VERSION "ZCU_CANFD1"

NS_ :

BS_ :

BU_ :  ASDM BBM ETC IHU ZCUD ZCUP

BO_ 1570 ZcudWpcToDhuZCUCANFD1DiagResFr : 64 ZCUD

BO_ 1554 ZcudXcuToDhuZCUCANFD1DiagResFr : 64 ZCUD

BO_ 97 ZcudZCUCANFD1Fr01 : 64 ZCUD
 SG_ ActvnOfWelcomeLi : 463|1@0+ (1,0) [0|1] "" IHU,ZCUP
 SG_ ActvnOfWelcomeLi_UB : 462|1@0+ (1,0) [0|1] "" IHU,ZCUP
 SG_ ADataRawSafe_UB : 72|1@0+ (1,0) [0|1] "" ASDM,BBM
 SG_ ADataRawSafeALat : 119|15@0- (0.0085,0.0) [-138.99200000000002|139.00050000000002] "m/s^2" ASDM,BBM
 SG_ ADataRawSafeALat1Qf : 135|2@0+ (1,0) [0|3] "" ASDM,BBM
 SG_ ADataRawSafeALgt : 151|15@0- (0.0085,0.0) [-138.99200000000002|139.00050000000002] "m/s^2" ASDM,BBM
 SG_ ADataRawSafeALgt1Qf : 133|2@0+ (1,0) [0|3] "" ASDM,BBM
 SG_ ADataRawSafeAVert : 167|15@0- (0.0085,0.0) [-138.99200000000002|139.00050000000002] "m/s^2" ASDM,BBM
 SG_ ADataRawSafeAVertQf : 183|2@0+ (1,0) [0|3] "" ASDM,BBM
 SG_ ADataRawSafeChks : 143|8@0+ (1.0,0.0) [0.0|255.0] "Unitless" ASDM,BBM
 SG_ ADataRawSafeCntr : 131|4@0+ (1.0,0.0) [0.0|15.0] "Unitless" ASDM,BBM
 SG_ ADModCtrlInhbn_UB : 176|1@0+ (1,0) [0|1] "" ASDM,IHU
 SG_ ADModCtrlInhbnADModCtrlInhbn : 195|3@0+ (1,0) [0|7] "" ASDM,IHU
 SG_ ADModCtrlInhbnChks : 191|8@0+ (1.0,0.0) [0.0|255.0] "Unitless" ASDM,IHU
 SG_ ADModCtrlInhbnCntr : 199|4@0+ (1.0,0.0) [0.0|15.0] "Unitless" ASDM,IHU
 SG_ AgDataRaw2Safe_UB : 181|1@0+ (1,0) [0|1] "" IHU
 SG_ AgDataRaw2SafeChks : 207|8@0+ (1.0,0.0) [0.0|255.0] "Unitless" IHU
 SG_ AgDataRaw2SafeCntr : 231|4@0+ (1.0,0.0) [0.0|15.0] "Unitless" IHU
 SG_ AgDataRaw2SafePitchRate : 215|16@0- (0.000244140625,0.0) [-6.0|6.0] "rad/s" IHU
 SG_ AgDataRaw2SafePitchRateQf : 227|2@0+ (1,0) [0|3] "" IHU
 SG_ AgDataRawSafe_UB : 180|1@0+ (1,0) [0|1] "" ASDM,BBM,IHU
 SG_ AgDataRawSafeChks : 239|8@0+ (1.0,0.0) [0.0|255.0] "Unitless" ASDM,BBM,IHU
 SG_ AgDataRawSafeCntr : 247|4@0+ (1.0,0.0) [0.0|15.0] "Unitless" ASDM,BBM,IHU
 SG_ AgDataRawSafeRollRate : 255|16@0- (0.000244140625,0.0) [-6.0|6.0] "rad/s" ASDM,BBM,IHU
 SG_ AgDataRawSafeRollRateQf : 243|2@0+ (1,0) [0|3] "" ASDM,BBM,IHU
 SG_ AgDataRawSafeYawRate : 271|16@0- (0.000244140625,0.0) [-6.0|6.0] "rad/s" ASDM,BBM,IHU
 SG_ AgDataRawSafeYawRateQf : 241|2@0+ (1,0) [0|3] "" ASDM,BBM,IHU
 SG_ AmbTRaw_UB : 179|1@0+ (1,0) [0|1] "" ASDM,BBM,IHU,ZCUP
 SG_ AmbTRawAmbTVal : 287|11@0+ (0.1,-70.0) [-70.0|134.70000000000002] "degC" ASDM,BBM,IHU,ZCUP
 SG_ AmbTRawQly : 292|2@0+ (1,0) [0|3] "" ASDM,BBM,IHU,ZCUP
 SG_ AsyDataWithCmpSafe_UB : 178|1@0+ (1,0) [0|1] "" ASDM,BBM,IHU
 SG_ AsyDataWithCmpSafeALat1Qf : 303|2@0+ (1,0) [0|3] "" ASDM,BBM,IHU
 SG_ AsyDataWithCmpSafeALatWithCmp : 351|15@0- (0.0085,0.0) [-138.99200000000002|139.00050000000002] "m/s^2" ASDM,BBM,IHU
 SG_ AsyDataWithCmpSafeALgt1Qf : 301|2@0+ (1,0) [0|3] "" ASDM,BBM,IHU
 SG_ AsyDataWithCmpSafeChks : 311|8@0+ (1.0,0.0) [0.0|255.0] "Unitless" ASDM,BBM,IHU
 SG_ AsyDataWithCmpSafeCntr : 299|4@0+ (1.0,0.0) [0.0|15.0] "Unitless" ASDM,BBM,IHU
 SG_ AsyDataWithCmpSafeGrdtOfALgt : 335|14@0- (0.00390625,0.0) [-30.0|30.0] "m/s^3" ASDM,BBM,IHU
 SG_ AsyDataWithCmpSafeYawRateQf : 337|2@0+ (1,0) [0|3] "" ASDM,BBM,IHU
 SG_ AsyDataWithCmpSafeYawRateWithCmp : 319|16@0- (0.000244140625,0.0) [-6.0|6.0] "rad/s" ASDM,BBM,IHU
 SG_ BodyHei : 63|15@0- (0.000062,0.0) [-0.999998|1.00006] "m" Vector__XXX
 SG_ BodyHei_UB : 64|1@0+ (1,0) [0|1] "" Vector__XXX
 SG_ BrkPedlSnsr_UB : 177|1@0+ (1,0) [0|1] "" IHU
 SG_ BrkPedlSnsrChks : 383|8@0+ (1.0,0.0) [0.0|255.0] "Unitless" IHU
 SG_ BrkPedlSnsrCntr : 391|4@0+ (1.0,0.0) [0.0|15.0] "Unitless" IHU
 SG_ BrkPedlSnsrQf : 387|2@0+ (1,0) [0|3] "" IHU
 SG_ BrkPedlSnsrSt : 385|2@0+ (1,0) [0|3] "" IHU
 SG_ BrkPedlSts : 225|1@0+ (1,0) [0|1] "" BBM,IHU
 SG_ BrkPedlSts_UB : 224|1@0+ (1,0) [0|1] "" BBM,IHU
 SG_ CarTiGlb : 399|32@0+ (0.1,0.0) [0.0|429496729.5] "s" ASDM,BBM,IHU,ZCUP
 SG_ CarTiGlb_UB : 192|1@0+ (1,0) [0|1] "" ASDM,BBM,IHU,ZCUP
 SG_ CrsCtrlOvrdn : 107|1@0+ (1,0) [0|1] "" ASDM,IHU
 SG_ CrsCtrlOvrdn_UB : 106|1@0+ (1,0) [0|1] "" ASDM,IHU
 SG_ CrsCtrlrMsg : 3|3@0+ (1,0) [0|7] "" IHU
 SG_ CrsCtrlrMsg_UB : 0|1@0+ (1,0) [0|1] "" IHU
 SG_ CrsCtrlrStbOk : 105|1@0+ (1,0) [0|1] "" IHU
 SG_ CrsCtrlrStbOk_UB : 104|1@0+ (1,0) [0|1] "" IHU
 SG_ CrsCtrlrSts : 7|3@0+ (1,0) [0|7] "" ASDM,IHU
 SG_ CrsCtrlrSts_UB : 4|1@0+ (1,0) [0|1] "" ASDM,IHU
 SG_ DmcStsRearToEsc_UB : 74|1@0+ (1,0) [0|1] "" Vector__XXX
 SG_ DmcStsRearToEscChks : 15|8@0+ (1.0,0.0) [0.0|255.0] "Unitless" Vector__XXX
 SG_ DmcStsRearToEscCntr : 23|4@0+ (1.0,0.0) [0.0|15.0] "Unitless" Vector__XXX
 SG_ DmcStsRearToEscDmcActAppTarTq : 31|16@0- (1.0,0.0) [-30000.0|30000.0] "NewtonMeter" Vector__XXX
 SG_ DmcStsRearToEscDmcSts : 19|4@0+ (1,0) [0|15] "" Vector__XXX
 SG_ DmcStsRearToEscDmcSWInfo : 47|16@0+ (1.0,0.0) [0.0|65535.0] "Unitless" Vector__XXX
 SG_ DoorDrvrLockCmd : 461|4@0+ (1,0) [0|15] "" IHU,ZCUP
 SG_ DoorDrvrLockCmd_UB : 457|1@0+ (1,0) [0|1] "" IHU,ZCUP
 SG_ DrvrDesDir_UB : 480|1@0+ (1,0) [0|1] "" ASDM,IHU
 SG_ DrvrDesDirChks : 479|8@0+ (1.0,0.0) [0.0|255.0] "Unitless" ASDM,IHU
 SG_ DrvrDesDirCntr : 487|4@0+ (1.0,0.0) [0.0|15.0] "Unitless" ASDM,IHU
 SG_ DrvrDesDirDrvrDesDir : 483|3@0+ (1,0) [0|7] "" ASDM,IHU
 SG_ DrvrGearShiftDirReq1_UB : 290|1@0+ (1,0) [0|1] "" Vector__XXX
 SG_ DrvrGearShiftDirReq1Chks : 375|8@0+ (1.0,0.0) [0.0|255.0] "Unitless" Vector__XXX
 SG_ DrvrGearShiftDirReq1Cntr : 363|4@0+ (1.0,0.0) [0.0|15.0] "Unitless" Vector__XXX
 SG_ DrvrGearShiftDirReq1DwnDwnTipAut : 364|1@0+ (1,0) [0|1] "" Vector__XXX
 SG_ DrvrGearShiftDirReq1DwnTipAut : 365|1@0+ (1,0) [0|1] "" Vector__XXX
 SG_ DrvrGearShiftDirReq1PosnAut : 366|1@0+ (1,0) [0|1] "" Vector__XXX
 SG_ DrvrGearShiftDirReq1UpTipAut : 367|1@0+ (1,0) [0|1] "" Vector__XXX
 SG_ DrvrGearShiftDirReq1UpUpTipAut : 352|1@0+ (1,0) [0|1] "" Vector__XXX
 SG_ DrvrGearShiftDirReq2_UB : 289|1@0+ (1,0) [0|1] "" Vector__XXX
 SG_ DrvrGearShiftDirReq2Chks : 455|8@0+ (1.0,0.0) [0.0|255.0] "Unitless" Vector__XXX
 SG_ DrvrGearShiftDirReq2Cntr : 443|4@0+ (1.0,0.0) [0.0|15.0] "Unitless" Vector__XXX
 SG_ DrvrGearShiftDirReq2DwnDwnTipAut : 444|1@0+ (1,0) [0|1] "" Vector__XXX
 SG_ DrvrGearShiftDirReq2DwnTipAut : 445|1@0+ (1,0) [0|1] "" Vector__XXX
 SG_ DrvrGearShiftDirReq2PosnAut : 446|1@0+ (1,0) [0|1] "" Vector__XXX
 SG_ DrvrGearShiftDirReq2UpTipAut : 447|1@0+ (1,0) [0|1] "" Vector__XXX
 SG_ DrvrGearShiftDirReq2UpUpTipAut : 432|1@0+ (1,0) [0|1] "" Vector__XXX
 SG_ EpbActrStSec : 471|3@0+ (1,0) [0|7] "" IHU
 SG_ EpbActrStSec_UB : 456|1@0+ (1,0) [0|1] "" IHU
 SG_ ExtrLiRlyPwrDwn : 468|1@0+ (1,0) [0|1] "" Vector__XXX
 SG_ ExtrLiRlyPwrDwn_UB : 467|1@0+ (1,0) [0|1] "" Vector__XXX
 SG_ GearMovmtFlg : 465|2@0+ (1,0) [0|3] "" IHU
 SG_ GearMovmtFlg_UB : 466|1@0+ (1,0) [0|1] "" IHU
 SG_ WhlMotSysModSts : 79|4@0+ (1,0) [0|15] "" IHU
 SG_ WhlMotSysModSts_UB : 75|1@0+ (1,0) [0|1] "" IHU
 SG_ WhlMotSysTqEst_UB : 73|1@0+ (1,0) [0|1] "" Vector__XXX
 SG_ WhlMotSysTqEstChks : 87|8@0+ (1.0,0.0) [0.0|255.0] "Unitless" Vector__XXX
 SG_ WhlMotSysTqEstCntr : 111|4@0+ (1.0,0.0) [0.0|15.0] "Unitless" Vector__XXX
 SG_ WhlMotSysTqEstIsgTqAct : 95|14@0+ (1.0,-8188.0) [-8188.0|8192.0] "NewtonMeter" Vector__XXX
 SG_ WhlMotSysTqEstQualityFactor : 97|2@0+ (1,0) [0|3] "" Vector__XXX

BO_ 261 ZcudZCUCANFD1Fr02 : 64 ZCUD
 SG_ ActvnStsOfRtrctrRvsbLe : 27|1@0+ (1,0) [0|1] "" Vector__XXX
 SG_ ActvnStsOfRtrctrRvsbLe_UB : 26|1@0+ (1,0) [0|1] "" Vector__XXX
 SG_ AlrmSts_UB : 14|1@0+ (1,0) [0|1] "" ASDM,IHU
 SG_ AlrmStsAlrmFailr : 1|1@0+ (1,0) [0|1] "" ASDM,IHU
 SG_ AlrmStsAlrmSt : 3|2@0+ (1,0) [0|3] "" ASDM,IHU
 SG_ AlrmStsAlrmTrgSrc : 7|4@0+ (1,0) [0|15] "" ASDM,IHU
 SG_ AlrmStsSnsrInclnFailr : 0|1@0+ (1,0) [0|1] "" ASDM,IHU
 SG_ AlrmStsSnsrIntrScanrFailr : 15|1@0+ (1,0) [0|1] "" ASDM,IHU
 SG_ BltLockStSafeAtDrvr_UB : 31|1@0+ (1,0) [0|1] "" IHU
 SG_ BltLockStSafeAtDrvrBltLockSt1 : 13|1@0+ (1,0) [0|1] "" IHU
 SG_ BltLockStSafeAtDrvrBltLockStErrSts : 12|1@0+ (1,0) [0|1] "" IHU
 SG_ BltLockStSafeAtDrvrChks : 23|8@0+ (1.0,0.0) [0.0|255.0] "Unitless" IHU
 SG_ BltLockStSafeAtDrvrCntr : 11|4@0+ (1.0,0.0) [0.0|15.0] "Unitless" IHU
 SG_ BrkPedlVal_UB : 88|1@0+ (1,0) [0|1] "" BBM,IHU
 SG_ BrkPedlValBrkPedlVal : 87|15@0+ (0.00390625,0.0) [0.0|100.0] "%" BBM,IHU
 SG_ BrkPedlValQf : 73|2@0+ (1,0) [0|3] "" BBM,IHU
 SG_ DoorDrvrSts : 75|2@0+ (1,0) [0|3] "" ASDM,BBM,IHU,ZCUP
 SG_ DoorDrvrSts_UB : 76|1@0+ (1,0) [0|1] "" ASDM,BBM,IHU,ZCUP
 SG_ DoorDrvrStsWithFacQly_UB : 99|1@0+ (1,0) [0|1] "" ASDM,BBM,IHU
 SG_ DoorDrvrStsWithFacQlyDoorSts : 103|2@0+ (1,0) [0|3] "" ASDM,BBM,IHU
 SG_ DoorDrvrStsWithFacQlyFacQly : 101|2@0+ (1,0) [0|3] "" ASDM,BBM,IHU
 SG_ DoorLeReSts : 119|2@0+ (1,0) [0|3] "" ASDM,BBM,IHU,ZCUP
 SG_ DoorLeReSts_UB : 117|1@0+ (1,0) [0|1] "" ASDM,BBM,IHU,ZCUP
 SG_ DoorPassSts : 115|2@0+ (1,0) [0|3] "" ASDM,BBM,IHU,ZCUP
 SG_ DoorPassSts_UB : 116|1@0+ (1,0) [0|1] "" ASDM,BBM,IHU,ZCUP
 SG_ DoorRiReSts : 113|2@0+ (1,0) [0|3] "" ASDM,BBM,IHU,ZCUP
 SG_ DoorRiReSts_UB : 104|1@0+ (1,0) [0|1] "" ASDM,BBM,IHU,ZCUP
 SG_ DrvrPrsntSts_UB : 143|1@0+ (1,0) [0|1] "" ASDM,BBM,IHU
 SG_ DrvrPrsntStsDrvrPrsnt : 127|2@0+ (1,0) [0|3] "" ASDM,BBM,IHU
 SG_ DrvrPrsntStsDrvrPrsntChks : 135|8@0+ (1.0,0.0) [0.0|255.0] "Unitless" ASDM,BBM,IHU
 SG_ DrvrPrsntStsDrvrPrsntCntr : 123|4@0+ (1.0,0.0) [0.0|15.0] "Unitless" ASDM,BBM,IHU
 SG_ DrvrPrsntStsDrvrPrsntQf : 125|2@0+ (1,0) [0|3] "" ASDM,BBM,IHU
 SG_ GearLvrIndcn : 55|3@0+ (1,0) [0|7] "" ASDM
 SG_ GearLvrIndcn_UB : 52|1@0+ (1,0) [0|1] "" ASDM
 SG_ GearMov : 51|2@0+ (1,0) [0|3] "" IHU
 SG_ GearMov_UB : 98|1@0+ (1,0) [0|1] "" IHU
 SG_ HoodSts : 63|2@0+ (1,0) [0|3] "" ASDM,IHU
 SG_ HoodSts_UB : 61|1@0+ (1,0) [0|1] "" ASDM,IHU
 SG_ IndcrDisp : 327|2@0+ (1,0) [0|3] "" IHU
 SG_ IndcrDisp_UB : 325|1@0+ (1,0) [0|1] "" IHU
 SG_ IndcrSts : 79|2@0+ (1,0) [0|3] "" IHU,ZCUP
 SG_ IndcrSts_UB : 77|1@0+ (1,0) [0|1] "" IHU,ZCUP
 SG_ LockgCenSts_UB : 97|1@0+ (1,0) [0|1] "" IHU,ZCUP
 SG_ LockgCenStsLockSt : 107|2@0+ (1,0) [0|3] "" IHU,ZCUP
 SG_ LockgCenStsTrigSrc : 111|4@0+ (1,0) [0|15] "" IHU,ZCUP
 SG_ LockgCenStsUpdEve : 105|1@0+ (1,0) [0|1] "" IHU,ZCUP
 SG_ LvlgDirMovmtIndcr : 71|2@0+ (1,0) [0|3] "" Vector__XXX
 SG_ LvlgDirMovmtIndcr_UB : 60|1@0+ (1,0) [0|1] "" Vector__XXX
 SG_ MirrFoldStsAtDrvr : 379|3@0+ (1,0) [0|7] "" IHU
 SG_ MirrFoldStsAtDrvr_UB : 376|1@0+ (1,0) [0|1] "" IHU
 SG_ PtBrkTq_UB : 296|1@0+ (1,0) [0|1] "" ASDM,IHU
 SG_ PtBrkTqActTot : 247|15@0- (1.0,0.0) [-16384.0|16380.0] "NewtonMeter" ASDM,IHU
 SG_ PtBrkTqActTotQf : 267|2@0+ (1,0) [0|3] "" ASDM,IHU
 SG_ PtBrkTqChks : 263|8@0+ (1.0,0.0) [0.0|255.0] "Unitless" ASDM,IHU
 SG_ PtBrkTqCntr : 271|4@0+ (1.0,0.0) [0.0|15.0] "Unitless" ASDM,IHU
 SG_ PtBrkTqQf : 265|2@0+ (1,0) [0|3] "" ASDM,IHU
 SG_ PtBrkTqReqForBrkSys : 279|15@0- (1.0,0.0) [-16384.0|16380.0] "NewtonMeter" ASDM,IHU
 SG_ PtBrkTqRgnAtAxleReAct : 295|15@0- (1.0,0.0) [-16384.0|16380.0] "NewtonMeter" ASDM,IHU
 SG_ RecOfPostImpctBrkgCfmd_UB : 313|1@0+ (1,0) [0|1] "" BBM,IHU
 SG_ RecOfPostImpctBrkgCfmdChks : 335|8@0+ (1.0,0.0) [0.0|255.0] "Unitless" BBM,IHU
 SG_ RecOfPostImpctBrkgCfmdCntr : 343|4@0+ (1.0,0.0) [0.0|15.0] "Unitless" BBM,IHU
 SG_ RecOfPostImpctBrkgCfmdCrashFrnt : 339|2@0+ (1,0) [0|3] "" BBM,IHU
 SG_ RecOfPostImpctBrkgCfmdCrashLargeAnimal : 337|2@0+ (1,0) [0|3] "" BBM,IHU
 SG_ RecOfPostImpctBrkgCfmdCrashOffroadA : 351|2@0+ (1,0) [0|3] "" BBM,IHU
 SG_ RecOfPostImpctBrkgCfmdCrashOffroadD : 349|2@0+ (1,0) [0|3] "" BBM,IHU
 SG_ RecOfPostImpctBrkgCfmdCrashOffroadRT : 347|2@0+ (1,0) [0|3] "" BBM,IHU
 SG_ RecOfPostImpctBrkgCfmdCrashOffroadRTsevere : 345|2@0+ (1,0) [0|3] "" BBM,IHU
 SG_ RecOfPostImpctBrkgCfmdCrashOz : 359|2@0+ (1,0) [0|3] "" BBM,IHU
 SG_ RecOfPostImpctBrkgCfmdCrashPed : 357|2@0+ (1,0) [0|3] "" BBM,IHU
 SG_ RecOfPostImpctBrkgCfmdCrashRe : 355|2@0+ (1,0) [0|3] "" BBM,IHU
 SG_ RecOfPostImpctBrkgCfmdCrashRollovr : 353|2@0+ (1,0) [0|3] "" BBM,IHU
 SG_ RecOfPostImpctBrkgCfmdCrashSideLe : 367|2@0+ (1,0) [0|3] "" BBM,IHU
 SG_ RecOfPostImpctBrkgCfmdCrashSideRi : 365|2@0+ (1,0) [0|3] "" BBM,IHU
 SG_ RecOfPostImpctBrkgCfmdPostImpctBrkgCfmd : 363|2@0+ (1,0) [0|3] "" BBM,IHU
 SG_ StsForRtrctrRvsbLe : 67|2@0+ (1,0) [0|3] "" Vector__XXX
 SG_ StsForRtrctrRvsbLe_UB : 69|1@0+ (1,0) [0|1] "" Vector__XXX
 SG_ SunRoofPosnSts : 324|5@0+ (1,0) [0|31] "" IHU,ZCUP
 SG_ SunRoofPosnSts_UB : 312|1@0+ (1,0) [0|1] "" IHU,ZCUP
 SG_ SuspHeiLvlIndcn : 58|3@0+ (1,0) [0|7] "" Vector__XXX
 SG_ SuspHeiLvlIndcn_UB : 59|1@0+ (1,0) [0|1] "" Vector__XXX
 SG_ TrsmParkLockd_UB : 314|1@0+ (1,0) [0|1] "" ZCUP
 SG_ TrsmParkLockdChks : 375|8@0+ (1.0,0.0) [0.0|255.0] "Unitless" ZCUP
 SG_ TrsmParkLockdCntr : 383|4@0+ (1.0,0.0) [0.0|15.0] "Unitless" ZCUP
 SG_ TrsmParkLockdTrsmParkLockd : 361|2@0+ (1,0) [0|3] "" ZCUP
 SG_ TrSts : 141|2@0+ (1,0) [0|3] "" ASDM,BBM,IHU,ZCUP
 SG_ TrSts_UB : 142|1@0+ (1,0) [0|1] "" ASDM,BBM,IHU,ZCUP
 SG_ WhlMotSysLimnIndcn : 39|16@0+ (1.0,0.0) [0.0|65535.0] "Unitless" Vector__XXX
 SG_ WhlMotSysLimnIndcn_UB : 28|1@0+ (1,0) [0|1] "" Vector__XXX

BO_ 851 ZcudZCUCANFD1Fr03 : 64 ZCUD
 SG_ BltLockStAtRowSecLe_UB : 2|1@0+ (1,0) [0|1] "" BBM,IHU,ZCUP
 SG_ BltLockStAtRowSecLeBltLockEquid : 7|1@0+ (1,0) [0|1] "" BBM,IHU,ZCUP
 SG_ BltLockStAtRowSecLeBltLockSt1 : 6|1@0+ (1,0) [0|1] "" BBM,IHU,ZCUP
 SG_ BltLockStAtRowSecLeBltLockSts : 5|1@0+ (1,0) [0|1] "" BBM,IHU,ZCUP
 SG_ BltLockStAtRowSecMid_UB : 0|1@0+ (1,0) [0|1] "" BBM,IHU,ZCUP
 SG_ BltLockStAtRowSecMidBltLockEquid : 15|1@0+ (1,0) [0|1] "" BBM,IHU,ZCUP
 SG_ BltLockStAtRowSecMidBltLockSt1 : 14|1@0+ (1,0) [0|1] "" BBM,IHU,ZCUP
 SG_ BltLockStAtRowSecMidBltLockSts : 13|1@0+ (1,0) [0|1] "" BBM,IHU,ZCUP
 SG_ BltLockStAtRowSecRi_UB : 1|1@0+ (1,0) [0|1] "" BBM,IHU,ZCUP
 SG_ BltLockStAtRowSecRiBltLockEquid : 12|1@0+ (1,0) [0|1] "" BBM,IHU,ZCUP
 SG_ BltLockStAtRowSecRiBltLockSt1 : 11|1@0+ (1,0) [0|1] "" BBM,IHU,ZCUP
 SG_ BltLockStAtRowSecRiBltLockSts : 10|1@0+ (1,0) [0|1] "" BBM,IHU,ZCUP
 SG_ BltLockStAtRowThrdLe_UB : 8|1@0+ (1,0) [0|1] "" BBM,IHU,ZCUP
 SG_ BltLockStAtRowThrdLeBltLockEquid : 23|1@0+ (1,0) [0|1] "" BBM,IHU,ZCUP
 SG_ BltLockStAtRowThrdLeBltLockSt1 : 22|1@0+ (1,0) [0|1] "" BBM,IHU,ZCUP
 SG_ BltLockStAtRowThrdLeBltLockSts : 21|1@0+ (1,0) [0|1] "" BBM,IHU,ZCUP
 SG_ BltLockStAtRowThrdRi_UB : 9|1@0+ (1,0) [0|1] "" BBM,IHU,ZCUP
 SG_ BltLockStAtRowThrdRiBltLockEquid : 20|1@0+ (1,0) [0|1] "" BBM,IHU,ZCUP
 SG_ BltLockStAtRowThrdRiBltLockSt1 : 19|1@0+ (1,0) [0|1] "" BBM,IHU,ZCUP
 SG_ BltLockStAtRowThrdRiBltLockSts : 18|1@0+ (1,0) [0|1] "" BBM,IHU,ZCUP
 SG_ BtnLockSts1_UB : 24|1@0+ (1,0) [0|1] "" IHU
 SG_ BtnLockSts1BtnSts2 : 31|3@0+ (1,0) [0|7] "" IHU
 SG_ BtnLockSts1KeyId : 28|4@0+ (1,0) [0|15] "" IHU
 SG_ BtnTrSts1_UB : 32|1@0+ (1,0) [0|1] "" IHU
 SG_ BtnTrSts1BtnSts2 : 35|3@0+ (1,0) [0|7] "" IHU
 SG_ BtnTrSts1KeyId : 39|4@0+ (1,0) [0|15] "" IHU
 SG_ BtnUnlckSts1_UB : 40|1@0+ (1,0) [0|1] "" IHU
 SG_ BtnUnlckSts1BtnSts2 : 47|3@0+ (1,0) [0|7] "" IHU
 SG_ BtnUnlckSts1KeyId : 44|4@0+ (1,0) [0|15] "" IHU
 SG_ DCChrgnHndlSts : 55|3@0+ (1,0) [0|7] "" ZCUP
 SG_ DCChrgnHndlSts_UB : 16|1@0+ (1,0) [0|1] "" ZCUP
 SG_ ULoWarn_UB : 17|1@0+ (1,0) [0|1] "" IHU
 SG_ ULoWarnChks : 63|8@0+ (1.0,0.0) [0.0|255.0] "Unitless" IHU
 SG_ ULoWarnCntr : 71|4@0+ (1.0,0.0) [0.0|15.0] "Unitless" IHU
 SG_ ULoWarnULoWarn : 67|2@0+ (1,0) [0|3] "" IHU
 SG_ UsgModDeactvnQly : 49|2@0+ (1,0) [0|3] "" BBM,IHU
 SG_ UsgModDeactvnQly_UB : 78|1@0+ (1,0) [0|1] "" BBM,IHU

BO_ 545 ZcudZCUCANFD1Fr05 : 64 ZCUD
 SG_ BltLockStAtPass_UB : 2|1@0+ (1,0) [0|1] "" BBM,IHU,ZCUP
 SG_ BltLockStAtPassBltLockSt1 : 4|1@0+ (1,0) [0|1] "" BBM,IHU,ZCUP
 SG_ BltLockStAtPassBltLockSts : 3|1@0+ (1,0) [0|1] "" BBM,IHU,ZCUP
 SG_ KeyDistncSts_UB : 77|1@0+ (1,0) [0|1] "" IHU
 SG_ KeyDistncStsKey0 : 1|10@0+ (1.0,0.0) [0.0|1023.0] "cm" IHU
 SG_ KeyDistncStsKey1 : 23|10@0+ (1.0,0.0) [0.0|1023.0] "cm" IHU
 SG_ KeyDistncStsKey2 : 25|10@0+ (1.0,0.0) [0.0|1023.0] "cm" IHU
 SG_ KeyDistncStsKey3 : 47|10@0+ (1.0,0.0) [0.0|1023.0] "cm" IHU
 SG_ KeyDistncStsKey4 : 49|10@0+ (1.0,0.0) [0.0|1023.0] "cm" IHU
 SG_ KeyDistncStsKey5 : 71|10@0+ (1.0,0.0) [0.0|1023.0] "cm" IHU
 SG_ MsgReqForRtrctrRvsbLe : 74|1@0+ (1,0) [0|1] "" Vector__XXX
 SG_ MsgReqForRtrctrRvsbLe_UB : 72|1@0+ (1,0) [0|1] "" Vector__XXX
 SG_ TDcDcCoolt : 95|8@0+ (1.0,-40.0) [-40.0|215.0] "degC" Vector__XXX
 SG_ TDcDcCoolt_UB : 80|1@0+ (1,0) [0|1] "" Vector__XXX
 SG_ TwliBriSts : 76|1@0+ (1,0) [0|1] "" ASDM,IHU,ZCUP
 SG_ TwliBriSts_UB : 75|1@0+ (1,0) [0|1] "" ASDM,IHU,ZCUP

BO_ 579 ZcudZCUCANFD1Fr06 : 64 ZCUD
 SG_ DcDcActvd : 29|1@0+ (1,0) [0|1] "" ASDM
 SG_ DcDcActvd_UB : 24|1@0+ (1,0) [0|1] "" ASDM
 SG_ HvBattSoc : 146|11@0+ (0.05,0.0) [0.0|100.0] "%" ZCUP
 SG_ HvBattSoc_UB : 147|1@0+ (1,0) [0|1] "" ZCUP
 SG_ LeFrntTireMsg_UB : 140|1@0+ (1,0) [0|1] "" IHU
 SG_ LeFrntTireMsgBattLoSt : 55|1@0+ (1,0) [0|1] "" IHU
 SG_ LeFrntTireMsgFastLoseWarnFlg : 54|1@0+ (1,0) [0|1] "" IHU
 SG_ LeFrntTireMsgMsgOldFlg : 53|1@0+ (1,0) [0|1] "" IHU
 SG_ LeFrntTireMsgP : 39|8@0+ (1.373,0.0) [0.0|350.115] "KiloPa" IHU
 SG_ LeFrntTireMsgPWarnFlg : 49|2@0+ (1,0) [0|3] "" IHU
 SG_ LeFrntTireMsgSysWarnFlg : 52|1@0+ (1,0) [0|1] "" IHU
 SG_ LeFrntTireMsgT : 47|8@0+ (1.0,-50.0) [-50.0|205.0] "degC" IHU
 SG_ LeFrntTireMsgTireFillgAssiPSts : 51|1@0+ (1,0) [0|1] "" IHU
 SG_ LeFrntTireMsgTWarnFlg : 50|1@0+ (1,0) [0|1] "" IHU
 SG_ LeReTireMsg_UB : 139|1@0+ (1,0) [0|1] "" IHU
 SG_ LeReTireMsgBattLoSt : 79|1@0+ (1,0) [0|1] "" IHU
 SG_ LeReTireMsgFastLoseWarnFlg : 78|1@0+ (1,0) [0|1] "" IHU
 SG_ LeReTireMsgMsgOldFlg : 77|1@0+ (1,0) [0|1] "" IHU
 SG_ LeReTireMsgP : 63|8@0+ (1.373,0.0) [0.0|350.115] "KiloPa" IHU
 SG_ LeReTireMsgPWarnFlg : 73|2@0+ (1,0) [0|3] "" IHU
 SG_ LeReTireMsgSysWarnFlg : 76|1@0+ (1,0) [0|1] "" IHU
 SG_ LeReTireMsgT : 71|8@0+ (1.0,-50.0) [-50.0|205.0] "degC" IHU
 SG_ LeReTireMsgTireFillgAssiPSts : 75|1@0+ (1,0) [0|1] "" IHU
 SG_ LeReTireMsgTWarnFlg : 74|1@0+ (1,0) [0|1] "" IHU
 SG_ OnBdChrgrHndlSts1 : 7|4@0+ (1,0) [0|15] "" ZCUP
 SG_ OnBdChrgrHndlSts1_UB : 3|1@0+ (1,0) [0|1] "" ZCUP
 SG_ RiFrntTireMsg_UB : 138|1@0+ (1,0) [0|1] "" IHU
 SG_ RiFrntTireMsgBattLoSt : 103|1@0+ (1,0) [0|1] "" IHU
 SG_ RiFrntTireMsgFastLoseWarnFlg : 102|1@0+ (1,0) [0|1] "" IHU
 SG_ RiFrntTireMsgMsgOldFlg : 101|1@0+ (1,0) [0|1] "" IHU
 SG_ RiFrntTireMsgP : 87|8@0+ (1.373,0.0) [0.0|350.115] "KiloPa" IHU
 SG_ RiFrntTireMsgPWarnFlg : 97|2@0+ (1,0) [0|3] "" IHU
 SG_ RiFrntTireMsgSysWarnFlg : 100|1@0+ (1,0) [0|1] "" IHU
 SG_ RiFrntTireMsgT : 95|8@0+ (1.0,-50.0) [-50.0|205.0] "degC" IHU
 SG_ RiFrntTireMsgTireFillgAssiPSts : 99|1@0+ (1,0) [0|1] "" IHU
 SG_ RiFrntTireMsgTWarnFlg : 98|1@0+ (1,0) [0|1] "" IHU
 SG_ RiReTireMsg_UB : 137|1@0+ (1,0) [0|1] "" IHU
 SG_ RiReTireMsgBattLoSt : 127|1@0+ (1,0) [0|1] "" IHU
 SG_ RiReTireMsgFastLoseWarnFlg : 126|1@0+ (1,0) [0|1] "" IHU
 SG_ RiReTireMsgMsgOldFlg : 125|1@0+ (1,0) [0|1] "" IHU
 SG_ RiReTireMsgP : 111|8@0+ (1.373,0.0) [0.0|350.115] "KiloPa" IHU
 SG_ RiReTireMsgPWarnFlg : 121|2@0+ (1,0) [0|3] "" IHU
 SG_ RiReTireMsgSysWarnFlg : 124|1@0+ (1,0) [0|1] "" IHU
 SG_ RiReTireMsgT : 119|8@0+ (1.0,-50.0) [-50.0|205.0] "degC" IHU
 SG_ RiReTireMsgTireFillgAssiPSts : 123|1@0+ (1,0) [0|1] "" IHU
 SG_ RiReTireMsgTWarnFlg : 122|1@0+ (1,0) [0|1] "" IHU
 SG_ SeatBackAngleRowFirstDrvr : 135|8@0+ (1.0,0.0) [0.0|180.0] "Deg" IHU
 SG_ SeatBackAngleRowFirstDrvr_UB : 136|1@0+ (1,0) [0|1] "" IHU

BO_ 451 ZcudZCUCANFD1Fr07 : 64 ZCUD
 SG_ AD4HeatingCircTestSts : 7|2@0+ (1,0) [0|3] "" Vector__XXX
 SG_ AD4HeatingCircTestSts_UB : 3|1@0+ (1,0) [0|1] "" Vector__XXX
 SG_ AdjSpdLimnFusnTrfcSgn : 57|1@0+ (1,0) [0|1] "" ASDM,IHU
 SG_ AdjSpdLimnFusnTrfcSgn_UB : 56|1@0+ (1,0) [0|1] "" ASDM,IHU
 SG_ EngT_UB : 61|1@0+ (1,0) [0|1] "" ZCUP
 SG_ EngTEngT : 55|8@0+ (1.0,-50.0) [-50.0|200.0] "degC" ZCUP
 SG_ EngTQf : 63|2@0+ (1,0) [0|3] "" ZCUP
 SG_ ExtrLtgSts_UB : 60|1@0+ (1,0) [0|1] "" ASDM,BBM,IHU
 SG_ ExtrLtgStsAFS : 71|2@0+ (1,0) [0|3] "" ASDM,BBM,IHU
 SG_ ExtrLtgStsAHBC : 69|2@0+ (1,0) [0|3] "" ASDM,BBM,IHU
 SG_ ExtrLtgStsAHL : 67|2@0+ (1,0) [0|3] "" ASDM,BBM,IHU
 SG_ ExtrLtgStsAllWL : 65|2@0+ (1,0) [0|3] "" ASDM,BBM,IHU
 SG_ ExtrLtgStsApproach : 79|2@0+ (1,0) [0|3] "" ASDM,BBM,IHU
 SG_ ExtrLtgStsChks : 87|8@0+ (1.0,0.0) [0.0|255.0] "Unitless" ASDM,BBM,IHU
 SG_ ExtrLtgStsCntr : 77|4@0+ (1.0,0.0) [0.0|15.0] "Unitless" ASDM,BBM,IHU
 SG_ ExtrLtgStsCornrgLi : 73|2@0+ (1,0) [0|3] "" ASDM,BBM,IHU
 SG_ ExtrLtgStsDBL : 95|2@0+ (1,0) [0|3] "" ASDM,BBM,IHU
 SG_ ExtrLtgStsDRL : 93|2@0+ (1,0) [0|3] "" ASDM,BBM,IHU
 SG_ ExtrLtgStsFlash : 91|2@0+ (1,0) [0|3] "" ASDM,BBM,IHU
 SG_ ExtrLtgStsFrntFog : 89|2@0+ (1,0) [0|3] "" ASDM,BBM,IHU
 SG_ ExtrLtgStsGoodbye : 103|2@0+ (1,0) [0|3] "" ASDM,BBM,IHU
 SG_ ExtrLtgStsHiBeam : 101|2@0+ (1,0) [0|3] "" ASDM,BBM,IHU
 SG_ ExtrLtgStsHomeSafe : 99|2@0+ (1,0) [0|3] "" ASDM,BBM,IHU
 SG_ ExtrLtgStsHWL : 97|2@0+ (1,0) [0|3] "" ASDM,BBM,IHU
 SG_ ExtrLtgStsLoBeam : 111|2@0+ (1,0) [0|3] "" ASDM,BBM,IHU
 SG_ ExtrLtgStsLtgShow : 109|2@0+ (1,0) [0|3] "" ASDM,BBM,IHU
 SG_ ExtrLtgStsPosLiFrnt : 107|2@0+ (1,0) [0|3] "" ASDM,BBM,IHU
 SG_ ExtrLtgStsPosLiRe : 105|2@0+ (1,0) [0|3] "" ASDM,BBM,IHU
 SG_ ExtrLtgStsReFog : 119|2@0+ (1,0) [0|3] "" ASDM,BBM,IHU
 SG_ ExtrLtgStsReverseLi : 117|2@0+ (1,0) [0|3] "" ASDM,BBM,IHU
 SG_ ExtrLtgStsStopLi : 115|2@0+ (1,0) [0|3] "" ASDM,BBM,IHU
 SG_ ExtrLtgStsTurnIndrLe : 113|2@0+ (1,0) [0|3] "" ASDM,BBM,IHU
 SG_ ExtrLtgStsTurnIndrRi : 127|2@0+ (1,0) [0|3] "" ASDM,BBM,IHU
 SG_ ExtrLtgStsWelcome : 125|2@0+ (1,0) [0|3] "" ASDM,BBM,IHU
 SG_ RainfallAmnt : 15|4@0+ (1,0) [0|15] "" IHU,ZCUP
 SG_ RainfallAmnt_UB : 11|1@0+ (1,0) [0|1] "" IHU,ZCUP
 SG_ RcwmLiActvd : 59|1@0+ (1,0) [0|1] "" ASDM,IHU
 SG_ RcwmLiActvd_UB : 58|1@0+ (1,0) [0|1] "" ASDM,IHU
 SG_ SteerWhlPosn_UB : 232|1@0+ (1,0) [0|1] "" Vector__XXX
 SG_ SteerWhlPosnAng : 247|12@0+ (0.01,-20.48) [-20.48|20.470000000000002] "Deg" Vector__XXX
 SG_ SteerWhlPosnX : 251|12@0+ (0.1,-204.8) [-204.8|204.7] "mm" Vector__XXX
 SG_ SwtIndcr_UB : 176|1@0+ (1,0) [0|1] "" ASDM,IHU
 SG_ SwtIndcrIndcrTypExtReq : 183|2@0+ (1,0) [0|3] "" ASDM,IHU
 SG_ SwtIndcrIndcrTypExtReqChks : 175|8@0+ (1.0,0.0) [0.0|255.0] "Unitless" ASDM,IHU
 SG_ SwtIndcrIndcrTypExtReqCntr : 181|2@0+ (1.0,0.0) [0.0|3.0] "Unitless" ASDM,IHU
 SG_ SwtIndcrIndcrTypExtReqToUpdQf : 179|2@0+ (1,0) [0|3] "" ASDM,IHU
 SG_ TiDrvgCycOff : 191|16@0+ (1.0,0.0) [0.0|65535.0] "Unitless" IHU,ZCUP
 SG_ TiDrvgCycOff_UB : 177|1@0+ (1,0) [0|1] "" IHU,ZCUP
 SG_ TrLockSts : 1|2@0+ (1,0) [0|3] "" IHU
 SG_ TrLockSts_UB : 2|1@0+ (1,0) [0|1] "" IHU
 SG_ TurnIndcrMonostable_UB : 208|1@0+ (1,0) [0|1] "" ASDM,IHU
 SG_ TurnIndcrMonostableChks : 207|8@0+ (1.0,0.0) [0.0|255.0] "Unitless" ASDM,IHU
 SG_ TurnIndcrMonostableCntr : 215|2@0+ (1.0,0.0) [0.0|3.0] "Unitless" ASDM,IHU
 SG_ TurnIndcrMonostableQf : 213|2@0+ (1,0) [0|3] "" ASDM,IHU
 SG_ TurnIndcrMonostableTurnIndcrMonostable : 211|3@0+ (1,0) [0|7] "" ASDM,IHU
 SG_ TwliBriRaw_UB : 233|1@0+ (1,0) [0|1] "" ASDM,IHU
 SG_ TwliBriRawQf : 223|2@0+ (1,0) [0|3] "" ASDM,IHU
 SG_ TwliBriRawTwliBriRaw : 221|14@0+ (1.0,0.0) [0.0|10000.0] "Unitless" ASDM,IHU
 SG_ VehParkNotActvd : 5|1@0+ (1,0) [0|1] "" BBM,IHU
 SG_ VehParkNotActvd_UB : 4|1@0+ (1,0) [0|1] "" BBM,IHU
 SG_ WipgInfo_UB : 234|1@0+ (1,0) [0|1] "" ASDM,IHU,ZCUP
 SG_ WipgInfoWipgSpdInfo : 239|3@0+ (1,0) [0|7] "" ASDM,IHU,ZCUP
 SG_ WipgInfoWiprActv : 236|1@0+ (1,0) [0|1] "" ASDM,IHU,ZCUP
 SG_ WipgInfoWiprInWipgAr : 235|1@0+ (1,0) [0|1] "" ASDM,IHU,ZCUP

BO_ 867 ZcudZCUCANFD1Fr08 : 64 ZCUD
 SG_ JID_UB : 3|1@0+ (1,0) [0|1] "" BBM,IHU
 SG_ JIDByte0 : 15|8@0+ (1.0,0.0) [0.0|255.0] "Unitless" BBM,IHU
 SG_ JIDByte1 : 23|8@0+ (1.0,0.0) [0.0|255.0] "Unitless" BBM,IHU
 SG_ JIDByte2 : 31|8@0+ (1.0,0.0) [0.0|255.0] "Unitless" BBM,IHU
 SG_ JIDByte3 : 39|8@0+ (1.0,0.0) [0.0|255.0] "Unitless" BBM,IHU
 SG_ JIDByte4 : 47|8@0+ (1.0,0.0) [0.0|255.0] "Unitless" BBM,IHU
 SG_ JIDByte5 : 55|8@0+ (1.0,0.0) [0.0|255.0] "Unitless" BBM,IHU
 SG_ JIDByte6 : 63|8@0+ (1.0,0.0) [0.0|255.0] "Unitless" BBM,IHU
 SG_ JIDByte7 : 71|8@0+ (1.0,0.0) [0.0|255.0] "Unitless" BBM,IHU
 SG_ OnBdChrgrCooltT : 79|8@0+ (1.0,-40.0) [-40.0|215.0] "degC" Vector__XXX
 SG_ OnBdChrgrCooltT_UB : 2|1@0+ (1,0) [0|1] "" Vector__XXX

BO_ 931 ZcudZCUCANFD1Fr09 : 64 ZCUD
 SG_ DispHvBattLvlOfChrg : 57|10@0+ (0.1,0.0) [0.0|102.30000000000001] "%" ZCUP
 SG_ DispHvBattLvlOfChrg_UB : 58|1@0+ (1,0) [0|1] "" ZCUP
 SG_ PassAirbSts : 7|1@0+ (1,0) [0|1] "" Vector__XXX
 SG_ PassAirbSts_UB : 6|1@0+ (1,0) [0|1] "" Vector__XXX
 SG_ VehBattU_UB : 59|1@0+ (1,0) [0|1] "" ASDM,BBM,IHU,ZCUP
 SG_ VehBattUSysU : 15|8@0+ (0.1,0.0) [0.0|25.0] "Volt" ASDM,BBM,IHU,ZCUP
 SG_ VehBattUSysUQf : 1|2@0+ (1,0) [0|3] "" ASDM,BBM,IHU,ZCUP

BO_ 83 ZcudZCUCANFD1Fr10 : 64 ZCUD
 SG_ AccrPedlRat_UB : 223|1@0+ (1,0) [0|1] "" ASDM
 SG_ AccrPedlRatAccrPedlRat : 222|15@0+ (0.00390625,0.0) [0.0|100.0] "%" ASDM
 SG_ AccrPedlRatChks : 239|8@0+ (1.0,0.0) [0.0|255.0] "Unitless" ASDM
 SG_ AccrPedlRatCntr : 247|4@0+ (1.0,0.0) [0.0|15.0] "Unitless" ASDM
 SG_ BltLockStAtDrvr_UB : 25|1@0+ (1,0) [0|1] "" ASDM,IHU,ZCUP
 SG_ BltLockStAtDrvrBltLockSt1 : 27|1@0+ (1,0) [0|1] "" ASDM,IHU,ZCUP
 SG_ BltLockStAtDrvrBltLockSts : 26|1@0+ (1,0) [0|1] "" ASDM,IHU,ZCUP
 SG_ DoorDrvrLockSts : 427|2@0+ (1,0) [0|3] "" ASDM,IHU
 SG_ DoorDrvrLockSts_UB : 425|1@0+ (1,0) [0|1] "" ASDM,IHU
 SG_ DoorLeReLockSts : 439|2@0+ (1,0) [0|3] "" ASDM,IHU
 SG_ DoorLeReLockSts_UB : 424|1@0+ (1,0) [0|1] "" ASDM,IHU
 SG_ DrvrGearShiftParkReq_UB : 8|1@0+ (1,0) [0|1] "" Vector__XXX
 SG_ DrvrGearShiftParkReq1 : 9|1@0+ (1,0) [0|1] "" Vector__XXX
 SG_ DrvrGearShiftParkReqChks : 7|8@0+ (1.0,0.0) [0.0|255.0] "Unitless" Vector__XXX
 SG_ DrvrGearShiftParkReqCntr : 15|4@0+ (1.0,0.0) [0.0|15.0] "Unitless" Vector__XXX
 SG_ DrvrGearShiftParkReqSts : 11|2@0+ (1,0) [0|3] "" Vector__XXX
 SG_ EngSt1WdSts_UB : 24|1@0+ (1,0) [0|1] "" ASDM,ZCUP
 SG_ EngSt1WdStsChks : 39|8@0+ (1.0,0.0) [0.0|255.0] "Unitless" ASDM,ZCUP
 SG_ EngSt1WdStsCntr : 47|4@0+ (1.0,0.0) [0.0|15.0] "Unitless" ASDM,ZCUP
 SG_ EngSt1WdStsEngSt1WdSts : 43|4@0+ (1,0) [0|15] "" ASDM,ZCUP
 SG_ LcmaLedStsDrvrSide : 437|1@0+ (1,0) [0|1] "" ASDM,IHU
 SG_ LcmaLedStsDrvrSide_UB : 436|1@0+ (1,0) [0|1] "" ASDM,IHU
 SG_ PinionSteerAgGroup_UB : 105|1@0+ (1,0) [0|1] "" IHU
 SG_ PinionSteerAgGroupChks : 55|8@0+ (1.0,0.0) [0.0|255.0] "Unitless" IHU
 SG_ PinionSteerAgGroupCntr : 111|4@0+ (1.0,0.0) [0.0|15.0] "Unitless" IHU
 SG_ PinionSteerAgGroupPinionSteerAg1 : 95|15@0- (0.0009765625,0.0) [-14.5|14.5] "rad" IHU
 SG_ PinionSteerAgGroupPinionSteerAg1Qf : 65|2@0+ (1,0) [0|3] "" IHU
 SG_ PinionSteerAgGroupPinionSteerAgSpd1 : 63|14@0- (0.0078125,0.0) [-50.0|50.0] "rad/s" IHU
 SG_ PinionSteerAgGroupPinionSteerAgSpd1Qf : 81|2@0+ (1,0) [0|3] "" IHU
 SG_ PinionSteerAgGroupSteerWhlTq : 79|14@0- (0.00390625,0.0) [-30.0|30.0] "NewtonMeter" IHU
 SG_ PinionSteerAgGroupSteerWhlTqQf : 107|2@0+ (1,0) [0|3] "" IHU
 SG_ RecOfPostImpctBrkgSuspc_UB : 288|1@0+ (1,0) [0|1] "" BBM,IHU
 SG_ RecOfPostImpctBrkgSuspcChks : 287|8@0+ (1.0,0.0) [0.0|255.0] "Unitless" BBM,IHU
 SG_ RecOfPostImpctBrkgSuspcCntr : 295|4@0+ (1.0,0.0) [0.0|15.0] "Unitless" BBM,IHU
 SG_ RecOfPostImpctBrkgSuspcSuspcPostImpctBrkg : 291|2@0+ (1,0) [0|3] "" BBM,IHU
 SG_ SuspPosnVertLe1_UB : 163|1@0+ (1,0) [0|1] "" Vector__XXX
 SG_ SuspPosnVertLe1Chks : 127|8@0+ (1.0,0.0) [0.0|255.0] "Unitless" Vector__XXX
 SG_ SuspPosnVertLe1Frnt : 135|15@0- (0.000062,0.0) [-0.999998|1.00006] "m" Vector__XXX
 SG_ SuspPosnVertLe1FrntQf : 167|2@0+ (1,0) [0|3] "" Vector__XXX
 SG_ SuspPosnVertLe1Re : 151|15@0- (0.000062,0.0) [-0.999998|1.00006] "m" Vector__XXX
 SG_ SuspPosnVertLe1ReQf : 165|2@0+ (1,0) [0|3] "" Vector__XXX
 SG_ SuspPosnVertRi1_UB : 162|1@0+ (1,0) [0|1] "" Vector__XXX
 SG_ SuspPosnVertRi1SuspPosnVertRiChks : 175|8@0+ (1.0,0.0) [0.0|255.0] "Unitless" Vector__XXX
 SG_ SuspPosnVertRi1SuspPosnVertRiFrnt : 183|15@0- (0.000062,0.0) [-0.999998|1.00006] "m" Vector__XXX
 SG_ SuspPosnVertRi1SuspPosnVertRiFrntQf : 215|2@0+ (1,0) [0|3] "" Vector__XXX
 SG_ SuspPosnVertRi1SuspPosnVertRiRe : 199|15@0- (0.000062,0.0) [-0.999998|1.00006] "m" Vector__XXX
 SG_ SuspPosnVertRi1SuspPosnVertRiReQf : 213|2@0+ (1,0) [0|3] "" Vector__XXX
 SG_ VehModMngtGlbSafe1_UB : 376|1@0+ (1,0) [0|1] "" ASDM,IHU,ZCUP
 SG_ VehModMngtGlbSafe1CarModSts1 : 383|3@0+ (1,0) [0|7] "" ASDM,IHU,ZCUP
 SG_ VehModMngtGlbSafe1CarModSubtypWdCarModSubtyp : 380|3@0+ (1.0,0.0) [0.0|7.0] "Unitless" ASDM,IHU,ZCUP
 SG_ VehModMngtGlbSafe1Chks : 351|8@0+ (1.0,0.0) [0.0|255.0] "Unitless" ASDM,IHU,ZCUP
 SG_ VehModMngtGlbSafe1Cntr : 359|4@0+ (1.0,0.0) [0.0|15.0] "Unitless" ASDM,IHU,ZCUP
 SG_ VehModMngtGlbSafe1EgyLvlElecMai : 355|4@0+ (1.0,0.0) [0.0|15.0] "Unitless" ASDM,IHU,ZCUP
 SG_ VehModMngtGlbSafe1EgyLvlElecSubtyp : 367|4@0+ (1.0,0.0) [0.0|15.0] "Unitless" ASDM,IHU,ZCUP
 SG_ VehModMngtGlbSafe1FltEgyCnsWdSts : 377|1@0+ (1,0) [0|1] "" ASDM,IHU,ZCUP
 SG_ VehModMngtGlbSafe1PwrLvlElecMai : 363|4@0+ (1.0,0.0) [0.0|15.0] "Unitless" ASDM,IHU,ZCUP
 SG_ VehModMngtGlbSafe1PwrLvlElecSubtyp : 375|4@0+ (1.0,0.0) [0.0|15.0] "Unitless" ASDM,IHU,ZCUP
 SG_ VehModMngtGlbSafe1UsgModSts : 371|4@0+ (1,0) [0|15] "" ASDM,IHU,ZCUP
 SG_ VehTiAndData_UB : 289|1@0+ (1,0) [0|1] "" ASDM,IHU,ZCUP
 SG_ VehTiAndDataDataValid : 391|1@0+ (1,0) [0|1] "" ASDM,IHU,ZCUP
 SG_ VehTiAndDataDay : 415|5@0+ (1.0,0.0) [1.0|31.0] "Days" ASDM,IHU,ZCUP
 SG_ VehTiAndDataHr1 : 423|5@0+ (1.0,0.0) [0.0|23.0] "hours" ASDM,IHU,ZCUP
 SG_ VehTiAndDataMins1 : 399|6@0+ (1.0,0.0) [0.0|59.0] "Mins" ASDM,IHU,ZCUP
 SG_ VehTiAndDataMth1 : 431|4@0+ (1.0,0.0) [1.0|12.0] "Month" ASDM,IHU,ZCUP
 SG_ VehTiAndDataSec1 : 407|6@0+ (1.0,0.0) [0.0|59.0] "s" ASDM,IHU,ZCUP
 SG_ VehTiAndDataYr1 : 390|7@0+ (1.0,0.0) [0.0|99.0] "Year" ASDM,IHU,ZCUP
 SG_ WinPosnStsAtDrvr : 447|5@0+ (1,0) [0|31] "" IHU,ZCUP
 SG_ WinPosnStsAtDrvr_UB : 435|1@0+ (1,0) [0|1] "" IHU,ZCUP
 SG_ WinPosnStsAtReLe : 455|5@0+ (1,0) [0|31] "" IHU,ZCUP
 SG_ WinPosnStsAtReLe_UB : 434|1@0+ (1,0) [0|1] "" IHU,ZCUP

BO_ 837 ZcudZCUCANFD1Fr11 : 64 ZCUD
 SG_ EPBLockMgrReq_UB : 109|1@0+ (1,0) [0|1] "" BBM
 SG_ EPBLockMgrReqCmd : 111|2@0+ (1,0) [0|3] "" BBM
 SG_ EPBLockMgrReqData0 : 55|8@0+ (1.0,0.0) [0.0|255.0] "Unitless" BBM
 SG_ EPBLockMgrReqData1 : 63|8@0+ (1.0,0.0) [0.0|255.0] "Unitless" BBM
 SG_ EPBLockMgrReqData2 : 71|8@0+ (1.0,0.0) [0.0|255.0] "Unitless" BBM
 SG_ EPBLockMgrReqData3 : 79|8@0+ (1.0,0.0) [0.0|255.0] "Unitless" BBM
 SG_ EPBLockMgrReqData4 : 87|8@0+ (1.0,0.0) [0.0|255.0] "Unitless" BBM
 SG_ EPBLockMgrReqData5 : 95|8@0+ (1.0,0.0) [0.0|255.0] "Unitless" BBM
 SG_ EPBLockMgrReqData6 : 103|8@0+ (1.0,0.0) [0.0|255.0] "Unitless" BBM
 SG_ TiAndDateIndcn_UB : 7|1@0+ (1,0) [0|1] "" ASDM,BBM,IHU,ZCUP
 SG_ TiAndDateIndcnDataValid : 6|1@0+ (1,0) [0|1] "" ASDM,BBM,IHU,ZCUP
 SG_ TiAndDateIndcnDay : 28|5@0+ (1.0,0.0) [1.0|31.0] "Days" ASDM,BBM,IHU,ZCUP
 SG_ TiAndDateIndcnHr1 : 20|5@0+ (1.0,0.0) [0.0|23.0] "hours" ASDM,BBM,IHU,ZCUP
 SG_ TiAndDateIndcnMins1 : 13|6@0+ (1.0,0.0) [0.0|59.0] "Mins" ASDM,BBM,IHU,ZCUP
 SG_ TiAndDateIndcnMth1 : 35|4@0+ (1.0,0.0) [1.0|12.0] "Month" ASDM,BBM,IHU,ZCUP
 SG_ TiAndDateIndcnSec1 : 5|6@0+ (1.0,0.0) [0.0|59.0] "s" ASDM,BBM,IHU,ZCUP
 SG_ TiAndDateIndcnYr1 : 46|7@0+ (1.0,0.0) [0.0|99.0] "Year" ASDM,BBM,IHU,ZCUP

BO_ 1347 ZCUDZCUCANFD1VFCVectorFr : 8 ZCUD
 SG_ VFCVectorZCUDMBlockID : 1|2@0+ (1.0,0.0) [0.0|3.0] "Unitless" Vector__XXX
 SG_ VFCVectorZCUDMVFCid0 : 2|1@0+ (1,0) [0|1] "" Vector__XXX
 SG_ VFCVectorZCUDMVFCid1 : 3|1@0+ (1,0) [0|1] "" Vector__XXX
 SG_ VFCVectorZCUDMVFCid10 : 12|1@0+ (1,0) [0|1] "" Vector__XXX
 SG_ VFCVectorZCUDMVFCid11 : 13|1@0+ (1,0) [0|1] "" Vector__XXX
 SG_ VFCVectorZCUDMVFCid12 : 14|1@0+ (1,0) [0|1] "" Vector__XXX
 SG_ VFCVectorZCUDMVFCid13 : 15|1@0+ (1,0) [0|1] "" Vector__XXX
 SG_ VFCVectorZCUDMVFCid14 : 16|1@0+ (1,0) [0|1] "" Vector__XXX
 SG_ VFCVectorZCUDMVFCid15 : 17|1@0+ (1,0) [0|1] "" Vector__XXX
 SG_ VFCVectorZCUDMVFCid16 : 18|1@0+ (1,0) [0|1] "" Vector__XXX
 SG_ VFCVectorZCUDMVFCid17 : 19|1@0+ (1,0) [0|1] "" Vector__XXX
 SG_ VFCVectorZCUDMVFCid18 : 20|1@0+ (1,0) [0|1] "" Vector__XXX
 SG_ VFCVectorZCUDMVFCid19 : 21|1@0+ (1,0) [0|1] "" Vector__XXX
 SG_ VFCVectorZCUDMVFCid2 : 4|1@0+ (1,0) [0|1] "" Vector__XXX
 SG_ VFCVectorZCUDMVFCid20 : 22|1@0+ (1,0) [0|1] "" Vector__XXX
 SG_ VFCVectorZCUDMVFCid21 : 23|1@0+ (1,0) [0|1] "" Vector__XXX
 SG_ VFCVectorZCUDMVFCid22 : 24|1@0+ (1,0) [0|1] "" Vector__XXX
 SG_ VFCVectorZCUDMVFCid23 : 25|1@0+ (1,0) [0|1] "" Vector__XXX
 SG_ VFCVectorZCUDMVFCid24 : 26|1@0+ (1,0) [0|1] "" Vector__XXX
 SG_ VFCVectorZCUDMVFCid25 : 27|1@0+ (1,0) [0|1] "" Vector__XXX
 SG_ VFCVectorZCUDMVFCid26 : 28|1@0+ (1,0) [0|1] "" Vector__XXX
 SG_ VFCVectorZCUDMVFCid27 : 29|1@0+ (1,0) [0|1] "" Vector__XXX
 SG_ VFCVectorZCUDMVFCid28 : 30|1@0+ (1,0) [0|1] "" Vector__XXX
 SG_ VFCVectorZCUDMVFCid29 : 31|1@0+ (1,0) [0|1] "" Vector__XXX
 SG_ VFCVectorZCUDMVFCid3 : 5|1@0+ (1,0) [0|1] "" Vector__XXX
 SG_ VFCVectorZCUDMVFCid30 : 32|1@0+ (1,0) [0|1] "" Vector__XXX
 SG_ VFCVectorZCUDMVFCid31 : 33|1@0+ (1,0) [0|1] "" Vector__XXX
 SG_ VFCVectorZCUDMVFCid32 : 34|1@0+ (1,0) [0|1] "" Vector__XXX
 SG_ VFCVectorZCUDMVFCid33 : 35|1@0+ (1,0) [0|1] "" Vector__XXX
 SG_ VFCVectorZCUDMVFCid34 : 36|1@0+ (1,0) [0|1] "" Vector__XXX
 SG_ VFCVectorZCUDMVFCid35 : 37|1@0+ (1,0) [0|1] "" Vector__XXX
 SG_ VFCVectorZCUDMVFCid36 : 38|1@0+ (1,0) [0|1] "" Vector__XXX
 SG_ VFCVectorZCUDMVFCid37 : 39|1@0+ (1,0) [0|1] "" Vector__XXX
 SG_ VFCVectorZCUDMVFCid38 : 40|1@0+ (1,0) [0|1] "" Vector__XXX
 SG_ VFCVectorZCUDMVFCid39 : 41|1@0+ (1,0) [0|1] "" Vector__XXX
 SG_ VFCVectorZCUDMVFCid4 : 6|1@0+ (1,0) [0|1] "" Vector__XXX
 SG_ VFCVectorZCUDMVFCid40 : 42|1@0+ (1,0) [0|1] "" Vector__XXX
 SG_ VFCVectorZCUDMVFCid41 : 43|1@0+ (1,0) [0|1] "" Vector__XXX
 SG_ VFCVectorZCUDMVFCid42 : 44|1@0+ (1,0) [0|1] "" Vector__XXX
 SG_ VFCVectorZCUDMVFCid43 : 45|1@0+ (1,0) [0|1] "" Vector__XXX
 SG_ VFCVectorZCUDMVFCid44 : 46|1@0+ (1,0) [0|1] "" Vector__XXX
 SG_ VFCVectorZCUDMVFCid45 : 47|1@0+ (1,0) [0|1] "" Vector__XXX
 SG_ VFCVectorZCUDMVFCid46 : 48|1@0+ (1,0) [0|1] "" Vector__XXX
 SG_ VFCVectorZCUDMVFCid47 : 49|1@0+ (1,0) [0|1] "" Vector__XXX
 SG_ VFCVectorZCUDMVFCid48 : 50|1@0+ (1,0) [0|1] "" Vector__XXX
 SG_ VFCVectorZCUDMVFCid49 : 51|1@0+ (1,0) [0|1] "" Vector__XXX
 SG_ VFCVectorZCUDMVFCid5 : 7|1@0+ (1,0) [0|1] "" Vector__XXX
 SG_ VFCVectorZCUDMVFCid50 : 52|1@0+ (1,0) [0|1] "" Vector__XXX
 SG_ VFCVectorZCUDMVFCid51 : 53|1@0+ (1,0) [0|1] "" Vector__XXX
 SG_ VFCVectorZCUDMVFCid52 : 54|1@0+ (1,0) [0|1] "" Vector__XXX
 SG_ VFCVectorZCUDMVFCid53 : 55|1@0+ (1,0) [0|1] "" Vector__XXX
 SG_ VFCVectorZCUDMVFCid54 : 56|1@0+ (1,0) [0|1] "" Vector__XXX
 SG_ VFCVectorZCUDMVFCid55 : 57|1@0+ (1,0) [0|1] "" Vector__XXX
 SG_ VFCVectorZCUDMVFCid56 : 58|1@0+ (1,0) [0|1] "" Vector__XXX
 SG_ VFCVectorZCUDMVFCid57 : 59|1@0+ (1,0) [0|1] "" Vector__XXX
 SG_ VFCVectorZCUDMVFCid58 : 60|1@0+ (1,0) [0|1] "" Vector__XXX
 SG_ VFCVectorZCUDMVFCid59 : 61|1@0+ (1,0) [0|1] "" Vector__XXX
 SG_ VFCVectorZCUDMVFCid6 : 8|1@0+ (1,0) [0|1] "" Vector__XXX
 SG_ VFCVectorZCUDMVFCid60 : 62|1@0+ (1,0) [0|1] "" Vector__XXX
 SG_ VFCVectorZCUDMVFCid61 : 63|1@0+ (1,0) [0|1] "" Vector__XXX
 SG_ VFCVectorZCUDMVFCid7 : 9|1@0+ (1,0) [0|1] "" Vector__XXX
 SG_ VFCVectorZCUDMVFCid8 : 10|1@0+ (1,0) [0|1] "" Vector__XXX
 SG_ VFCVectorZCUDMVFCid9 : 11|1@0+ (1,0) [0|1] "" Vector__XXX

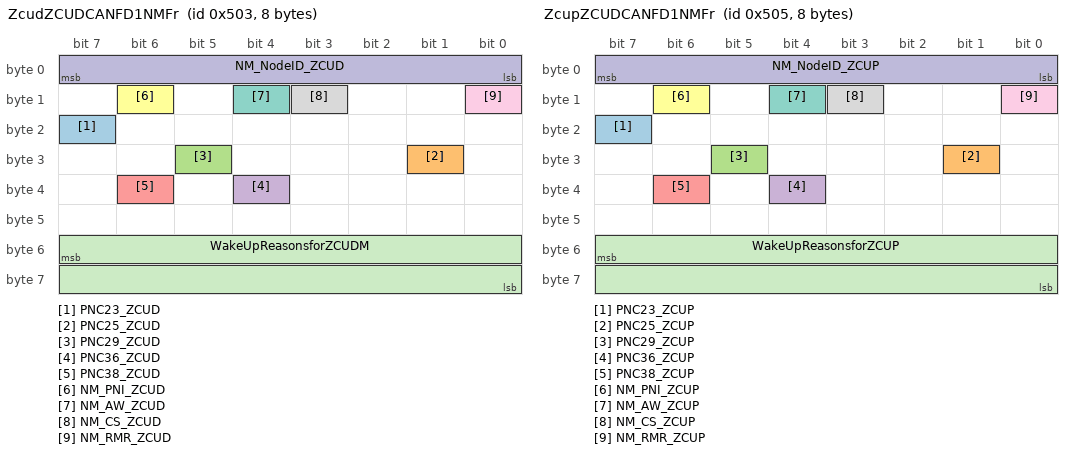
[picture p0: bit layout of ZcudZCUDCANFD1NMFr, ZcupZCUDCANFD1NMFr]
BO_ 1283 ZcudZCUDCANFD1NMFr : 8 ZCUD
 SG_ PNC23_ZCUD : 23|1@0+ (1,0) [0|0] "" Vector__XXX
 SG_ PNC25_ZCUD : 25|1@0+ (1,0) [0|0] "" Vector__XXX
 SG_ PNC29_ZCUD : 29|1@0+ (1,0) [0|0] "" Vector__XXX
 SG_ PNC36_ZCUD : 36|1@0+ (1,0) [0|0] "" Vector__XXX
 SG_ PNC38_ZCUD : 38|1@0+ (1,0) [0|0] "" Vector__XXX
 SG_ NM_PNI_ZCUD : 14|1@0+ (1,0) [0|0] "" Vector__XXX
 SG_ NM_AW_ZCUD : 12|1@0+ (1,0) [0|0] "" Vector__XXX
 SG_ NM_CS_ZCUD : 11|1@0+ (1,0) [0|0] "" Vector__XXX
 SG_ NM_RMR_ZCUD : 8|1@0+ (1,0) [0|0] "" Vector__XXX
 SG_ NM_NodeID_ZCUD : 7|8@0+ (1,0) [0|0] "" Vector__XXX

 SG_ WakeUpReasonsforZCUDM : 55|16@0+ (1,0) [0|65535] "" Vector__XXX

BO_ 530 ZcupZCUCANFD1Fr01 : 64 ZCUP
 SG_ LcmaLedStsPassSide : 15|1@0+ (1,0) [0|1] "" ASDM,IHU
 SG_ LcmaLedStsPassSide_UB : 9|1@0+ (1,0) [0|1] "" ASDM,IHU
 SG_ MirrFoldStsAtPass : 2|3@0+ (1,0) [0|7] "" IHU,ZCUD
 SG_ MirrFoldStsAtPass_UB : 8|1@0+ (1,0) [0|1] "" IHU,ZCUD
 SG_ WinPosnStsAtPass : 14|5@0+ (1,0) [0|31] "" IHU,ZCUD
 SG_ WinPosnStsAtPass_UB : 31|1@0+ (1,0) [0|1] "" IHU,ZCUD
 SG_ WinPosnStsAtReRi : 23|5@0+ (1,0) [0|31] "" IHU,ZCUD
 SG_ WinPosnStsAtReRi_UB : 30|1@0+ (1,0) [0|1] "" IHU,ZCUD

BO_ 271 ZcupZCUCANFD1Fr02 : 64 ZCUP
 SG_ DoorPassLockSts : 7|2@0+ (1,0) [0|3] "" ASDM,IHU,ZCUD
 SG_ DoorPassLockSts_UB : 5|1@0+ (1,0) [0|1] "" ASDM,IHU,ZCUD
 SG_ DoorRiReLockSts : 3|2@0+ (1,0) [0|3] "" ASDM,IHU,ZCUD
 SG_ DoorRiReLockSts_UB : 4|1@0+ (1,0) [0|1] "" ASDM,IHU,ZCUD
 SG_ PassSeatSnsrSts2 : 1|2@0+ (1,0) [0|3] "" IHU,ZCUD
 SG_ PassSeatSnsrSts2_UB : 15|1@0+ (1,0) [0|1] "" IHU,ZCUD
 SG_ PassSeatSts2 : 14|2@0+ (1,0) [0|3] "" IHU,ZCUD
 SG_ PassSeatSts2_UB : 12|1@0+ (1,0) [0|1] "" IHU,ZCUD

BO_ 1349 ZcupZCUCANFD1VFCVectorFr : 8 ZCUP
 SG_ VFCVectorZCUPBlockID : 1|2@0+ (1.0,0.0) [0.0|3.0] "Unitless" Vector__XXX
 SG_ VFCVectorZCUPVFCid0 : 2|1@0+ (1,0) [0|1] "" Vector__XXX
 SG_ VFCVectorZCUPVFCid1 : 3|1@0+ (1,0) [0|1] "" Vector__XXX
 SG_ VFCVectorZCUPVFCid10 : 12|1@0+ (1,0) [0|1] "" Vector__XXX
 SG_ VFCVectorZCUPVFCid11 : 13|1@0+ (1,0) [0|1] "" Vector__XXX
 SG_ VFCVectorZCUPVFCid12 : 14|1@0+ (1,0) [0|1] "" Vector__XXX
 SG_ VFCVectorZCUPVFCid13 : 15|1@0+ (1,0) [0|1] "" Vector__XXX
 SG_ VFCVectorZCUPVFCid14 : 16|1@0+ (1,0) [0|1] "" Vector__XXX
 SG_ VFCVectorZCUPVFCid15 : 17|1@0+ (1,0) [0|1] "" Vector__XXX
 SG_ VFCVectorZCUPVFCid16 : 18|1@0+ (1,0) [0|1] "" Vector__XXX
 SG_ VFCVectorZCUPVFCid17 : 19|1@0+ (1,0) [0|1] "" Vector__XXX
 SG_ VFCVectorZCUPVFCid18 : 20|1@0+ (1,0) [0|1] "" Vector__XXX
 SG_ VFCVectorZCUPVFCid19 : 21|1@0+ (1,0) [0|1] "" Vector__XXX
 SG_ VFCVectorZCUPVFCid2 : 4|1@0+ (1,0) [0|1] "" Vector__XXX
 SG_ VFCVectorZCUPVFCid20 : 22|1@0+ (1,0) [0|1] "" Vector__XXX
 SG_ VFCVectorZCUPVFCid21 : 23|1@0+ (1,0) [0|1] "" Vector__XXX
 SG_ VFCVectorZCUPVFCid22 : 24|1@0+ (1,0) [0|1] "" Vector__XXX
 SG_ VFCVectorZCUPVFCid23 : 25|1@0+ (1,0) [0|1] "" Vector__XXX
 SG_ VFCVectorZCUPVFCid24 : 26|1@0+ (1,0) [0|1] "" Vector__XXX
 SG_ VFCVectorZCUPVFCid25 : 27|1@0+ (1,0) [0|1] "" Vector__XXX
 SG_ VFCVectorZCUPVFCid26 : 28|1@0+ (1,0) [0|1] "" Vector__XXX
 SG_ VFCVectorZCUPVFCid27 : 29|1@0+ (1,0) [0|1] "" Vector__XXX
 SG_ VFCVectorZCUPVFCid28 : 30|1@0+ (1,0) [0|1] "" Vector__XXX
 SG_ VFCVectorZCUPVFCid29 : 31|1@0+ (1,0) [0|1] "" Vector__XXX
 SG_ VFCVectorZCUPVFCid3 : 5|1@0+ (1,0) [0|1] "" Vector__XXX
 SG_ VFCVectorZCUPVFCid30 : 32|1@0+ (1,0) [0|1] "" Vector__XXX
 SG_ VFCVectorZCUPVFCid31 : 33|1@0+ (1,0) [0|1] "" Vector__XXX
 SG_ VFCVectorZCUPVFCid32 : 34|1@0+ (1,0) [0|1] "" Vector__XXX
 SG_ VFCVectorZCUPVFCid33 : 35|1@0+ (1,0) [0|1] "" Vector__XXX
 SG_ VFCVectorZCUPVFCid34 : 36|1@0+ (1,0) [0|1] "" Vector__XXX
 SG_ VFCVectorZCUPVFCid35 : 37|1@0+ (1,0) [0|1] "" Vector__XXX
 SG_ VFCVectorZCUPVFCid36 : 38|1@0+ (1,0) [0|1] "" Vector__XXX
 SG_ VFCVectorZCUPVFCid37 : 39|1@0+ (1,0) [0|1] "" Vector__XXX
 SG_ VFCVectorZCUPVFCid38 : 40|1@0+ (1,0) [0|1] "" Vector__XXX
 SG_ VFCVectorZCUPVFCid39 : 41|1@0+ (1,0) [0|1] "" Vector__XXX
 SG_ VFCVectorZCUPVFCid4 : 6|1@0+ (1,0) [0|1] "" Vector__XXX
 SG_ VFCVectorZCUPVFCid40 : 42|1@0+ (1,0) [0|1] "" Vector__XXX
 SG_ VFCVectorZCUPVFCid41 : 43|1@0+ (1,0) [0|1] "" Vector__XXX
 SG_ VFCVectorZCUPVFCid42 : 44|1@0+ (1,0) [0|1] "" Vector__XXX
 SG_ VFCVectorZCUPVFCid43 : 45|1@0+ (1,0) [0|1] "" Vector__XXX
 SG_ VFCVectorZCUPVFCid44 : 46|1@0+ (1,0) [0|1] "" Vector__XXX
 SG_ VFCVectorZCUPVFCid45 : 47|1@0+ (1,0) [0|1] "" Vector__XXX
 SG_ VFCVectorZCUPVFCid46 : 48|1@0+ (1,0) [0|1] "" Vector__XXX
 SG_ VFCVectorZCUPVFCid47 : 49|1@0+ (1,0) [0|1] "" Vector__XXX
 SG_ VFCVectorZCUPVFCid48 : 50|1@0+ (1,0) [0|1] "" Vector__XXX
 SG_ VFCVectorZCUPVFCid49 : 51|1@0+ (1,0) [0|1] "" Vector__XXX
 SG_ VFCVectorZCUPVFCid5 : 7|1@0+ (1,0) [0|1] "" Vector__XXX
 SG_ VFCVectorZCUPVFCid50 : 52|1@0+ (1,0) [0|1] "" Vector__XXX
 SG_ VFCVectorZCUPVFCid51 : 53|1@0+ (1,0) [0|1] "" Vector__XXX
 SG_ VFCVectorZCUPVFCid52 : 54|1@0+ (1,0) [0|1] "" Vector__XXX
 SG_ VFCVectorZCUPVFCid53 : 55|1@0+ (1,0) [0|1] "" Vector__XXX
 SG_ VFCVectorZCUPVFCid54 : 56|1@0+ (1,0) [0|1] "" Vector__XXX
 SG_ VFCVectorZCUPVFCid55 : 57|1@0+ (1,0) [0|1] "" Vector__XXX
 SG_ VFCVectorZCUPVFCid56 : 58|1@0+ (1,0) [0|1] "" Vector__XXX
 SG_ VFCVectorZCUPVFCid57 : 59|1@0+ (1,0) [0|1] "" Vector__XXX
 SG_ VFCVectorZCUPVFCid58 : 60|1@0+ (1,0) [0|1] "" Vector__XXX
 SG_ VFCVectorZCUPVFCid59 : 61|1@0+ (1,0) [0|1] "" Vector__XXX
 SG_ VFCVectorZCUPVFCid6 : 8|1@0+ (1,0) [0|1] "" Vector__XXX
 SG_ VFCVectorZCUPVFCid60 : 62|1@0+ (1,0) [0|1] "" Vector__XXX
 SG_ VFCVectorZCUPVFCid61 : 63|1@0+ (1,0) [0|1] "" Vector__XXX
 SG_ VFCVectorZCUPVFCid7 : 9|1@0+ (1,0) [0|1] "" Vector__XXX
 SG_ VFCVectorZCUPVFCid8 : 10|1@0+ (1,0) [0|1] "" Vector__XXX
 SG_ VFCVectorZCUPVFCid9 : 11|1@0+ (1,0) [0|1] "" Vector__XXX

BO_ 1285 ZcupZCUDCANFD1NMFr : 8 ZCUP
 SG_ PNC23_ZCUP : 23|1@0+ (1,0) [0|0] "" Vector__XXX
 SG_ PNC25_ZCUP : 25|1@0+ (1,0) [0|0] "" Vector__XXX
 SG_ PNC29_ZCUP : 29|1@0+ (1,0) [0|0] "" Vector__XXX
 SG_ PNC36_ZCUP : 36|1@0+ (1,0) [0|0] "" Vector__XXX
 SG_ PNC38_ZCUP : 38|1@0+ (1,0) [0|0] "" Vector__XXX
 SG_ NM_PNI_ZCUP : 14|1@0+ (1,0) [0|0] "" Vector__XXX
 SG_ NM_AW_ZCUP : 12|1@0+ (1,0) [0|0] "" Vector__XXX
 SG_ NM_CS_ZCUP : 11|1@0+ (1,0) [0|0] "" Vector__XXX
 SG_ NM_RMR_ZCUP : 8|1@0+ (1,0) [0|0] "" Vector__XXX
 SG_ NM_NodeID_ZCUP : 7|8@0+ (1,0) [0|0] "" Vector__XXX

 SG_ WakeUpReasonsforZCUP : 55|16@0+ (1,0) [0|65535] "" Vector__XXX

CM_ SG_ 97 ActvnOfWelcomeLi "Activation Request for Welcome Light";
CM_ SG_ 97 ADataRawSafeALat "IMU acceleration data Lateral acceleration";
CM_ SG_ 97 ADataRawSafeALat1Qf "IMU acceleration data Quality factor for Lateral acceleration signal";
CM_ SG_ 97 ADataRawSafeALgt "IMU acceleration data Longitudinal acceleration";
CM_ SG_ 97 ADataRawSafeALgt1Qf "IMU acceleration data Quality factor for Longitudinal acceleration";
CM_ SG_ 97 ADataRawSafeAVert "IMU acceleration data Vertical acceleration";
CM_ SG_ 97 ADataRawSafeAVertQf "IMU acceleration data Quality factor for Vertical acceleration";
CM_ SG_ 97 ADataRawSafeChks "IMU acceleration data Check sum";
CM_ SG_ 97 ADataRawSafeCntr "IMU acceleration data Counter";
CM_ SG_ 97 ADModCtrlInhbnADModCtrlInhbn "Inhibition flag of AD mode.";
CM_ SG_ 97 ADModCtrlInhbnChks "checksum for ADModCtrlInhbn";
CM_ SG_ 97 ADModCtrlInhbnCntr "counter for ADModCtrlInhbn";
CM_ SG_ 97 AgDataRaw2SafeChks "IMU pitch rate data. Check sum";
CM_ SG_ 97 AgDataRaw2SafeCntr "IMU pitch rate data. Counter";
CM_ SG_ 97 AgDataRaw2SafePitchRate "IMU pitch rate data. Pitch Rate";
CM_ SG_ 97 AgDataRaw2SafePitchRateQf "IMU pitch rate data. Quality factor for Pitch Rate";
CM_ SG_ 97 AgDataRawSafeChks "IMU angular rate data. Check summa";
CM_ SG_ 97 AgDataRawSafeCntr "IMU angular rate data. Counter";
CM_ SG_ 97 AgDataRawSafeRollRate "IMU angular rate data. Roll Rate";
CM_ SG_ 97 AgDataRawSafeRollRateQf "IMU angular rate data. Quality factor for Roll Rate";
CM_ SG_ 97 AgDataRawSafeYawRate "IMU angular rate data. Yaw Rate";
CM_ SG_ 97 AgDataRawSafeYawRateQf "IMU angular rate data. Quality Factor for Yaw Rate";
CM_ SG_ 97 AmbTRawAmbTVal "Unfiltered ambient temp raw data in deg C. Ambient temp value";
CM_ SG_ 97 AmbTRawQly "Unfiltered ambient temp raw data in deg C. Quality Factor of the ambient temp";
CM_ SG_ 97 AsyDataWithCmpSafeALat1Qf "IMU processed special data. Quality factor for Lateral acceleration signal";
CM_ SG_ 97 AsyDataWithCmpSafeALatWithCmp "IMU processed special data.  Compensated Lateral acceleration";
CM_ SG_ 97 AsyDataWithCmpSafeALgt1Qf "IMU processed special data. Quality factor for Longitudinal acceleration";
CM_ SG_ 97 AsyDataWithCmpSafeChks "IMU processed special data. Check sum";
CM_ SG_ 97 AsyDataWithCmpSafeCntr "IMU processed special data. Counter";
CM_ SG_ 97 AsyDataWithCmpSafeGrdtOfALgt "IMU processed special data. Derivative of Longitudinal acceleration";
CM_ SG_ 97 AsyDataWithCmpSafeYawRateQf "IMU processed special data. Quality Factor for Yaw Rate";
CM_ SG_ 97 AsyDataWithCmpSafeYawRateWithCmp "IMU processed special data. Compensated Yaw rate";
CM_ SG_ 97 BodyHei "Body height is a calculated average value from the four level sensors at each wheel.";
CM_ SG_ 97 BrkPedlSnsrChks "E2E protection, checksum. ";
CM_ SG_ 97 BrkPedlSnsrCntr "E2E protection, counter.";
CM_ SG_ 97 BrkPedlSnsrQf "Brake pedal state, quality factor";
CM_ SG_ 97 BrkPedlSnsrSt "brake pedal state, pressed or not pressed.";
CM_ SG_ 97 BrkPedlSts "If the brake pedal decoupling has been activated.";
CM_ SG_ 97 CarTiGlb "Presents a tiime value that shall be used by all ECUs to time-stamp diagnsotic trouble codes (DTC) according to the requirements for Global DTC snapshot data.";
CM_ SG_ 97 CrsCtrlOvrdn "Override CC/ACC with accelerator pedal";
CM_ SG_ 97 CrsCtrlrMsg "The signal triggers visual messages in DIM to inform the driver relevant information about the Cruise Controller";
CM_ SG_ 97 CrsCtrlrStbOk "The signal informs if the Cruise Controller can be set to standby or not.";
CM_ SG_ 97 CrsCtrlrSts "The signal indicates the status (or state) of the Cruise Controller; Off, Standby, Actv etc.";
CM_ SG_ 97 DmcStsRearToEscChks "Chks";
CM_ SG_ 97 DmcStsRearToEscCntr "Cntr
";
CM_ SG_ 97 DmcStsRearToEscDmcActAppTarTq "DMCActAppTarTq";
CM_ SG_ 97 DmcStsRearToEscDmcSts "DmcSts
";
CM_ SG_ 97 DmcStsRearToEscDmcSWInfo "DmCSWinformation";
CM_ SG_ 97 DoorDrvrLockCmd "DoorDrvrLockCmd - Driver Door Lock Command
Locking Command signal to driver door
LockActvnOff - Idle Command
LockActvnUnlck - Unlock door
LockActvnLock - Lock door
LockActvnSafe - Double lock door
LockActvnUnlckByCrash - Crash Unlock door";
CM_ SG_ 97 DrvrDesDirChks "Desired Driver Direction is an interpretation of driver input. It specifies in which longitudinal direction the driver requests that any accelerating propulsive torque shall be delivered. There are three possible directions: 1. Forward 2. Reverse 3. Neutral. Checksum";
CM_ SG_ 97 DrvrDesDirCntr "Desired Driver Direction is an interpretation of driver input. It specifies in which longitudinal direction the driver requests that any accelerating propulsive torque shall be delivered. There are three possible directions: 1. Forward 2. Reverse 3. Neutral. Counter";
CM_ SG_ 97 DrvrDesDirDrvrDesDir "Desired Driver Direction is an interpretation of driver input. It specifies in which longitudinal direction the driver requests that any accelerating propulsive torque shall be delivered. There are three possible directions: 1. Forward 2. Reverse 3. Neutral";
CM_ SG_ 97 DrvrGearShiftDirReq1Chks "8 bit checksum";
CM_ SG_ 97 DrvrGearShiftDirReq1Cntr "4 bit counter used in checksum calculation. N=E (modulo 16)";
CM_ SG_ 97 DrvrGearShiftDirReq1DwnDwnTipAut "Gear shifter downdown tip in automatic gate";
CM_ SG_ 97 DrvrGearShiftDirReq1DwnTipAut "Gear shifter down tip in automatic gate";
CM_ SG_ 97 DrvrGearShiftDirReq1PosnAut "Gear shifter in automatic gate position";
CM_ SG_ 97 DrvrGearShiftDirReq1UpTipAut "Gear shifter up tip in automatic gate";
CM_ SG_ 97 DrvrGearShiftDirReq1UpUpTipAut "Gear shifter upup tip in automatic gate";
CM_ SG_ 97 DrvrGearShiftDirReq2Chks "8 bit checksum";
CM_ SG_ 97 DrvrGearShiftDirReq2Cntr "4 bit counter used in checksum calculation. N=E (modulo 16)";
CM_ SG_ 97 DrvrGearShiftDirReq2DwnDwnTipAut "Gear shifter downdown tip in automatic gate";
CM_ SG_ 97 DrvrGearShiftDirReq2DwnTipAut "Gear shifter down tip in automatic gate";
CM_ SG_ 97 DrvrGearShiftDirReq2PosnAut "Gear shifter in automatic gate position";
CM_ SG_ 97 DrvrGearShiftDirReq2UpTipAut "Gear shifter up tip in automatic gate";
CM_ SG_ 97 DrvrGearShiftDirReq2UpUpTipAut "Gear shifter upup tip in automatic gate";
CM_ SG_ 97 EpbActrStSec "EPB actuator state for Secondary EPB ECU.";
CM_ SG_ 97 ExtrLiRlyPwrDwn "Informs HCMs about upcoming shut down of Exterior Light Relay.";
CM_ SG_ 97 GearMovmtFlg "A signal flag to make DHU control the ASL&ACC function open or close.";
CM_ SG_ 97 WhlMotSysModSts "Reflects the current operating mode of the IEM.";
CM_ SG_ 97 WhlMotSysTqEstChks "Checksum of estimation torque";
CM_ SG_ 97 WhlMotSysTqEstCntr "Counter of estimation torque";
CM_ SG_ 97 WhlMotSysTqEstIsgTqAct "Estimation torque of Rear Axle Control";
CM_ SG_ 97 WhlMotSysTqEstQualityFactor "Quality factor of estimation torque";
CM_ SG_ 261 ActvnStsOfRtrctrRvsbLe "Signals to the SRS (and other nodes) that the belts have triggered.";
CM_ SG_ 261 AlrmStsAlrmFailr "Indicates alarm status, last trigger source and alarm component errors.";
CM_ SG_ 261 AlrmStsAlrmSt "Indicates alarm status, last trigger source and alarm component errors.";
CM_ SG_ 261 AlrmStsAlrmTrgSrc "Indicates alarm status, last trigger source and alarm component errors.";
CM_ SG_ 261 AlrmStsSnsrInclnFailr "Indicates alarm status, last trigger source and alarm component errors.";
CM_ SG_ 261 AlrmStsSnsrIntrScanrFailr "Indicates alarm status, last trigger source and alarm component errors.";
CM_ SG_ 261 BltLockStSafeAtDrvrBltLockSt1 "State of belt lock at driver seating position Belt lock state, locked/unlocked";
CM_ SG_ 261 BltLockStSafeAtDrvrBltLockStErrSts "State of belt lock at driver seating position Belt lock status, OK/NOK";
CM_ SG_ 261 BltLockStSafeAtDrvrChks "Counter for E2E";
CM_ SG_ 261 BltLockStSafeAtDrvrCntr "Checksum for E2E";
CM_ SG_ 261 BrkPedlValBrkPedlVal "Position of the brake pedal. Physical lower limit: no pedal activation. Physical upper limit: full pedal stroke Brake pedal position";
CM_ SG_ 261 BrkPedlValQf "Position of the brake pedal. Physical lower limit: no pedal activation. Physical upper limit: full pedal stroke Brake pedal sensor quality factor";
CM_ SG_ 261 DoorDrvrSts "DoorDrvrSts - Driver Door Status
Ukwn - Unknown status
Opend - Opened
Clsd - Closed";
CM_ SG_ 261 DoorDrvrStsWithFacQlyDoorSts "DoorDrvrStsWithFacQly - Driver Door Status with quality factor
Driver door status (open or closed) is read from the microswitch in the side door lock.";
CM_ SG_ 261 DoorDrvrStsWithFacQlyFacQly "DoorDrvrStsWithFacQly - Driver Door Status with quality factor
Driver door status (open or closed) is read from the microswitch in the side door lock.";
CM_ SG_ 261 DoorLeReSts "DoorLeReSts - Left Rear Side Door Status.
Ukwn - Unknown status
Opend - Opened
Clsd - Closed";
CM_ SG_ 261 DoorPassSts "DoorPassSts - Passenger Door Status
Ukwn - Unknown status
Opend - Opened
Clsd - Closed";
CM_ SG_ 261 DoorRiReSts "DoorRiReSts - Right Rear Side Door Status
Ukwn - Unknown status
Opend - Opened
Clsd - Closed";
CM_ SG_ 261 DrvrPrsntStsDrvrPrsnt "Driver present";
CM_ SG_ 261 DrvrPrsntStsDrvrPrsntChks "Checksum";
CM_ SG_ 261 DrvrPrsntStsDrvrPrsntCntr "Counter";
CM_ SG_ 261 DrvrPrsntStsDrvrPrsntQf "Driver present";
CM_ SG_ 261 GearLvrIndcn "Gear lever indication (drivetrain position) to the driver. If drivetrain position is not possible to decide signal is set to undefined. Valid for automatic vehicles.
";
CM_ SG_ 261 GearMov "To indicate the case that if any one of gear lever, shifting fork, gear lock button, P-button is intervened when vehicle enter APA/RPA mode
YesYesNoUnknown,
0=YesYesNoUnknown_No
1=YesYesNoUnknown_YesNo
2=YesYesNoUnknown_Unknown
3=YesYesNoUnknown_YesYes";
CM_ SG_ 261 HoodSts "HoodSts - Hood Status
Ukwn - Unknown status
Opend - Opened
Clsd - Closed";
CM_ SG_ 261 IndcrDisp "Controls the Direction Indicator tell-tales and sound to the driver.

Signal will be event driven and holds every flank on and off of the telltales/sound.

This signal will not be used for the Hazard Warning Light Button in instrument panel.";
CM_ SG_ 261 IndcrSts "Provides the state and not the event of HWL/Direction Indicator.";
CM_ SG_ 261 LockgCenStsLockSt "Signal LockgCenSts provides central locking status to other subsystems.
Signal is a record with three items
- LockSt (Lock State)
- TrigSrc (Trig Source)
- UpdEve (Will be set to TRUE during one second at each new central locking or unlocking event)";
CM_ SG_ 261 LockgCenStsTrigSrc "Signal LockgCenSts provides central locking status to other subsystems.
Signal is a record with three items
- LockSt (Lock State)
- TrigSrc (Trig Source)
- UpdEve (Will be set to TRUE during one second at each new central locking or unlocking event)";
CM_ SG_ 261 LockgCenStsUpdEve "Signal LockgCenSts provides central locking status to other subsystems.
Signal is a record with three items
- LockSt (Lock State)
- TrigSrc (Trig Source)
- UpdEve (Will be set to TRUE during one second at each new central locking or unlocking event)";
CM_ SG_ 261 LvlgDirMovmtIndcr "This signal is used for indicating the movement direction in the air suspension during its change.";
CM_ SG_ 261 MirrFoldStsAtDrvr "Reports the fold status of the outer rear view mirrors. Driver side.";
CM_ SG_ 261 PtBrkTqActTot "Total actual Powertrain brake torque";
CM_ SG_ 261 PtBrkTqActTotQf "Total actual Powertrain brake torque quality factor";
CM_ SG_ 261 PtBrkTqChks "Checksum";
CM_ SG_ 261 PtBrkTqCntr "Counter";
CM_ SG_ 261 PtBrkTqQf "Quality factor";
CM_ SG_ 261 PtBrkTqReqForBrkSys "Powertrain brake torque for brake system";
CM_ SG_ 261 PtBrkTqRgnAtAxleReAct "Actual powertrain regeneration torque at rear axle";
CM_ SG_ 261 RecOfPostImpctBrkgCfmdChks "E2E checksum";
CM_ SG_ 261 RecOfPostImpctBrkgCfmdCntr "E2E counter";
CM_ SG_ 261 RecOfPostImpctBrkgCfmdCrashFrnt "Crash type = front.";
CM_ SG_ 261 RecOfPostImpctBrkgCfmdCrashLargeAnimal "Large Animal";
CM_ SG_ 261 RecOfPostImpctBrkgCfmdCrashOffroadA "Airbourne";
CM_ SG_ 261 RecOfPostImpctBrkgCfmdCrashOffroadD "Ditch";
CM_ SG_ 261 RecOfPostImpctBrkgCfmdCrashOffroadRT "Rough Terrain";
CM_ SG_ 261 RecOfPostImpctBrkgCfmdCrashOffroadRTsevere "Rough Terrain, severe";
CM_ SG_ 261 RecOfPostImpctBrkgCfmdCrashOz "Crash type = side offzone (i.e. behind C-pillar or in front of A-pillar.) ";
CM_ SG_ 261 RecOfPostImpctBrkgCfmdCrashPed "Crash type = pedestrian impact";
CM_ SG_ 261 RecOfPostImpctBrkgCfmdCrashRe "Crash type = rear";
CM_ SG_ 261 RecOfPostImpctBrkgCfmdCrashRollovr "Crash type = rollover";
CM_ SG_ 261 RecOfPostImpctBrkgCfmdCrashSideLe "Crash type = left side.";
CM_ SG_ 261 RecOfPostImpctBrkgCfmdCrashSideRi "Crash type = right side.";
CM_ SG_ 261 RecOfPostImpctBrkgCfmdPostImpctBrkgCfmd "ASIL-B(D) signal to inform that a crash has occurred.";
CM_ SG_ 261 StsForRtrctrRvsbLe "Belt ready status";
CM_ SG_ 261 SunRoofPosnSts "Sun roof position status";
CM_ SG_ 261 SuspHeiLvlIndcn "This signal specifies which height the body has reached.";
CM_ SG_ 261 TrsmParkLockdChks "Checksum for TrsmParkLockd";
CM_ SG_ 261 TrsmParkLockdCntr "Counter for TrsmParkLockd";
CM_ SG_ 261 TrsmParkLockdTrsmParkLockd "Transmission park lock status";
CM_ SG_ 261 TrSts "TrSts - Tailgate or Bootlid Status
Ukwn - Unknown status
Opend - Opened
Clsd - Closed";
CM_ SG_ 261 WhlMotSysLimnIndcn "The limitation indication of derating conditions";
CM_ SG_ 851 BltLockStAtRowSecLeBltLockEquid "State of belt lock at seating position at left of second row If the belt lock is equipped";
CM_ SG_ 851 BltLockStAtRowSecLeBltLockSt1 "State of belt lock at seating position at left of second row Belt lock state,  locked/unlocked";
CM_ SG_ 851 BltLockStAtRowSecLeBltLockSts "State of belt lock at seating position at left of second row Belt lock status, OK/NOK";
CM_ SG_ 851 BltLockStAtRowSecMidBltLockEquid "State of belt lock at seating position at middle of second row If the belt lock is equipped";
CM_ SG_ 851 BltLockStAtRowSecMidBltLockSt1 "State of belt lock at seating position at middle of second row Belt lock state,  locked/unlocked";
CM_ SG_ 851 BltLockStAtRowSecMidBltLockSts "State of belt lock at seating position at middle of second row Belt lock status, OK/NOK";
CM_ SG_ 851 BltLockStAtRowSecRiBltLockEquid "State of belt lock at seating position at right of second row If the belt lock is equipped";
CM_ SG_ 851 BltLockStAtRowSecRiBltLockSt1 "State of belt lock at seating position at right of second row Belt lock state,  locked/unlocked";
CM_ SG_ 851 BltLockStAtRowSecRiBltLockSts "State of belt lock at seating position at right of second row Belt lock status, OK/NOK";
CM_ SG_ 851 BltLockStAtRowThrdLeBltLockEquid "State of belt lock at seating position at left of third row If the belt lock is equipped";
CM_ SG_ 851 BltLockStAtRowThrdLeBltLockSt1 "State of belt lock at seating position at left of third row Belt lock state,  locked/unlocked";
CM_ SG_ 851 BltLockStAtRowThrdLeBltLockSts "State of belt lock at seating position at left of third row Belt lock status, OK/NOK";
CM_ SG_ 851 BltLockStAtRowThrdRiBltLockEquid "State of belt lock at seating position at right of third row If the belt lock is equipped";
CM_ SG_ 851 BltLockStAtRowThrdRiBltLockSt1 "State of belt lock at seating position at right of third row Belt lock state,  locked/unlocked";
CM_ SG_ 851 BltLockStAtRowThrdRiBltLockSts "State of belt lock at seating position at right of third row Belt lock status, OK/NOK";
CM_ SG_ 851 BtnLockSts1BtnSts2 "Lock button pressed status";
CM_ SG_ 851 BtnLockSts1KeyId "key id";
CM_ SG_ 851 BtnTrSts1BtnSts2 "Trunk button pressed status";
CM_ SG_ 851 BtnTrSts1KeyId "key id";
CM_ SG_ 851 BtnUnlckSts1BtnSts2 "Unlock button pressed status";
CM_ SG_ 851 BtnUnlckSts1KeyId "key id";
CM_ SG_ 851 DCChrgnHndlSts "Fast charging gun connect state";
CM_ SG_ 851 ULoWarnChks "Checksum";
CM_ SG_ 851 ULoWarnCntr "Counter";
CM_ SG_ 851 ULoWarnULoWarn "Low voltage warning at LVEEM system";
CM_ SG_ 851 UsgModDeactvnQly "Indicates if UsageMode is valid when vehicle is deactivated";
CM_ SG_ 545 BltLockStAtPassBltLockSt1 "State of belt lock at passenger seating position Belt lock state, locked/unlocked";
CM_ SG_ 545 BltLockStAtPassBltLockSts "State of belt lock at passenger seating position Belt lock status, OK/NOK";
CM_ SG_ 545 KeyDistncStsKey0 "KeyDistncSts - Key Distance status
The actual key distance measured in cm from car perimeter, for Key0";
CM_ SG_ 545 KeyDistncStsKey1 "KeyDistncSts - Key Distance status
The actual key distance measured in cm from car perimeter, for Key1";
CM_ SG_ 545 KeyDistncStsKey2 "KeyDistncSts - Key Distance status
The actual key distance measured in cm from car perimeter, for Key2";
CM_ SG_ 545 KeyDistncStsKey3 "KeyDistncSts - Key Distance status
The actual key distance measured in cm from car perimeter, for Key3";
CM_ SG_ 545 KeyDistncStsKey4 "KeyDistncSts - Key Distance status
The actual key distance measured in cm from car perimeter, for Key4";
CM_ SG_ 545 KeyDistncStsKey5 "KeyDistncSts - Key Distance status
The actual key distance measured in cm from car perimeter, for Key5";
CM_ SG_ 545 MsgReqForRtrctrRvsbLe "Request to show message in DIM indicating that there is a fault with the RMx.";
CM_ SG_ 545 TDcDcCoolt "Inlet Coolant Temperature of the DCDC";
CM_ SG_ 545 TwliBriSts "Day or night status signal. Lux value (not this signal) sent from SUS to CEM and CEM sets day or night signal.";
CM_ SG_ 579 DcDcActvd "DCDC actived state";
CM_ SG_ 579 HvBattSoc "Actual state of charge of the Hv Battery.";
CM_ SG_ 579 LeFrntTireMsgBattLoSt "battery low status";
CM_ SG_ 579 LeFrntTireMsgFastLoseWarnFlg "fast lost warn flag";
CM_ SG_ 579 LeFrntTireMsgMsgOldFlg "message old flag";
CM_ SG_ 579 LeFrntTireMsgP "tire temperature";
CM_ SG_ 579 LeFrntTireMsgPWarnFlg "pressure warn flag";
CM_ SG_ 579 LeFrntTireMsgSysWarnFlg "system warn flag";
CM_ SG_ 579 LeFrntTireMsgT "tire pressure";
CM_ SG_ 579 LeFrntTireMsgTireFillgAssiPSts "tire fill status";
CM_ SG_ 579 LeFrntTireMsgTWarnFlg "temperature warn flag";
CM_ SG_ 579 LeReTireMsgBattLoSt "battery low status";
CM_ SG_ 579 LeReTireMsgFastLoseWarnFlg "fast lost warn flag";
CM_ SG_ 579 LeReTireMsgMsgOldFlg "message old flag";
CM_ SG_ 579 LeReTireMsgP "tire temperature";
CM_ SG_ 579 LeReTireMsgPWarnFlg "pressure warn flag";
CM_ SG_ 579 LeReTireMsgSysWarnFlg "system warn flag";
CM_ SG_ 579 LeReTireMsgT "tire pressure";
CM_ SG_ 579 LeReTireMsgTireFillgAssiPSts "tire fill status";
CM_ SG_ 579 LeReTireMsgTWarnFlg "temperature warn flag";
CM_ SG_ 579 OnBdChrgrHndlSts1 "Status of the Onboard Charger connection to the grid. ";
CM_ SG_ 579 RiFrntTireMsgBattLoSt "battery low status";
CM_ SG_ 579 RiFrntTireMsgFastLoseWarnFlg "fast lost warn flag";
CM_ SG_ 579 RiFrntTireMsgMsgOldFlg "message old flag";
CM_ SG_ 579 RiFrntTireMsgP "tire temperature";
CM_ SG_ 579 RiFrntTireMsgPWarnFlg "pressure warn flag";
CM_ SG_ 579 RiFrntTireMsgSysWarnFlg "system warn flag";
CM_ SG_ 579 RiFrntTireMsgT "tire pressure";
CM_ SG_ 579 RiFrntTireMsgTireFillgAssiPSts "tire fill status";
CM_ SG_ 579 RiFrntTireMsgTWarnFlg "temperature warn flag";
CM_ SG_ 579 RiReTireMsgBattLoSt "battery low status";
CM_ SG_ 579 RiReTireMsgFastLoseWarnFlg "fast lost warn flag";
CM_ SG_ 579 RiReTireMsgMsgOldFlg "message old flag";
CM_ SG_ 579 RiReTireMsgP "tire temperature";
CM_ SG_ 579 RiReTireMsgPWarnFlg "pressure warn flag";
CM_ SG_ 579 RiReTireMsgSysWarnFlg "system warn flag";
CM_ SG_ 579 RiReTireMsgT "tire pressure";
CM_ SG_ 579 RiReTireMsgTireFillgAssiPSts "tire fill status";
CM_ SG_ 579 RiReTireMsgTWarnFlg "temperature warn flag";
CM_ SG_ 579 SeatBackAngleRowFirstDrvr "Backrest angle of the First Row Driver Seat";
CM_ SG_ 451 AD4HeatingCircTestSts "If heating circuit work normal.";
CM_ SG_ 451 AdjSpdLimnFusnTrfcSgn "AVSL function fuse TSI request";
CM_ SG_ 451 EngTEngT "Engine coolant temperature. Resolution 1 degC
";
CM_ SG_ 451 EngTQf "Engine coolant temperature quality factor.Engine coolant temperature";
CM_ SG_ 451 ExtrLtgStsAFS "AFS status";
CM_ SG_ 451 ExtrLtgStsAHBC "AHBC Status";
CM_ SG_ 451 ExtrLtgStsAHL "AHL Status";
CM_ SG_ 451 ExtrLtgStsAllWL "All Weather Light Status";
CM_ SG_ 451 ExtrLtgStsApproach "Approach Light Status";
CM_ SG_ 451 ExtrLtgStsChks "Checksum";
CM_ SG_ 451 ExtrLtgStsCntr "Counter";
CM_ SG_ 451 ExtrLtgStsCornrgLi "Cornering Light Status";
CM_ SG_ 451 ExtrLtgStsDBL "DBL Stataus";
CM_ SG_ 451 ExtrLtgStsDRL "DRL Status";
CM_ SG_ 451 ExtrLtgStsFlash "Flash Light Status";
CM_ SG_ 451 ExtrLtgStsFrntFog "Front Fog Light Status";
CM_ SG_ 451 ExtrLtgStsGoodbye "Good Bye Light Status";
CM_ SG_ 451 ExtrLtgStsHiBeam "Hi Beam Status";
CM_ SG_ 451 ExtrLtgStsHomeSafe "Home Safe Light Status";
CM_ SG_ 451 ExtrLtgStsHWL "HWL Status";
CM_ SG_ 451 ExtrLtgStsLoBeam "Low Beam Status";
CM_ SG_ 451 ExtrLtgStsLtgShow "Light Show Status";
CM_ SG_ 451 ExtrLtgStsPosLiFrnt "Position Light Front Status";
CM_ SG_ 451 ExtrLtgStsPosLiRe "Position Light Rear Status";
CM_ SG_ 451 ExtrLtgStsReFog "Rear Fog Light Status";
CM_ SG_ 451 ExtrLtgStsReverseLi "Reverse Light Status";
CM_ SG_ 451 ExtrLtgStsStopLi "Stop Light Status";
CM_ SG_ 451 ExtrLtgStsTurnIndrLe "Turn Indicator Left Status";
CM_ SG_ 451 ExtrLtgStsTurnIndrRi "Turn Indicator Right Status
";
CM_ SG_ 451 ExtrLtgStsWelcome "Welcome Light Status";
CM_ SG_ 451 RainfallAmnt "The signal describe the amount of rain falling";
CM_ SG_ 451 RcwmLiActvd "Informs about activation of rear collision warning.";
CM_ SG_ 451 SteerWhlPosnAng "Angle is height adjustment(HA)";
CM_ SG_ 451 SteerWhlPosnX "X is length adjustment(LA)";
CM_ SG_ 451 SwtIndcrIndcrTypExtReq "Signal represent status of the turn stalk swich";
CM_ SG_ 451 SwtIndcrIndcrTypExtReqChks "Checksum";
CM_ SG_ 451 SwtIndcrIndcrTypExtReqCntr "Counter";
CM_ SG_ 451 SwtIndcrIndcrTypExtReqToUpdQf "Qf";
CM_ SG_ 451 TiDrvgCycOff "Timer since engine was deactivated";
CM_ SG_ 451 TrLockSts "TrLockSts - Tailgate or bootlid lock status
LockStsUkwn - Lock status of tailgate or bootlid Unknown
Unlckd - Tailgate or Bootlid is unlocked
Lockd - Tailgate or Bootlid is locked
SafeLockd - Not used for Tailgate or Bootlid";
CM_ SG_ 451 TurnIndcrMonostableChks "Checksum";
CM_ SG_ 451 TurnIndcrMonostableCntr "Counter";
CM_ SG_ 451 TurnIndcrMonostableQf "Qf";
CM_ SG_ 451 TurnIndcrMonostableTurnIndcrMonostable "turn indicator Monostable";
CM_ SG_ 451 TwliBriRawQf "Outside ambient light measured by SUS and sent to CEM as lux value. Quality Factor";
CM_ SG_ 451 TwliBriRawTwliBriRaw "Outside ambient light measured by SUS and sent to CEM as lux value. Raw value";
CM_ SG_ 451 VehParkNotActvd "When VehParkNotActvd equals Set, activation of the electrical parking brake shall be requested ";
CM_ SG_ 451 WipgInfoWipgSpdInfo "Information regarding how the wipers are run";
CM_ SG_ 451 WipgInfoWiprActv " 0 No wiping, 1 Wiping";
CM_ SG_ 451 WipgInfoWiprInWipgAr " 0 Wiper in lower reversing area or parked, 1 Wiper in wiping area";
CM_ SG_ 867 JIDByte0 "IMU identification number. Byte0";
CM_ SG_ 867 JIDByte1 "IMU identification number. Byte1";
CM_ SG_ 867 JIDByte2 "IMU identification number. Byte2";
CM_ SG_ 867 JIDByte3 "IMU identification number. Byte3";
CM_ SG_ 867 JIDByte4 "IMU identification number. Byte4";
CM_ SG_ 867 JIDByte5 "IMU identification number. Byte5";
CM_ SG_ 867 JIDByte6 "IMU identification number. Byte6";
CM_ SG_ 867 JIDByte7 "IMU identification number. Byte7";
CM_ SG_ 867 OnBdChrgrCooltT "Inlet Coolant Temperature of the OBC";
CM_ SG_ 931 DispHvBattLvlOfChrg "HV battery State-Of-Charge (SOC) value for display to driver. Note: this value may differ from the actual battery SOC. ";
CM_ SG_ 931 PassAirbSts "Passenger airbag status, based on PACOS input.";
CM_ SG_ 931 VehBattUSysU "Vehicle System Voltage At 12V side";
CM_ SG_ 931 VehBattUSysUQf "Present vehicle voltage measured by CEM with QF";
CM_ SG_ 83 AccrPedlRatAccrPedlRat "Accelerator Pedal Position with adapted 0 point. Value as percentage of fully pressed pedal";
CM_ SG_ 83 AccrPedlRatChks "Accelerator Pedal Position with adapted 0 point. Value as percentage of fully pressed pedal. Checksum";
CM_ SG_ 83 AccrPedlRatCntr "Accelerator Pedal Position with adapted 0 point. Value as percentage of fully pressed pedal. Counter";
CM_ SG_ 83 BltLockStAtDrvrBltLockSt1 "State of belt lock at driver seating position Belt lock state, locked/unlocked";
CM_ SG_ 83 BltLockStAtDrvrBltLockSts "State of belt lock at driver seating position Belt lock status, OK/NOK";
CM_ SG_ 83 DoorDrvrLockSts "DoorDrvrLockSts - Driver Door Lock Status
Lock status
LockStsUkwn - Lock Status Unknown
Unlckd - Unlocked
Lockd - Locked
SafeLockd - Safe Locked (Double Locked)";
CM_ SG_ 83 DoorLeReLockSts "DoorLeReLockSts - Left Rear Door Lock Status
Lock status
LockStsUkwn - Lock Status Unknown
Unlckd - Unlocked
Lockd - Locked
SafeLockd - Safe Locked (Double Locked)";
CM_ SG_ 83 DrvrGearShiftParkReq1 "Driver park request from gear shifter. Valid for Shift-By-Wire system.";
CM_ SG_ 83 DrvrGearShiftParkReqChks "Driver park request from gear shifter. Valid for Shift-By-Wire system.Checksum";
CM_ SG_ 83 DrvrGearShiftParkReqCntr "Driver park request from gear shifter. Valid for Shift-By-Wire system.Counter";
CM_ SG_ 83 DrvrGearShiftParkReqSts "Driver park request from gear shifter. Valid for Shift-By-Wire system.Status";
CM_ SG_ 83 EngSt1WdStsChks "checksum";
CM_ SG_ 83 EngSt1WdStsCntr "counter";
CM_ SG_ 83 EngSt1WdStsEngSt1WdSts "Signaling the state of the powerpack";
CM_ SG_ 83 LcmaLedStsDrvrSide "LED status in Driver side rear mirror.";
CM_ SG_ 83 PinionSteerAgGroupChks "Checksum for PinionSteerAgGroup";
CM_ SG_ 83 PinionSteerAgGroupCntr "Counter for PinionSteerAgGroup";
CM_ SG_ 83 PinionSteerAgGroupPinionSteerAg1 "Calculated pinion steer angle at the front steering device";
CM_ SG_ 83 PinionSteerAgGroupPinionSteerAg1Qf "Quality factor for PinionSteerAg1";
CM_ SG_ 83 PinionSteerAgGroupPinionSteerAgSpd1 "Calculated pinion steer angle speed at the front steering device ";
CM_ SG_ 83 PinionSteerAgGroupPinionSteerAgSpd1Qf "Quality factor for PinionSteerAgSpd1";
CM_ SG_ 83 PinionSteerAgGroupSteerWhlTq "Torque on steering wheel";
CM_ SG_ 83 PinionSteerAgGroupSteerWhlTqQf "Quality factor for SteerWhlTq";
CM_ SG_ 83 RecOfPostImpctBrkgSuspcChks "Signal checksum";
CM_ SG_ 83 RecOfPostImpctBrkgSuspcCntr "Signal counter";
CM_ SG_ 83 RecOfPostImpctBrkgSuspcSuspcPostImpctBrkg "ASIL-B(D) signal to inform that a crash has occurred.";
CM_ SG_ 83 SuspPosnVertLe1Chks "Checksum on height information and QFs for front and rear.";
CM_ SG_ 83 SuspPosnVertLe1Frnt "Height information from left front";
CM_ SG_ 83 SuspPosnVertLe1FrntQf "QF on height information from left front";
CM_ SG_ 83 SuspPosnVertLe1Re "Height information from left rear";
CM_ SG_ 83 SuspPosnVertLe1ReQf "QF on height information from left rear";
CM_ SG_ 83 SuspPosnVertRi1SuspPosnVertRiChks "External CAN signal to inform the right body height (include both front and rear) with ASIL-A leve(A CRC is added)l. Checksum on height information and QF for front and rear.";
CM_ SG_ 83 SuspPosnVertRi1SuspPosnVertRiFrnt "External CAN signal to inform the right body height (include both front and rear) with ASIL-A leve(A CRC is added)l. Height information from right front";
CM_ SG_ 83 SuspPosnVertRi1SuspPosnVertRiFrntQf "External CAN signal to inform the right body height (include both front and rear) with ASIL-A leve(A CRC is added)l. QF on height information from right front";
CM_ SG_ 83 SuspPosnVertRi1SuspPosnVertRiRe "External CAN signal to inform the right body height (include both front and rear) with ASIL-A leve(A CRC is added)l. Height information from right rear";
CM_ SG_ 83 SuspPosnVertRi1SuspPosnVertRiReQf "External CAN signal to inform the right body height (include both front and rear) with ASIL-A leve(A CRC is added)l. QF on height information from right rear";
CM_ SG_ 83 VehModMngtGlbSafe1CarModSts1 "CarMode Status";
CM_ SG_ 83 VehModMngtGlbSafe1CarModSubtypWdCarModSubtyp "CarMode substate status";
CM_ SG_ 83 VehModMngtGlbSafe1Chks "Checksum";
CM_ SG_ 83 VehModMngtGlbSafe1Cntr "Counter";
CM_ SG_ 83 VehModMngtGlbSafe1EgyLvlElecMai "Main energy level in the vehicle.";
CM_ SG_ 83 VehModMngtGlbSafe1EgyLvlElecSubtyp "Substate of the energy level in the vehicle.";
CM_ SG_ 83 VehModMngtGlbSafe1FltEgyCnsWdSts "High quiescent current detected by CEM via BMS.";
CM_ SG_ 83 VehModMngtGlbSafe1PwrLvlElecMai "Main Power level in the vehicle.";
CM_ SG_ 83 VehModMngtGlbSafe1PwrLvlElecSubtyp "Substate of the power level in the vehicle.";
CM_ SG_ 83 VehModMngtGlbSafe1UsgModSts "UsageMode Status";
CM_ SG_ 83 VehTiAndDataDataValid "Vehicle time (Hr, Min and Sec) and date (Year, Months and days) data for indication. See requirement for more information about the signals. Signal qualifier, No means values should be ignored.";
CM_ SG_ 83 VehTiAndDataDay "Vehicle time (Hr, Min and Sec) and date (Year, Months and days) data for indication. See requirement for more information about the signals. Day";
CM_ SG_ 83 VehTiAndDataHr1 "Vehicle time (Hr, Min and Sec) and date (Year, Months and days) data for indication. See requirement for more information about the signals. Hour";
CM_ SG_ 83 VehTiAndDataMins1 "Vehicle time (Hr, Min and Sec) and date (Year, Months and days) data for indication. See requirement for more information about the signals. Minutes";
CM_ SG_ 83 VehTiAndDataMth1 "Vehicle time (Hr, Min and Sec) and date (Year, Months and days) data for indication. See requirement for more information about the signals. Month, 1-12";
CM_ SG_ 83 VehTiAndDataSec1 "Vehicle time (Hr, Min and Sec) and date (Year, Months and days) data for indication. See requirement for more information about the signals. Seconds";
CM_ SG_ 83 VehTiAndDataYr1 "Vehicle time (Hr, Min and Sec) and date (Year, Months and days) data for indication. See requirement for more information about the signals. Year, 0-99";
CM_ SG_ 83 WinPosnStsAtDrvr "Signal sent to inform the rest of the car of the window position status for the front driver side door. The value of the signal is either an approximated percentage of openness, of the window is moving or if the position is unkown.
";
CM_ SG_ 83 WinPosnStsAtReLe "Signal sent to inform the rest of the car of the window position status for the rear driver side door. The value of the signal is either an approximated percentage of openness, of the window is moving or if the position is unkown.

";
CM_ SG_ 837 EPBLockMgrReqCmd "Command to unlock or lock the EPB lock";
CM_ SG_ 837 EPBLockMgrReqData0 "16 bytes challenge used for challenge response with BCM sent to CryptoMgr";
CM_ SG_ 837 EPBLockMgrReqData1 "16 bytes challenge used for challenge response with BCM sent to CryptoMgr";
CM_ SG_ 837 EPBLockMgrReqData2 "16 bytes challenge used for challenge response with BCM sent to CryptoMgr";
CM_ SG_ 837 EPBLockMgrReqData3 "16 bytes challenge used for challenge response with BCM sent to CryptoMgr";
CM_ SG_ 837 EPBLockMgrReqData4 "16 bytes challenge used for challenge response with BCM sent to CryptoMgr";
CM_ SG_ 837 EPBLockMgrReqData5 "16 bytes challenge used for challenge response with BCM sent to CryptoMgr";
CM_ SG_ 837 EPBLockMgrReqData6 "16 bytes challenge used for challenge response with BCM sent to CryptoMgr";
CM_ SG_ 837 TiAndDateIndcnDataValid "Current time (Hr, Min and Sec) and date (Year, Months and days) data for indication. See requirement for more information about the signals. Signal qualifier, No means values should be ignored.";
CM_ SG_ 837 TiAndDateIndcnDay "Current time (Hr, Min and Sec) and date (Year, Months and days) data for indication. See requirement for more information about the signals. Day";
CM_ SG_ 837 TiAndDateIndcnHr1 "Current time (Hr, Min and Sec) and date (Year, Months and days) data for indication. See requirement for more information about the signals. Hour";
CM_ SG_ 837 TiAndDateIndcnMins1 "Current time (Hr, Min and Sec) and date (Year, Months and days) data for indication. See requirement for more information about the signals. Minutes";
CM_ SG_ 837 TiAndDateIndcnMth1 "Current time (Hr, Min and Sec) and date (Year, Months and days) data for indication. See requirement for more information about the signals. Month, 1-12";
CM_ SG_ 837 TiAndDateIndcnSec1 "Current time (Hr, Min and Sec) and date (Year, Months and days) data for indication. See requirement for more information about the signals. Seconds";
CM_ SG_ 837 TiAndDateIndcnYr1 "Current time (Hr, Min and Sec) and date (Year, Months and days) data for indication. See requirement for more information about the signals. Year, 0-99";
CM_ SG_ 1347 VFCVectorZCUDMBlockID "BlockID";
CM_ SG_ 1347 VFCVectorZCUDMVFCid0 "SettingsComfort";
CM_ SG_ 1347 VFCVectorZCUDMVFCid1 "ParkingDrivingClimatization";
CM_ SG_ 1347 VFCVectorZCUDMVFCid10 "ExteriorLighting";
CM_ SG_ 1347 VFCVectorZCUDMVFCid11 "VFC11";
CM_ SG_ 1347 VFCVectorZCUDMVFCid12 "Alarm";
CM_ SG_ 1347 VFCVectorZCUDMVFCid13 "VFC13";
CM_ SG_ 1347 VFCVectorZCUDMVFCid14 "InteriorLighting";
CM_ SG_ 1347 VFCVectorZCUDMVFCid15 "VFC15";
CM_ SG_ 1347 VFCVectorZCUDMVFCid16 "Locking";
CM_ SG_ 1347 VFCVectorZCUDMVFCid17 "RemoteKeyFunctionality";
CM_ SG_ 1347 VFCVectorZCUDMVFCid18 "PropulsionStart";
CM_ SG_ 1347 VFCVectorZCUDMVFCid19 "VFC19";
CM_ SG_ 1347 VFCVectorZCUDMVFCid2 "PostClimatisation";
CM_ SG_ 1347 VFCVectorZCUDMVFCid20 "VFC20";
CM_ SG_ 1347 VFCVectorZCUDMVFCid21 "PowerClosures";
CM_ SG_ 1347 VFCVectorZCUDMVFCid22 "VehicleDriving";
CM_ SG_ 1347 VFCVectorZCUDMVFCid23 "VFC23";
CM_ SG_ 1347 VFCVectorZCUDMVFCid24 "SettingsProfile";
CM_ SG_ 1347 VFCVectorZCUDMVFCid25 "SeatComfortFunctions";
CM_ SG_ 1347 VFCVectorZCUDMVFCid26 "Brake";
CM_ SG_ 1347 VFCVectorZCUDMVFCid27 "InfotainmentPoll";
CM_ SG_ 1347 VFCVectorZCUDMVFCid28 "HVEnergyStorage";
CM_ SG_ 1347 VFCVectorZCUDMVFCid29 "VFC29";
CM_ SG_ 1347 VFCVectorZCUDMVFCid3 "PowertrainParkingClimatization";
CM_ SG_ 1347 VFCVectorZCUDMVFCid30 "TelematicsConnectivity";
CM_ SG_ 1347 VFCVectorZCUDMVFCid31 "VFC31";
CM_ SG_ 1347 VFCVectorZCUDMVFCid32 "VFC32";
CM_ SG_ 1347 VFCVectorZCUDMVFCid33 "Diagnostics";
CM_ SG_ 1347 VFCVectorZCUDMVFCid34 "VehicleModeManagement";
CM_ SG_ 1347 VFCVectorZCUDMVFCid35 "TrailerCaravanFunctions";
CM_ SG_ 1347 VFCVectorZCUDMVFCid36 "Immobilizer";
CM_ SG_ 1347 VFCVectorZCUDMVFCid37 "Windows";
CM_ SG_ 1347 VFCVectorZCUDMVFCid38 "Visibility";
CM_ SG_ 1347 VFCVectorZCUDMVFCid39 "VFC39";
CM_ SG_ 1347 VFCVectorZCUDMVFCid4 "VFC4";
CM_ SG_ 1347 VFCVectorZCUDMVFCid40 "VFC40";
CM_ SG_ 1347 VFCVectorZCUDMVFCid41 "InfotainmentPush";
CM_ SG_ 1347 VFCVectorZCUDMVFCid42 "ChargingHV";
CM_ SG_ 1347 VFCVectorZCUDMVFCid43 "BodyPreClimatisation";
CM_ SG_ 1347 VFCVectorZCUDMVFCid44 "Crash";
CM_ SG_ 1347 VFCVectorZCUDMVFCid45 "GlobalShortDuration";
CM_ SG_ 1347 VFCVectorZCUDMVFCid46 "ExteriorLightsHazard";
CM_ SG_ 1347 VFCVectorZCUDMVFCid47 "VFC47";
CM_ SG_ 1347 VFCVectorZCUDMVFCid48 "DoorOpenWarning";
CM_ SG_ 1347 VFCVectorZCUDMVFCid49 "ChargingLVInit";
CM_ SG_ 1347 VFCVectorZCUDMVFCid5 "VFC5";
CM_ SG_ 1347 VFCVectorZCUDMVFCid50 "VFC50";
CM_ SG_ 1347 VFCVectorZCUDMVFCid51 "VFC51";
CM_ SG_ 1347 VFCVectorZCUDMVFCid52 "HVBatteryThermalEventWarning";
CM_ SG_ 1347 VFCVectorZCUDMVFCid53 "VisualAssist";
CM_ SG_ 1347 VFCVectorZCUDMVFCid54 "PassiveSafety";
CM_ SG_ 1347 VFCVectorZCUDMVFCid55 "LifeDetection";
CM_ SG_ 1347 VFCVectorZCUDMVFCid56 "BackboneFlexray";
CM_ SG_ 1347 VFCVectorZCUDMVFCid57 "Functionmarket";
CM_ SG_ 1347 VFCVectorZCUDMVFCid58 "VFCid58";
CM_ SG_ 1347 VFCVectorZCUDMVFCid59 "VFCid59";
CM_ SG_ 1347 VFCVectorZCUDMVFCid6 "SettingsVehicle";
CM_ SG_ 1347 VFCVectorZCUDMVFCid60 "VFCid60";
CM_ SG_ 1347 VFCVectorZCUDMVFCid61 "VFCid61";
CM_ SG_ 1347 VFCVectorZCUDMVFCid7 "VFC7";
CM_ SG_ 1347 VFCVectorZCUDMVFCid8 "VFC8";
CM_ SG_ 1347 VFCVectorZCUDMVFCid9 "IPWakeup";
CM_ SG_ 1283 WakeUpReasonsforZCUDM "WakeUpReasons";
CM_ SG_ 530 LcmaLedStsPassSide "LED status in passenger side rear mirror";
CM_ SG_ 530 MirrFoldStsAtPass "Reports the fold status of the outer rear view mirrors. Passanger side.";
CM_ SG_ 530 WinPosnStsAtPass "Signal sent to inform the rest of the car of the window position status for the front passenger side door. The value of the signal is either an approximated percentage of openness, of the window is moving or if the position is unkown.
";
CM_ SG_ 530 WinPosnStsAtReRi "Signal sent to inform the rest of the car of the window position status for the rear passenger side door. The value of the signal is either an approximated percentage of openness, of the window is moving or if the position is unkown.
";
CM_ SG_ 271 DoorPassLockSts "DoorPassLockSts - Passenger Door Lock Status
Lock status
LockStsUkwn - Lock Status Unknown
Unlckd - Unlocked
Lockd - Locked
SafeLockd - Safe Locked (Double Locked)";
CM_ SG_ 271 DoorRiReLockSts "DoorRiReLockSts - Right Rear Door Lock Status
Lock status
LockStsUkwn - Lock Status Unknown
Unlckd - Unlocked
Lockd - Locked
SafeLockd - Safe Locked (Double Locked)";
CM_ SG_ 271 PassSeatSnsrSts2 "Informs if there is a fault on the Passenger seat sensor is detected through electrical measurements, or plausibility judgement. NotOk means sensor is judged as faulty. Di means that the sensor is not configured.";
CM_ SG_ 271 PassSeatSts2 "Describes if an occupant is detected in the passenger seat.";
CM_ SG_ 1349 VFCVectorZCUPBlockID "BlockID";
CM_ SG_ 1349 VFCVectorZCUPVFCid0 "SettingsComfort";
CM_ SG_ 1349 VFCVectorZCUPVFCid1 "ParkingDrivingClimatization";
CM_ SG_ 1349 VFCVectorZCUPVFCid10 "ExteriorLighting";
CM_ SG_ 1349 VFCVectorZCUPVFCid11 "VFC11";
CM_ SG_ 1349 VFCVectorZCUPVFCid12 "Alarm";
CM_ SG_ 1349 VFCVectorZCUPVFCid13 "VFC13";
CM_ SG_ 1349 VFCVectorZCUPVFCid14 "InteriorLighting";
CM_ SG_ 1349 VFCVectorZCUPVFCid15 "VFC15";
CM_ SG_ 1349 VFCVectorZCUPVFCid16 "Locking";
CM_ SG_ 1349 VFCVectorZCUPVFCid17 "RemoteKeyFunctionality";
CM_ SG_ 1349 VFCVectorZCUPVFCid18 "PropulsionStart";
CM_ SG_ 1349 VFCVectorZCUPVFCid19 "VFC19";
CM_ SG_ 1349 VFCVectorZCUPVFCid2 "PostClimatisation";
CM_ SG_ 1349 VFCVectorZCUPVFCid20 "VFC20";
CM_ SG_ 1349 VFCVectorZCUPVFCid21 "PowerClosures";
CM_ SG_ 1349 VFCVectorZCUPVFCid22 "VehicleDriving";
CM_ SG_ 1349 VFCVectorZCUPVFCid23 "VFCid23";
CM_ SG_ 1349 VFCVectorZCUPVFCid24 "SettingsProfile";
CM_ SG_ 1349 VFCVectorZCUPVFCid25 "SeatComfortFunctions";
CM_ SG_ 1349 VFCVectorZCUPVFCid26 "Brake";
CM_ SG_ 1349 VFCVectorZCUPVFCid27 "InfotainmentPoll";
CM_ SG_ 1349 VFCVectorZCUPVFCid28 "HVEnergyStorage";
CM_ SG_ 1349 VFCVectorZCUPVFCid29 "VFC29";
CM_ SG_ 1349 VFCVectorZCUPVFCid3 "PowertrainParkingClimatization";
CM_ SG_ 1349 VFCVectorZCUPVFCid30 "TelematicsConnectivity";
CM_ SG_ 1349 VFCVectorZCUPVFCid31 "VFC31";
CM_ SG_ 1349 VFCVectorZCUPVFCid32 "VFC32";
CM_ SG_ 1349 VFCVectorZCUPVFCid33 "Diagnostics";
CM_ SG_ 1349 VFCVectorZCUPVFCid34 "VehicleModeManagement";
CM_ SG_ 1349 VFCVectorZCUPVFCid35 "TrailerCaravanFunctions";
CM_ SG_ 1349 VFCVectorZCUPVFCid36 "Immobilizer";
CM_ SG_ 1349 VFCVectorZCUPVFCid37 "Windows";
CM_ SG_ 1349 VFCVectorZCUPVFCid38 "Visibility";
CM_ SG_ 1349 VFCVectorZCUPVFCid39 "VFC39";
CM_ SG_ 1349 VFCVectorZCUPVFCid4 "VFC4";
CM_ SG_ 1349 VFCVectorZCUPVFCid40 "VFC40";
CM_ SG_ 1349 VFCVectorZCUPVFCid41 "InfotainmentPush";
CM_ SG_ 1349 VFCVectorZCUPVFCid42 "ChargingHV";
CM_ SG_ 1349 VFCVectorZCUPVFCid43 "BodyPreClimatisation";
CM_ SG_ 1349 VFCVectorZCUPVFCid44 "Crash";
CM_ SG_ 1349 VFCVectorZCUPVFCid45 "GlobalShortDuration";
CM_ SG_ 1349 VFCVectorZCUPVFCid46 "ExteriorLightsHazard";
CM_ SG_ 1349 VFCVectorZCUPVFCid47 "VFC47";
CM_ SG_ 1349 VFCVectorZCUPVFCid48 "DoorOpenWarning";
CM_ SG_ 1349 VFCVectorZCUPVFCid49 "ChargingLVInit";
CM_ SG_ 1349 VFCVectorZCUPVFCid5 "VFC5";
CM_ SG_ 1349 VFCVectorZCUPVFCid50 "VFC50";
CM_ SG_ 1349 VFCVectorZCUPVFCid51 "VFC51";
CM_ SG_ 1349 VFCVectorZCUPVFCid52 "HVBatteryThermalEventWarning";
CM_ SG_ 1349 VFCVectorZCUPVFCid53 "VisualAssist";
CM_ SG_ 1349 VFCVectorZCUPVFCid54 "PassiveSafety";
CM_ SG_ 1349 VFCVectorZCUPVFCid55 "LifeDetection";
CM_ SG_ 1349 VFCVectorZCUPVFCid56 "BackboneFlexray";
CM_ SG_ 1349 VFCVectorZCUPVFCid57 "Functionmarket";
CM_ SG_ 1349 VFCVectorZCUPVFCid58 "VFCid58";
CM_ SG_ 1349 VFCVectorZCUPVFCid59 "VFCid59";
CM_ SG_ 1349 VFCVectorZCUPVFCid6 "SettingsVehicle";
CM_ SG_ 1349 VFCVectorZCUPVFCid60 "VFCid60";
CM_ SG_ 1349 VFCVectorZCUPVFCid61 "VFCid61";
CM_ SG_ 1349 VFCVectorZCUPVFCid7 "VFCid7";
CM_ SG_ 1349 VFCVectorZCUPVFCid8 "VFCid8";
CM_ SG_ 1349 VFCVectorZCUPVFCid9 "IPWakeup";
CM_ SG_ 1285 WakeUpReasonsforZCUP "WakeUpReasons";
BA_DEF_ BO_ "CANFD_BRS" ENUM "0","1";
BA_DEF_ BO_ "GenMsgCycleTime" INT 0 65536;
BA_DEF_ BO_ "GenMsgDelayTime" INT 0 65536;
BA_DEF_ BO_ "GenMsgSendType" ENUM "cyclic", "spontaneous", "not-used", "not-used", "not-used", "cyclicAndSpontaneous", "not-used", "cyclicIfActive", "NoMsgSendType";
BA_DEF_ BO_ "GenMsgStartDelayTime" INT 0 65536;
BA_DEF_ BO_ "VFrameFormat" ENUM "StandardCAN","ExtendedCAN","reserved","J1939PG","reserved","reserved","reserved","reserved","reserved","reserved","reserved","reserved","reserved","reserved","StandardCAN_FD","ExtendedCAN_FD";
BA_DEF_ SG_ "GenSigSendType" ENUM "Cyclic","OnWrite","OnWriteWithRepetition","OnChange","OnChangeWithRepetition","IfActive","IfActiveWithRepetition","NoSigSendType";
BA_DEF_ SG_ "GenSigStartValue" HEX 0 80000000;
BA_DEF_ BO_ "GenMsgILSupport" ENUM "No","Yes";
BA_DEF_ BO_ "NmAsrMessage" ENUM "No","Yes";
BA_DEF_ SG_ "GenSigFuncType" ENUM "NoFunction","n/a","n/a","n/a","n/a","n/a","n/a","n/a","n/a","n/a","n/a","n/a","n/a","n/a","n/a","CHK","CNTR","n/a","n/a","n/a","CNTR_AR_01","CRC_AR_01_BOTH","CRC_AR_01_ALT","CRC_AR_01_LOW","CRC_AR_01_NIBBLE","CNTR_AR_04","CRC_AR_04A","CNTR_AR_05","CRC_AR_05";
BA_DEF_ SG_ "GenSigDataID" STRING;
BA_DEF_ SG_ "SigGroup" STRING;
BA_DEF_DEF_ "CANFD_BRS" "1";
BA_DEF_DEF_ "GenSigStartValue" 0;
BA_DEF_DEF_ "VFrameFormat" "J1939PG";
BA_DEF_DEF_ "GenSigSendType" "NoSigSendType";
BA_DEF_DEF_ "GenMsgCycleTime" 0;
BA_DEF_DEF_ "GenMsgDelayTime" 0;
BA_DEF_DEF_ "GenMsgStartDelayTime" 0;
BA_DEF_DEF_ "GenMsgSendType" "NoMsgSendType";
BA_DEF_DEF_ "GenMsgILSupport" "Yes";
BA_DEF_DEF_ "NmAsrMessage" "No";
BA_DEF_DEF_ "GenSigFuncType" "NoFunction";
BA_DEF_DEF_ "GenSigDataID" "";
BA_DEF_DEF_ "SigGroup" "";

BA_ "GenMsgCycleTime" BO_ 1347 500.000;
BA_ "GenMsgSendType" BO_ 1347 0;
BA_ "VFrameFormat" BO_ 1347 0;

BA_ "GenMsgDelayTime" BO_ 1570 5.000;
BA_ "GenMsgSendType" BO_ 1570 1;
BA_ "VFrameFormat" BO_ 1570 14;

BA_ "GenMsgDelayTime" BO_ 1554 5.000;
BA_ "GenMsgSendType" BO_ 1554 1;
BA_ "VFrameFormat" BO_ 1554 14;

BA_ "GenMsgCycleTime" BO_ 97 10.000;
BA_ "GenMsgSendType" BO_ 97 0;
BA_ "VFrameFormat" BO_ 97 14;

BA_ "GenMsgCycleTime" BO_ 261 20.000;
BA_ "GenMsgSendType" BO_ 261 0;
BA_ "VFrameFormat" BO_ 261 14;

BA_ "GenMsgCycleTime" BO_ 851 150.000;
BA_ "GenMsgSendType" BO_ 851 0;
BA_ "VFrameFormat" BO_ 851 14;

BA_ "GenMsgCycleTime" BO_ 545 100.000;
BA_ "GenMsgSendType" BO_ 545 0;
BA_ "VFrameFormat" BO_ 545 14;

BA_ "GenMsgCycleTime" BO_ 579 70.000;
BA_ "GenMsgSendType" BO_ 579 0;
BA_ "VFrameFormat" BO_ 579 14;

BA_ "GenMsgCycleTime" BO_ 451 40.000;
BA_ "GenMsgSendType" BO_ 451 0;
BA_ "VFrameFormat" BO_ 451 14;

BA_ "GenMsgCycleTime" BO_ 867 300.000;
BA_ "GenMsgSendType" BO_ 867 0;
BA_ "VFrameFormat" BO_ 867 14;

BA_ "GenMsgCycleTime" BO_ 931 400.000;
BA_ "GenMsgSendType" BO_ 931 0;
BA_ "VFrameFormat" BO_ 931 14;

BA_ "GenMsgCycleTime" BO_ 83 10.000;
BA_ "GenMsgSendType" BO_ 83 0;
BA_ "VFrameFormat" BO_ 83 14;

BA_ "GenMsgCycleTime" BO_ 837 200.000;
BA_ "GenMsgSendType" BO_ 837 0;
BA_ "VFrameFormat" BO_ 837 14;

BA_ "GenMsgDelayTime" BO_ 1283 20.000;
BA_ "GenMsgSendType" BO_ 1283 1;
BA_ "VFrameFormat" BO_ 1283 0;

BA_ "GenMsgCycleTime" BO_ 530 60.000;
BA_ "GenMsgSendType" BO_ 530 0;
BA_ "VFrameFormat" BO_ 530 14;

BA_ "GenMsgCycleTime" BO_ 271 20.000;
BA_ "GenMsgSendType" BO_ 271 0;
BA_ "VFrameFormat" BO_ 271 14;

BA_ "GenMsgCycleTime" BO_ 1349 500.000;
BA_ "GenMsgSendType" BO_ 1349 0;
BA_ "VFrameFormat" BO_ 1349 0;

BA_ "GenMsgDelayTime" BO_ 1285 20.000;
BA_ "GenMsgSendType" BO_ 1285 1;
BA_ "VFrameFormat" BO_ 1285 0;
BA_ "GenMsgILSupport" BO_ 1283 0;
BA_ "GenMsgILSupport" BO_ 1285 0;
BA_ "NmAsrMessage" BO_ 1283 1;
BA_ "NmAsrMessage" BO_ 1285 1;
BA_ "GenSigSendType" SG_ 451 AD4HeatingCircTestSts 0;
BA_ "GenSigSendType" SG_ 97 ADModCtrlInhbnADModCtrlInhbn 0;
BA_ "GenSigDataID" SG_ 97 ADModCtrlInhbnChks "0x3E";
BA_ "GenSigFuncType" SG_ 97 ADModCtrlInhbnChks 15;
BA_ "GenSigSendType" SG_ 97 ADModCtrlInhbnChks 0;
BA_ "GenSigFuncType" SG_ 97 ADModCtrlInhbnCntr 16;
BA_ "GenSigSendType" SG_ 97 ADModCtrlInhbnCntr 0;
BA_ "GenSigSendType" SG_ 97 ADataRawSafeALat 0;
BA_ "GenSigSendType" SG_ 97 ADataRawSafeALat1Qf 0;
BA_ "GenSigStartValue" SG_ 97 ADataRawSafeALat1Qf 1;
BA_ "GenSigSendType" SG_ 97 ADataRawSafeALgt 0;
BA_ "GenSigSendType" SG_ 97 ADataRawSafeALgt1Qf 0;
BA_ "GenSigStartValue" SG_ 97 ADataRawSafeALgt1Qf 1;
BA_ "GenSigSendType" SG_ 97 ADataRawSafeAVert 0;
BA_ "GenSigStartValue" SG_ 97 ADataRawSafeAVert 1155;
BA_ "GenSigSendType" SG_ 97 ADataRawSafeAVertQf 0;
BA_ "GenSigStartValue" SG_ 97 ADataRawSafeAVertQf 1;
BA_ "GenSigDataID" SG_ 97 ADataRawSafeChks "0x22";
BA_ "GenSigFuncType" SG_ 97 ADataRawSafeChks 15;
BA_ "GenSigSendType" SG_ 97 ADataRawSafeChks 0;
BA_ "GenSigStartValue" SG_ 97 ADataRawSafeChks 255;
BA_ "GenSigFuncType" SG_ 97 ADataRawSafeCntr 16;
BA_ "GenSigSendType" SG_ 97 ADataRawSafeCntr 0;
BA_ "GenSigSendType" SG_ 83 AccrPedlRatAccrPedlRat 0;
BA_ "GenSigDataID" SG_ 83 AccrPedlRatChks "0x364";
BA_ "GenSigFuncType" SG_ 83 AccrPedlRatChks 15;
BA_ "GenSigSendType" SG_ 83 AccrPedlRatChks 0;
BA_ "GenSigFuncType" SG_ 83 AccrPedlRatCntr 16;
BA_ "GenSigSendType" SG_ 83 AccrPedlRatCntr 0;
BA_ "GenSigSendType" SG_ 97 ActvnOfWelcomeLi 0;
BA_ "GenSigSendType" SG_ 451 AdjSpdLimnFusnTrfcSgn 0;
BA_ "GenSigDataID" SG_ 97 AgDataRaw2SafeChks "0x404";
BA_ "GenSigFuncType" SG_ 97 AgDataRaw2SafeChks 15;
BA_ "GenSigSendType" SG_ 97 AgDataRaw2SafeChks 0;
BA_ "GenSigStartValue" SG_ 97 AgDataRaw2SafeChks 255;
BA_ "GenSigFuncType" SG_ 97 AgDataRaw2SafeCntr 16;
BA_ "GenSigSendType" SG_ 97 AgDataRaw2SafeCntr 0;
BA_ "GenSigSendType" SG_ 97 AgDataRaw2SafePitchRate 0;
BA_ "GenSigSendType" SG_ 97 AgDataRaw2SafePitchRateQf 0;
BA_ "GenSigStartValue" SG_ 97 AgDataRaw2SafePitchRateQf 1;
BA_ "GenSigDataID" SG_ 97 AgDataRawSafeChks "0x23";
BA_ "GenSigFuncType" SG_ 97 AgDataRawSafeChks 15;
BA_ "GenSigSendType" SG_ 97 AgDataRawSafeChks 0;
BA_ "GenSigStartValue" SG_ 97 AgDataRawSafeChks 255;
BA_ "GenSigFuncType" SG_ 97 AgDataRawSafeCntr 16;
BA_ "GenSigSendType" SG_ 97 AgDataRawSafeCntr 0;
BA_ "GenSigSendType" SG_ 97 AgDataRawSafeRollRate 0;
BA_ "GenSigSendType" SG_ 97 AgDataRawSafeRollRateQf 0;
BA_ "GenSigStartValue" SG_ 97 AgDataRawSafeRollRateQf 1;
BA_ "GenSigSendType" SG_ 97 AgDataRawSafeYawRate 0;
BA_ "GenSigSendType" SG_ 97 AgDataRawSafeYawRateQf 0;
BA_ "GenSigStartValue" SG_ 97 AgDataRawSafeYawRateQf 1;
BA_ "GenSigSendType" SG_ 261 AlrmStsAlrmFailr 0;
BA_ "GenSigSendType" SG_ 261 AlrmStsAlrmSt 0;
BA_ "GenSigSendType" SG_ 261 AlrmStsAlrmTrgSrc 0;
BA_ "GenSigSendType" SG_ 261 AlrmStsSnsrInclnFailr 0;
BA_ "GenSigSendType" SG_ 261 AlrmStsSnsrIntrScanrFailr 0;
BA_ "GenSigSendType" SG_ 97 AmbTRawAmbTVal 0;
BA_ "GenSigStartValue" SG_ 97 AmbTRawAmbTVal 700;
BA_ "GenSigSendType" SG_ 97 AmbTRawQly 0;
BA_ "GenSigSendType" SG_ 97 AsyDataWithCmpSafeALat1Qf 0;
BA_ "GenSigStartValue" SG_ 97 AsyDataWithCmpSafeALat1Qf 1;
BA_ "GenSigSendType" SG_ 97 AsyDataWithCmpSafeALatWithCmp 0;
BA_ "GenSigSendType" SG_ 97 AsyDataWithCmpSafeALgt1Qf 0;
BA_ "GenSigStartValue" SG_ 97 AsyDataWithCmpSafeALgt1Qf 1;
BA_ "GenSigDataID" SG_ 97 AsyDataWithCmpSafeChks "0x24";
BA_ "GenSigFuncType" SG_ 97 AsyDataWithCmpSafeChks 15;
BA_ "GenSigSendType" SG_ 97 AsyDataWithCmpSafeChks 0;
BA_ "GenSigStartValue" SG_ 97 AsyDataWithCmpSafeChks 255;
BA_ "GenSigFuncType" SG_ 97 AsyDataWithCmpSafeCntr 16;
BA_ "GenSigSendType" SG_ 97 AsyDataWithCmpSafeCntr 0;
BA_ "GenSigSendType" SG_ 97 AsyDataWithCmpSafeGrdtOfALgt 0;
BA_ "GenSigSendType" SG_ 97 AsyDataWithCmpSafeYawRateQf 0;
BA_ "GenSigStartValue" SG_ 97 AsyDataWithCmpSafeYawRateQf 1;
BA_ "GenSigSendType" SG_ 97 AsyDataWithCmpSafeYawRateWithCmp 0;
BA_ "GenSigSendType" SG_ 83 BltLockStAtDrvrBltLockSt1 0;
BA_ "GenSigStartValue" SG_ 83 BltLockStAtDrvrBltLockSt1 1;
BA_ "GenSigSendType" SG_ 83 BltLockStAtDrvrBltLockSts 0;
BA_ "GenSigSendType" SG_ 545 BltLockStAtPassBltLockSt1 0;
BA_ "GenSigStartValue" SG_ 545 BltLockStAtPassBltLockSt1 1;
BA_ "GenSigSendType" SG_ 545 BltLockStAtPassBltLockSts 0;
BA_ "GenSigSendType" SG_ 851 BltLockStAtRowSecLeBltLockEquid 0;
BA_ "GenSigStartValue" SG_ 851 BltLockStAtRowSecLeBltLockEquid 1;
BA_ "GenSigSendType" SG_ 851 BltLockStAtRowSecLeBltLockSt1 0;
BA_ "GenSigSendType" SG_ 851 BltLockStAtRowSecLeBltLockSts 0;
BA_ "GenSigStartValue" SG_ 851 BltLockStAtRowSecLeBltLockSts 1;
BA_ "GenSigSendType" SG_ 851 BltLockStAtRowSecMidBltLockEquid 0;
BA_ "GenSigStartValue" SG_ 851 BltLockStAtRowSecMidBltLockEquid 1;
BA_ "GenSigSendType" SG_ 851 BltLockStAtRowSecMidBltLockSt1 0;
BA_ "GenSigSendType" SG_ 851 BltLockStAtRowSecMidBltLockSts 0;
BA_ "GenSigStartValue" SG_ 851 BltLockStAtRowSecMidBltLockSts 1;
BA_ "GenSigSendType" SG_ 851 BltLockStAtRowSecRiBltLockEquid 0;
BA_ "GenSigStartValue" SG_ 851 BltLockStAtRowSecRiBltLockEquid 1;
BA_ "GenSigSendType" SG_ 851 BltLockStAtRowSecRiBltLockSt1 0;
BA_ "GenSigSendType" SG_ 851 BltLockStAtRowSecRiBltLockSts 0;
BA_ "GenSigStartValue" SG_ 851 BltLockStAtRowSecRiBltLockSts 1;
BA_ "GenSigSendType" SG_ 851 BltLockStAtRowThrdLeBltLockEquid 0;
BA_ "GenSigStartValue" SG_ 851 BltLockStAtRowThrdLeBltLockEquid 1;
BA_ "GenSigSendType" SG_ 851 BltLockStAtRowThrdLeBltLockSt1 0;
BA_ "GenSigSendType" SG_ 851 BltLockStAtRowThrdLeBltLockSts 0;
BA_ "GenSigStartValue" SG_ 851 BltLockStAtRowThrdLeBltLockSts 1;
BA_ "GenSigSendType" SG_ 851 BltLockStAtRowThrdRiBltLockEquid 0;
BA_ "GenSigStartValue" SG_ 851 BltLockStAtRowThrdRiBltLockEquid 1;
BA_ "GenSigSendType" SG_ 851 BltLockStAtRowThrdRiBltLockSt1 0;
BA_ "GenSigSendType" SG_ 851 BltLockStAtRowThrdRiBltLockSts 0;
BA_ "GenSigStartValue" SG_ 851 BltLockStAtRowThrdRiBltLockSts 1;
BA_ "GenSigSendType" SG_ 261 BltLockStSafeAtDrvrBltLockSt1 0;
BA_ "GenSigStartValue" SG_ 261 BltLockStSafeAtDrvrBltLockSt1 1;
BA_ "GenSigSendType" SG_ 261 BltLockStSafeAtDrvrBltLockStErrSts 0;
BA_ "GenSigDataID" SG_ 261 BltLockStSafeAtDrvrChks "0x40C";
BA_ "GenSigFuncType" SG_ 261 BltLockStSafeAtDrvrChks 15;
BA_ "GenSigSendType" SG_ 261 BltLockStSafeAtDrvrChks 0;
BA_ "GenSigStartValue" SG_ 261 BltLockStSafeAtDrvrChks 255;
BA_ "GenSigFuncType" SG_ 261 BltLockStSafeAtDrvrCntr 16;
BA_ "GenSigSendType" SG_ 261 BltLockStSafeAtDrvrCntr 0;
BA_ "GenSigDataID" SG_ 97 BrkPedlSnsrChks "0xAF";
BA_ "GenSigFuncType" SG_ 97 BrkPedlSnsrChks 15;
BA_ "GenSigSendType" SG_ 97 BrkPedlSnsrChks 0;
BA_ "GenSigFuncType" SG_ 97 BrkPedlSnsrCntr 16;
BA_ "GenSigSendType" SG_ 97 BrkPedlSnsrCntr 0;
BA_ "GenSigSendType" SG_ 97 BrkPedlSnsrQf 0;
BA_ "GenSigSendType" SG_ 97 BrkPedlSnsrSt 0;
BA_ "GenSigSendType" SG_ 97 BrkPedlSts 0;
BA_ "GenSigSendType" SG_ 261 BrkPedlValBrkPedlVal 0;
BA_ "GenSigSendType" SG_ 261 BrkPedlValQf 0;
BA_ "GenSigStartValue" SG_ 261 BrkPedlValQf 1;
BA_ "GenSigSendType" SG_ 851 BtnLockSts1BtnSts2 0;
BA_ "GenSigSendType" SG_ 851 BtnLockSts1KeyId 0;
BA_ "GenSigSendType" SG_ 851 BtnTrSts1BtnSts2 0;
BA_ "GenSigSendType" SG_ 851 BtnTrSts1KeyId 0;
BA_ "GenSigSendType" SG_ 851 BtnUnlckSts1BtnSts2 0;
BA_ "GenSigSendType" SG_ 851 BtnUnlckSts1KeyId 0;
BA_ "GenSigSendType" SG_ 97 CarTiGlb 0;
BA_ "GenSigSendType" SG_ 97 CrsCtrlOvrdn 0;
BA_ "GenSigSendType" SG_ 97 CrsCtrlrMsg 0;
BA_ "GenSigSendType" SG_ 97 CrsCtrlrStbOk 0;
BA_ "GenSigSendType" SG_ 97 CrsCtrlrSts 0;
BA_ "GenSigStartValue" SG_ 97 CrsCtrlrSts 1;
BA_ "GenSigSendType" SG_ 851 DCChrgnHndlSts 0;
BA_ "GenSigSendType" SG_ 579 DcDcActvd 0;
BA_ "GenSigSendType" SG_ 931 DispHvBattLvlOfChrg 0;
BA_ "GenSigSendType" SG_ 97 DoorDrvrLockCmd 0;
BA_ "GenSigSendType" SG_ 83 DoorDrvrLockSts 0;
BA_ "GenSigSendType" SG_ 261 DoorDrvrSts 0;
BA_ "GenSigSendType" SG_ 261 DoorDrvrStsWithFacQlyDoorSts 0;
BA_ "GenSigSendType" SG_ 261 DoorDrvrStsWithFacQlyFacQly 0;
BA_ "GenSigStartValue" SG_ 261 DoorDrvrStsWithFacQlyFacQly 1;
BA_ "GenSigSendType" SG_ 83 DoorLeReLockSts 0;
BA_ "GenSigSendType" SG_ 261 DoorLeReSts 0;
BA_ "GenSigSendType" SG_ 271 DoorPassLockSts 0;
BA_ "GenSigSendType" SG_ 261 DoorPassSts 0;
BA_ "GenSigSendType" SG_ 271 DoorRiReLockSts 0;
BA_ "GenSigSendType" SG_ 261 DoorRiReSts 0;
BA_ "GenSigSendType" SG_ 97 DrvrDesDirChks 0;
BA_ "GenSigSendType" SG_ 97 DrvrDesDirCntr 0;
BA_ "GenSigSendType" SG_ 97 DrvrDesDirDrvrDesDir 0;
BA_ "GenSigDataID" SG_ 97 DrvrGearShiftDirReq1Chks "0x39";
BA_ "GenSigFuncType" SG_ 97 DrvrGearShiftDirReq1Chks 15;
BA_ "GenSigSendType" SG_ 97 DrvrGearShiftDirReq1Chks 0;
BA_ "GenSigFuncType" SG_ 97 DrvrGearShiftDirReq1Cntr 16;
BA_ "GenSigSendType" SG_ 97 DrvrGearShiftDirReq1Cntr 0;
BA_ "GenSigSendType" SG_ 97 DrvrGearShiftDirReq1DwnDwnTipAut 0;
BA_ "GenSigSendType" SG_ 97 DrvrGearShiftDirReq1DwnTipAut 0;
BA_ "GenSigSendType" SG_ 97 DrvrGearShiftDirReq1PosnAut 0;
BA_ "GenSigSendType" SG_ 97 DrvrGearShiftDirReq1UpTipAut 0;
BA_ "GenSigSendType" SG_ 97 DrvrGearShiftDirReq1UpUpTipAut 0;
BA_ "GenSigDataID" SG_ 97 DrvrGearShiftDirReq2Chks "0x62";
BA_ "GenSigFuncType" SG_ 97 DrvrGearShiftDirReq2Chks 15;
BA_ "GenSigSendType" SG_ 97 DrvrGearShiftDirReq2Chks 0;
BA_ "GenSigFuncType" SG_ 97 DrvrGearShiftDirReq2Cntr 16;
BA_ "GenSigSendType" SG_ 97 DrvrGearShiftDirReq2Cntr 0;
BA_ "GenSigSendType" SG_ 97 DrvrGearShiftDirReq2DwnDwnTipAut 0;
BA_ "GenSigSendType" SG_ 97 DrvrGearShiftDirReq2DwnTipAut 0;
BA_ "GenSigSendType" SG_ 97 DrvrGearShiftDirReq2PosnAut 0;
BA_ "GenSigSendType" SG_ 97 DrvrGearShiftDirReq2UpTipAut 0;
BA_ "GenSigSendType" SG_ 97 DrvrGearShiftDirReq2UpUpTipAut 0;
BA_ "GenSigSendType" SG_ 83 DrvrGearShiftParkReq1 0;
BA_ "GenSigDataID" SG_ 83 DrvrGearShiftParkReqChks "0x20F";
BA_ "GenSigFuncType" SG_ 83 DrvrGearShiftParkReqChks 15;
BA_ "GenSigSendType" SG_ 83 DrvrGearShiftParkReqChks 0;
BA_ "GenSigFuncType" SG_ 83 DrvrGearShiftParkReqCntr 16;
BA_ "GenSigSendType" SG_ 83 DrvrGearShiftParkReqCntr 0;
BA_ "GenSigSendType" SG_ 83 DrvrGearShiftParkReqSts 0;
BA_ "GenSigSendType" SG_ 261 DrvrPrsntStsDrvrPrsnt 0;
BA_ "GenSigDataID" SG_ 261 DrvrPrsntStsDrvrPrsntChks "0x79";
BA_ "GenSigFuncType" SG_ 261 DrvrPrsntStsDrvrPrsntChks 15;
BA_ "GenSigSendType" SG_ 261 DrvrPrsntStsDrvrPrsntChks 0;
BA_ "GenSigFuncType" SG_ 261 DrvrPrsntStsDrvrPrsntCntr 16;
BA_ "GenSigSendType" SG_ 261 DrvrPrsntStsDrvrPrsntCntr 0;
BA_ "GenSigSendType" SG_ 261 DrvrPrsntStsDrvrPrsntQf 0;
BA_ "GenSigSendType" SG_ 837 EPBLockMgrReqCmd 0;
BA_ "GenSigSendType" SG_ 837 EPBLockMgrReqData0 0;
BA_ "GenSigSendType" SG_ 837 EPBLockMgrReqData1 0;
BA_ "GenSigSendType" SG_ 837 EPBLockMgrReqData2 0;
BA_ "GenSigSendType" SG_ 837 EPBLockMgrReqData3 0;
BA_ "GenSigSendType" SG_ 837 EPBLockMgrReqData4 0;
BA_ "GenSigSendType" SG_ 837 EPBLockMgrReqData5 0;
BA_ "GenSigSendType" SG_ 837 EPBLockMgrReqData6 0;
BA_ "GenSigDataID" SG_ 83 EngSt1WdStsChks "0x89";
BA_ "GenSigFuncType" SG_ 83 EngSt1WdStsChks 15;
BA_ "GenSigSendType" SG_ 83 EngSt1WdStsChks 0;
BA_ "GenSigFuncType" SG_ 83 EngSt1WdStsCntr 16;
BA_ "GenSigSendType" SG_ 83 EngSt1WdStsCntr 0;
BA_ "GenSigSendType" SG_ 83 EngSt1WdStsEngSt1WdSts 0;
BA_ "GenSigStartValue" SG_ 451 EngTEngT 50;
BA_ "GenSigSendType" SG_ 97 EpbActrStSec 0;
BA_ "GenSigStartValue" SG_ 97 EpbActrStSec 4;
BA_ "GenSigSendType" SG_ 97 ExtrLiRlyPwrDwn 0;
BA_ "GenSigSendType" SG_ 451 ExtrLtgStsAFS 0;
BA_ "GenSigSendType" SG_ 451 ExtrLtgStsAHBC 0;
BA_ "GenSigSendType" SG_ 451 ExtrLtgStsAHL 0;
BA_ "GenSigSendType" SG_ 451 ExtrLtgStsAllWL 0;
BA_ "GenSigSendType" SG_ 451 ExtrLtgStsApproach 0;
BA_ "GenSigDataID" SG_ 451 ExtrLtgStsChks "0x44C";
BA_ "GenSigFuncType" SG_ 451 ExtrLtgStsChks 15;
BA_ "GenSigSendType" SG_ 451 ExtrLtgStsChks 0;
BA_ "GenSigFuncType" SG_ 451 ExtrLtgStsCntr 16;
BA_ "GenSigSendType" SG_ 451 ExtrLtgStsCntr 0;
BA_ "GenSigSendType" SG_ 451 ExtrLtgStsCornrgLi 0;
BA_ "GenSigSendType" SG_ 451 ExtrLtgStsDBL 0;
BA_ "GenSigSendType" SG_ 451 ExtrLtgStsDRL 0;
BA_ "GenSigSendType" SG_ 451 ExtrLtgStsFlash 0;
BA_ "GenSigSendType" SG_ 451 ExtrLtgStsFrntFog 0;
BA_ "GenSigSendType" SG_ 451 ExtrLtgStsGoodbye 0;
BA_ "GenSigSendType" SG_ 451 ExtrLtgStsHWL 0;
BA_ "GenSigSendType" SG_ 451 ExtrLtgStsHiBeam 0;
BA_ "GenSigSendType" SG_ 451 ExtrLtgStsHomeSafe 0;
BA_ "GenSigSendType" SG_ 451 ExtrLtgStsLoBeam 0;
BA_ "GenSigSendType" SG_ 451 ExtrLtgStsLtgShow 0;
BA_ "GenSigSendType" SG_ 451 ExtrLtgStsPosLiFrnt 0;
BA_ "GenSigSendType" SG_ 451 ExtrLtgStsPosLiRe 0;
BA_ "GenSigSendType" SG_ 451 ExtrLtgStsReFog 0;
BA_ "GenSigSendType" SG_ 451 ExtrLtgStsReverseLi 0;
BA_ "GenSigSendType" SG_ 451 ExtrLtgStsStopLi 0;
BA_ "GenSigSendType" SG_ 451 ExtrLtgStsTurnIndrLe 0;
BA_ "GenSigSendType" SG_ 451 ExtrLtgStsTurnIndrRi 0;
BA_ "GenSigSendType" SG_ 451 ExtrLtgStsWelcome 0;
BA_ "GenSigSendType" SG_ 261 GearLvrIndcn 0;
BA_ "GenSigStartValue" SG_ 261 GearLvrIndcn 7;
BA_ "GenSigSendType" SG_ 261 GearMov 0;
BA_ "GenSigStartValue" SG_ 261 GearMov 2;
BA_ "GenSigSendType" SG_ 97 GearMovmtFlg 0;
BA_ "GenSigSendType" SG_ 261 HoodSts 0;
BA_ "GenSigSendType" SG_ 579 HvBattSoc 0;
BA_ "GenSigSendType" SG_ 261 IndcrDisp 0;
BA_ "GenSigSendType" SG_ 261 IndcrSts 0;
BA_ "GenSigSendType" SG_ 867 JIDByte0 0;
BA_ "GenSigStartValue" SG_ 867 JIDByte0 255;
BA_ "GenSigSendType" SG_ 867 JIDByte1 0;
BA_ "GenSigStartValue" SG_ 867 JIDByte1 255;
BA_ "GenSigSendType" SG_ 867 JIDByte2 0;
BA_ "GenSigStartValue" SG_ 867 JIDByte2 255;
BA_ "GenSigSendType" SG_ 867 JIDByte3 0;
BA_ "GenSigStartValue" SG_ 867 JIDByte3 255;
BA_ "GenSigSendType" SG_ 867 JIDByte4 0;
BA_ "GenSigStartValue" SG_ 867 JIDByte4 255;
BA_ "GenSigSendType" SG_ 867 JIDByte5 0;
BA_ "GenSigStartValue" SG_ 867 JIDByte5 255;
BA_ "GenSigSendType" SG_ 867 JIDByte6 0;
BA_ "GenSigStartValue" SG_ 867 JIDByte6 255;
BA_ "GenSigSendType" SG_ 867 JIDByte7 0;
BA_ "GenSigStartValue" SG_ 867 JIDByte7 255;
BA_ "GenSigSendType" SG_ 545 KeyDistncStsKey0 0;
BA_ "GenSigStartValue" SG_ 545 KeyDistncStsKey0 1023;
BA_ "GenSigSendType" SG_ 545 KeyDistncStsKey1 0;
BA_ "GenSigStartValue" SG_ 545 KeyDistncStsKey1 1023;
BA_ "GenSigSendType" SG_ 545 KeyDistncStsKey2 0;
BA_ "GenSigStartValue" SG_ 545 KeyDistncStsKey2 1023;
BA_ "GenSigSendType" SG_ 545 KeyDistncStsKey3 0;
BA_ "GenSigStartValue" SG_ 545 KeyDistncStsKey3 1023;
BA_ "GenSigSendType" SG_ 545 KeyDistncStsKey4 0;
BA_ "GenSigStartValue" SG_ 545 KeyDistncStsKey4 1023;
BA_ "GenSigSendType" SG_ 545 KeyDistncStsKey5 0;
BA_ "GenSigStartValue" SG_ 545 KeyDistncStsKey5 1023;
BA_ "GenSigSendType" SG_ 83 LcmaLedStsDrvrSide 0;
BA_ "GenSigStartValue" SG_ 83 LcmaLedStsDrvrSide 1;
BA_ "GenSigSendType" SG_ 530 LcmaLedStsPassSide 0;
BA_ "GenSigStartValue" SG_ 530 LcmaLedStsPassSide 1;
BA_ "GenSigSendType" SG_ 579 LeFrntTireMsgBattLoSt 0;
BA_ "GenSigSendType" SG_ 579 LeFrntTireMsgFastLoseWarnFlg 0;
BA_ "GenSigSendType" SG_ 579 LeFrntTireMsgMsgOldFlg 0;
BA_ "GenSigSendType" SG_ 579 LeFrntTireMsgP 0;
BA_ "GenSigStartValue" SG_ 579 LeFrntTireMsgP 255;
BA_ "GenSigSendType" SG_ 579 LeFrntTireMsgPWarnFlg 0;
BA_ "GenSigSendType" SG_ 579 LeFrntTireMsgSysWarnFlg 0;
BA_ "GenSigSendType" SG_ 579 LeFrntTireMsgT 0;
BA_ "GenSigStartValue" SG_ 579 LeFrntTireMsgT 255;
BA_ "GenSigSendType" SG_ 579 LeFrntTireMsgTWarnFlg 0;
BA_ "GenSigSendType" SG_ 579 LeFrntTireMsgTireFillgAssiPSts 0;
BA_ "GenSigSendType" SG_ 579 LeReTireMsgBattLoSt 0;
BA_ "GenSigSendType" SG_ 579 LeReTireMsgFastLoseWarnFlg 0;
BA_ "GenSigSendType" SG_ 579 LeReTireMsgMsgOldFlg 0;
BA_ "GenSigSendType" SG_ 579 LeReTireMsgP 0;
BA_ "GenSigStartValue" SG_ 579 LeReTireMsgP 255;
BA_ "GenSigSendType" SG_ 579 LeReTireMsgPWarnFlg 0;
BA_ "GenSigSendType" SG_ 579 LeReTireMsgSysWarnFlg 0;
BA_ "GenSigSendType" SG_ 579 LeReTireMsgT 0;
BA_ "GenSigStartValue" SG_ 579 LeReTireMsgT 255;
BA_ "GenSigSendType" SG_ 579 LeReTireMsgTWarnFlg 0;
BA_ "GenSigSendType" SG_ 579 LeReTireMsgTireFillgAssiPSts 0;
BA_ "GenSigSendType" SG_ 261 LockgCenStsLockSt 0;
BA_ "GenSigSendType" SG_ 261 LockgCenStsTrigSrc 0;
BA_ "GenSigSendType" SG_ 261 LockgCenStsUpdEve 0;
BA_ "GenSigStartValue" SG_ 261 LvlgDirMovmtIndcr 1;
BA_ "GenSigSendType" SG_ 261 MirrFoldStsAtDrvr 0;
BA_ "GenSigSendType" SG_ 530 MirrFoldStsAtPass 0;
BA_ "GenSigSendType" SG_ 867 OnBdChrgrCooltT 0;
BA_ "GenSigStartValue" SG_ 867 OnBdChrgrCooltT 40;
BA_ "GenSigSendType" SG_ 579 OnBdChrgrHndlSts1 0;
BA_ "GenSigStartValue" SG_ 579 OnBdChrgrHndlSts1 8;
BA_ "GenSigSendType" SG_ 931 PassAirbSts 0;
BA_ "GenSigStartValue" SG_ 931 PassAirbSts 1;
BA_ "GenSigSendType" SG_ 271 PassSeatSnsrSts2 0;
BA_ "GenSigSendType" SG_ 271 PassSeatSts2 0;
BA_ "GenSigStartValue" SG_ 271 PassSeatSts2 1;
BA_ "GenSigDataID" SG_ 83 PinionSteerAgGroupChks "0x40D";
BA_ "GenSigFuncType" SG_ 83 PinionSteerAgGroupChks 15;
BA_ "GenSigSendType" SG_ 83 PinionSteerAgGroupChks 0;
BA_ "GenSigFuncType" SG_ 83 PinionSteerAgGroupCntr 16;
BA_ "GenSigSendType" SG_ 83 PinionSteerAgGroupCntr 0;
BA_ "GenSigSendType" SG_ 83 PinionSteerAgGroupPinionSteerAg1 0;
BA_ "GenSigSendType" SG_ 83 PinionSteerAgGroupPinionSteerAg1Qf 0;
BA_ "GenSigStartValue" SG_ 83 PinionSteerAgGroupPinionSteerAg1Qf 1;
BA_ "GenSigSendType" SG_ 83 PinionSteerAgGroupPinionSteerAgSpd1 0;
BA_ "GenSigSendType" SG_ 83 PinionSteerAgGroupPinionSteerAgSpd1Qf 0;
BA_ "GenSigStartValue" SG_ 83 PinionSteerAgGroupPinionSteerAgSpd1Qf 1;
BA_ "GenSigSendType" SG_ 83 PinionSteerAgGroupSteerWhlTq 0;
BA_ "GenSigSendType" SG_ 83 PinionSteerAgGroupSteerWhlTqQf 0;
BA_ "GenSigStartValue" SG_ 83 PinionSteerAgGroupSteerWhlTqQf 1;
BA_ "GenSigSendType" SG_ 261 PtBrkTqActTot 0;
BA_ "GenSigSendType" SG_ 261 PtBrkTqActTotQf 0;
BA_ "GenSigSendType" SG_ 261 PtBrkTqChks 0;
BA_ "GenSigSendType" SG_ 261 PtBrkTqCntr 0;
BA_ "GenSigSendType" SG_ 261 PtBrkTqQf 0;
BA_ "GenSigSendType" SG_ 261 PtBrkTqReqForBrkSys 0;
BA_ "GenSigSendType" SG_ 261 PtBrkTqRgnAtAxleReAct 0;
BA_ "GenSigSendType" SG_ 451 RainfallAmnt 0;
BA_ "GenSigStartValue" SG_ 451 RainfallAmnt 14;
BA_ "GenSigSendType" SG_ 451 RcwmLiActvd 0;
BA_ "GenSigDataID" SG_ 261 RecOfPostImpctBrkgCfmdChks "0x4A";
BA_ "GenSigFuncType" SG_ 261 RecOfPostImpctBrkgCfmdChks 15;
BA_ "GenSigSendType" SG_ 261 RecOfPostImpctBrkgCfmdChks 0;
BA_ "GenSigStartValue" SG_ 261 RecOfPostImpctBrkgCfmdChks 255;
BA_ "GenSigFuncType" SG_ 261 RecOfPostImpctBrkgCfmdCntr 16;
BA_ "GenSigSendType" SG_ 261 RecOfPostImpctBrkgCfmdCntr 0;
BA_ "GenSigSendType" SG_ 261 RecOfPostImpctBrkgCfmdCrashFrnt 0;
BA_ "GenSigStartValue" SG_ 261 RecOfPostImpctBrkgCfmdCrashFrnt 1;
BA_ "GenSigSendType" SG_ 261 RecOfPostImpctBrkgCfmdCrashLargeAnimal 0;
BA_ "GenSigStartValue" SG_ 261 RecOfPostImpctBrkgCfmdCrashLargeAnimal 1;
BA_ "GenSigSendType" SG_ 261 RecOfPostImpctBrkgCfmdCrashOffroadA 0;
BA_ "GenSigStartValue" SG_ 261 RecOfPostImpctBrkgCfmdCrashOffroadA 1;
BA_ "GenSigSendType" SG_ 261 RecOfPostImpctBrkgCfmdCrashOffroadD 0;
BA_ "GenSigStartValue" SG_ 261 RecOfPostImpctBrkgCfmdCrashOffroadD 1;
BA_ "GenSigSendType" SG_ 261 RecOfPostImpctBrkgCfmdCrashOffroadRT 0;
BA_ "GenSigStartValue" SG_ 261 RecOfPostImpctBrkgCfmdCrashOffroadRT 1;
BA_ "GenSigSendType" SG_ 261 RecOfPostImpctBrkgCfmdCrashOffroadRTsevere 0;
BA_ "GenSigStartValue" SG_ 261 RecOfPostImpctBrkgCfmdCrashOffroadRTsevere 1;
BA_ "GenSigSendType" SG_ 261 RecOfPostImpctBrkgCfmdCrashOz 0;
BA_ "GenSigStartValue" SG_ 261 RecOfPostImpctBrkgCfmdCrashOz 1;
BA_ "GenSigSendType" SG_ 261 RecOfPostImpctBrkgCfmdCrashPed 0;
BA_ "GenSigStartValue" SG_ 261 RecOfPostImpctBrkgCfmdCrashPed 1;
BA_ "GenSigSendType" SG_ 261 RecOfPostImpctBrkgCfmdCrashRe 0;
BA_ "GenSigStartValue" SG_ 261 RecOfPostImpctBrkgCfmdCrashRe 1;
BA_ "GenSigSendType" SG_ 261 RecOfPostImpctBrkgCfmdCrashRollovr 0;
BA_ "GenSigStartValue" SG_ 261 RecOfPostImpctBrkgCfmdCrashRollovr 1;
BA_ "GenSigSendType" SG_ 261 RecOfPostImpctBrkgCfmdCrashSideLe 0;
BA_ "GenSigStartValue" SG_ 261 RecOfPostImpctBrkgCfmdCrashSideLe 1;
BA_ "GenSigSendType" SG_ 261 RecOfPostImpctBrkgCfmdCrashSideRi 0;
BA_ "GenSigStartValue" SG_ 261 RecOfPostImpctBrkgCfmdCrashSideRi 1;
BA_ "GenSigSendType" SG_ 261 RecOfPostImpctBrkgCfmdPostImpctBrkgCfmd 0;
BA_ "GenSigStartValue" SG_ 261 RecOfPostImpctBrkgCfmdPostImpctBrkgCfmd 1;
BA_ "GenSigDataID" SG_ 83 RecOfPostImpctBrkgSuspcChks "0x19";
BA_ "GenSigFuncType" SG_ 83 RecOfPostImpctBrkgSuspcChks 15;
BA_ "GenSigSendType" SG_ 83 RecOfPostImpctBrkgSuspcChks 0;
BA_ "GenSigStartValue" SG_ 83 RecOfPostImpctBrkgSuspcChks 255;
BA_ "GenSigFuncType" SG_ 83 RecOfPostImpctBrkgSuspcCntr 16;
BA_ "GenSigSendType" SG_ 83 RecOfPostImpctBrkgSuspcCntr 0;
BA_ "GenSigSendType" SG_ 83 RecOfPostImpctBrkgSuspcSuspcPostImpctBrkg 0;
BA_ "GenSigStartValue" SG_ 83 RecOfPostImpctBrkgSuspcSuspcPostImpctBrkg 1;
BA_ "GenSigSendType" SG_ 579 RiFrntTireMsgBattLoSt 0;
BA_ "GenSigSendType" SG_ 579 RiFrntTireMsgFastLoseWarnFlg 0;
BA_ "GenSigSendType" SG_ 579 RiFrntTireMsgMsgOldFlg 0;
BA_ "GenSigSendType" SG_ 579 RiFrntTireMsgP 0;
BA_ "GenSigStartValue" SG_ 579 RiFrntTireMsgP 255;
BA_ "GenSigSendType" SG_ 579 RiFrntTireMsgPWarnFlg 0;
BA_ "GenSigSendType" SG_ 579 RiFrntTireMsgSysWarnFlg 0;
BA_ "GenSigSendType" SG_ 579 RiFrntTireMsgT 0;
BA_ "GenSigStartValue" SG_ 579 RiFrntTireMsgT 255;
BA_ "GenSigSendType" SG_ 579 RiFrntTireMsgTWarnFlg 0;
BA_ "GenSigSendType" SG_ 579 RiFrntTireMsgTireFillgAssiPSts 0;
BA_ "GenSigSendType" SG_ 579 RiReTireMsgBattLoSt 0;
BA_ "GenSigSendType" SG_ 579 RiReTireMsgFastLoseWarnFlg 0;
BA_ "GenSigSendType" SG_ 579 RiReTireMsgMsgOldFlg 0;
BA_ "GenSigSendType" SG_ 579 RiReTireMsgP 0;
BA_ "GenSigStartValue" SG_ 579 RiReTireMsgP 255;
BA_ "GenSigSendType" SG_ 579 RiReTireMsgPWarnFlg 0;
BA_ "GenSigSendType" SG_ 579 RiReTireMsgSysWarnFlg 0;
BA_ "GenSigSendType" SG_ 579 RiReTireMsgT 0;
BA_ "GenSigStartValue" SG_ 579 RiReTireMsgT 255;
BA_ "GenSigSendType" SG_ 579 RiReTireMsgTWarnFlg 0;
BA_ "GenSigSendType" SG_ 579 RiReTireMsgTireFillgAssiPSts 0;
BA_ "GenSigSendType" SG_ 579 SeatBackAngleRowFirstDrvr 0;
BA_ "GenSigStartValue" SG_ 451 SteerWhlPosnAng 2048;
BA_ "GenSigStartValue" SG_ 451 SteerWhlPosnX 2048;
BA_ "GenSigSendType" SG_ 261 SunRoofPosnSts 0;
BA_ "GenSigStartValue" SG_ 83 SuspPosnVertLe1FrntQf 1;
BA_ "GenSigStartValue" SG_ 83 SuspPosnVertLe1ReQf 1;
BA_ "GenSigStartValue" SG_ 83 SuspPosnVertRi1SuspPosnVertRiFrntQf 1;
BA_ "GenSigStartValue" SG_ 83 SuspPosnVertRi1SuspPosnVertRiReQf 1;
BA_ "GenSigSendType" SG_ 451 SwtIndcrIndcrTypExtReq 0;
BA_ "GenSigSendType" SG_ 451 SwtIndcrIndcrTypExtReqChks 0;
BA_ "GenSigSendType" SG_ 451 SwtIndcrIndcrTypExtReqCntr 0;
BA_ "GenSigSendType" SG_ 451 SwtIndcrIndcrTypExtReqToUpdQf 0;
BA_ "GenSigStartValue" SG_ 451 SwtIndcrIndcrTypExtReqToUpdQf 1;
BA_ "GenSigSendType" SG_ 545 TDcDcCoolt 0;
BA_ "GenSigStartValue" SG_ 545 TDcDcCoolt 40;
BA_ "GenSigSendType" SG_ 837 TiAndDateIndcnDataValid 0;
BA_ "GenSigSendType" SG_ 837 TiAndDateIndcnDay 0;
BA_ "GenSigStartValue" SG_ 837 TiAndDateIndcnDay 1;
BA_ "GenSigSendType" SG_ 837 TiAndDateIndcnHr1 0;
BA_ "GenSigSendType" SG_ 837 TiAndDateIndcnMins1 0;
BA_ "GenSigSendType" SG_ 837 TiAndDateIndcnMth1 0;
BA_ "GenSigStartValue" SG_ 837 TiAndDateIndcnMth1 1;
BA_ "GenSigSendType" SG_ 837 TiAndDateIndcnSec1 0;
BA_ "GenSigSendType" SG_ 837 TiAndDateIndcnYr1 0;
BA_ "GenSigSendType" SG_ 451 TiDrvgCycOff 0;
BA_ "GenSigSendType" SG_ 451 TrLockSts 0;
BA_ "GenSigSendType" SG_ 261 TrSts 0;
BA_ "GenSigDataID" SG_ 261 TrsmParkLockdChks "0x32";
BA_ "GenSigFuncType" SG_ 261 TrsmParkLockdChks 15;
BA_ "GenSigSendType" SG_ 261 TrsmParkLockdChks 0;
BA_ "GenSigFuncType" SG_ 261 TrsmParkLockdCntr 16;
BA_ "GenSigSendType" SG_ 261 TrsmParkLockdCntr 0;
BA_ "GenSigSendType" SG_ 261 TrsmParkLockdTrsmParkLockd 0;
BA_ "GenSigStartValue" SG_ 261 TrsmParkLockdTrsmParkLockd 3;
BA_ "GenSigSendType" SG_ 451 TurnIndcrMonostableChks 0;
BA_ "GenSigSendType" SG_ 451 TurnIndcrMonostableCntr 0;
BA_ "GenSigSendType" SG_ 451 TurnIndcrMonostableQf 0;
BA_ "GenSigStartValue" SG_ 451 TurnIndcrMonostableQf 1;
BA_ "GenSigSendType" SG_ 451 TurnIndcrMonostableTurnIndcrMonostable 0;
BA_ "GenSigSendType" SG_ 451 TwliBriRawQf 0;
BA_ "GenSigStartValue" SG_ 451 TwliBriRawQf 1;
BA_ "GenSigSendType" SG_ 451 TwliBriRawTwliBriRaw 0;
BA_ "GenSigSendType" SG_ 545 TwliBriSts 0;
BA_ "GenSigDataID" SG_ 851 ULoWarnChks "0x43";
BA_ "GenSigFuncType" SG_ 851 ULoWarnChks 15;
BA_ "GenSigSendType" SG_ 851 ULoWarnChks 0;
BA_ "GenSigFuncType" SG_ 851 ULoWarnCntr 16;
BA_ "GenSigSendType" SG_ 851 ULoWarnCntr 0;
BA_ "GenSigSendType" SG_ 851 ULoWarnULoWarn 0;
BA_ "GenSigSendType" SG_ 851 UsgModDeactvnQly 0;
BA_ "GenSigStartValue" SG_ 851 UsgModDeactvnQly 2;
BA_ "GenSigSendType" SG_ 1347 VFCVectorZCUDMBlockID 0;
BA_ "GenSigSendType" SG_ 1347 VFCVectorZCUDMVFCid0 0;
BA_ "GenSigSendType" SG_ 1347 VFCVectorZCUDMVFCid1 0;
BA_ "GenSigSendType" SG_ 1347 VFCVectorZCUDMVFCid10 0;
BA_ "GenSigSendType" SG_ 1347 VFCVectorZCUDMVFCid11 0;
BA_ "GenSigSendType" SG_ 1347 VFCVectorZCUDMVFCid12 0;
BA_ "GenSigSendType" SG_ 1347 VFCVectorZCUDMVFCid13 0;
BA_ "GenSigSendType" SG_ 1347 VFCVectorZCUDMVFCid14 0;
BA_ "GenSigSendType" SG_ 1347 VFCVectorZCUDMVFCid15 0;
BA_ "GenSigSendType" SG_ 1347 VFCVectorZCUDMVFCid16 0;
BA_ "GenSigSendType" SG_ 1347 VFCVectorZCUDMVFCid17 0;
BA_ "GenSigSendType" SG_ 1347 VFCVectorZCUDMVFCid18 0;
BA_ "GenSigSendType" SG_ 1347 VFCVectorZCUDMVFCid19 0;
BA_ "GenSigSendType" SG_ 1347 VFCVectorZCUDMVFCid2 0;
BA_ "GenSigSendType" SG_ 1347 VFCVectorZCUDMVFCid20 0;
BA_ "GenSigSendType" SG_ 1347 VFCVectorZCUDMVFCid21 0;
BA_ "GenSigSendType" SG_ 1347 VFCVectorZCUDMVFCid22 0;
BA_ "GenSigSendType" SG_ 1347 VFCVectorZCUDMVFCid23 0;
BA_ "GenSigSendType" SG_ 1347 VFCVectorZCUDMVFCid24 0;
BA_ "GenSigSendType" SG_ 1347 VFCVectorZCUDMVFCid25 0;
BA_ "GenSigSendType" SG_ 1347 VFCVectorZCUDMVFCid26 0;
BA_ "GenSigSendType" SG_ 1347 VFCVectorZCUDMVFCid27 0;
BA_ "GenSigSendType" SG_ 1347 VFCVectorZCUDMVFCid28 0;
BA_ "GenSigSendType" SG_ 1347 VFCVectorZCUDMVFCid29 0;
BA_ "GenSigSendType" SG_ 1347 VFCVectorZCUDMVFCid3 0;
BA_ "GenSigSendType" SG_ 1347 VFCVectorZCUDMVFCid30 0;
BA_ "GenSigSendType" SG_ 1347 VFCVectorZCUDMVFCid31 0;
BA_ "GenSigSendType" SG_ 1347 VFCVectorZCUDMVFCid32 0;
BA_ "GenSigSendType" SG_ 1347 VFCVectorZCUDMVFCid33 0;
BA_ "GenSigSendType" SG_ 1347 VFCVectorZCUDMVFCid34 0;
BA_ "GenSigSendType" SG_ 1347 VFCVectorZCUDMVFCid35 0;
BA_ "GenSigSendType" SG_ 1347 VFCVectorZCUDMVFCid36 0;
BA_ "GenSigSendType" SG_ 1347 VFCVectorZCUDMVFCid37 0;
BA_ "GenSigSendType" SG_ 1347 VFCVectorZCUDMVFCid38 0;
BA_ "GenSigSendType" SG_ 1347 VFCVectorZCUDMVFCid39 0;
BA_ "GenSigSendType" SG_ 1347 VFCVectorZCUDMVFCid4 0;
BA_ "GenSigSendType" SG_ 1347 VFCVectorZCUDMVFCid40 0;
BA_ "GenSigSendType" SG_ 1347 VFCVectorZCUDMVFCid41 0;
BA_ "GenSigSendType" SG_ 1347 VFCVectorZCUDMVFCid42 0;
BA_ "GenSigSendType" SG_ 1347 VFCVectorZCUDMVFCid43 0;
BA_ "GenSigSendType" SG_ 1347 VFCVectorZCUDMVFCid44 0;
BA_ "GenSigSendType" SG_ 1347 VFCVectorZCUDMVFCid45 0;
BA_ "GenSigSendType" SG_ 1347 VFCVectorZCUDMVFCid46 0;
BA_ "GenSigSendType" SG_ 1347 VFCVectorZCUDMVFCid47 0;
BA_ "GenSigSendType" SG_ 1347 VFCVectorZCUDMVFCid48 0;
BA_ "GenSigSendType" SG_ 1347 VFCVectorZCUDMVFCid49 0;
BA_ "GenSigSendType" SG_ 1347 VFCVectorZCUDMVFCid5 0;
BA_ "GenSigSendType" SG_ 1347 VFCVectorZCUDMVFCid50 0;
BA_ "GenSigSendType" SG_ 1347 VFCVectorZCUDMVFCid51 0;
BA_ "GenSigSendType" SG_ 1347 VFCVectorZCUDMVFCid52 0;
BA_ "GenSigSendType" SG_ 1347 VFCVectorZCUDMVFCid53 0;
BA_ "GenSigSendType" SG_ 1347 VFCVectorZCUDMVFCid54 0;
BA_ "GenSigSendType" SG_ 1347 VFCVectorZCUDMVFCid55 0;
BA_ "GenSigSendType" SG_ 1347 VFCVectorZCUDMVFCid56 0;
BA_ "GenSigSendType" SG_ 1347 VFCVectorZCUDMVFCid57 0;
BA_ "GenSigSendType" SG_ 1347 VFCVectorZCUDMVFCid58 0;
BA_ "GenSigSendType" SG_ 1347 VFCVectorZCUDMVFCid59 0;
BA_ "GenSigSendType" SG_ 1347 VFCVectorZCUDMVFCid6 0;
BA_ "GenSigSendType" SG_ 1347 VFCVectorZCUDMVFCid60 0;
BA_ "GenSigSendType" SG_ 1347 VFCVectorZCUDMVFCid61 0;
BA_ "GenSigSendType" SG_ 1347 VFCVectorZCUDMVFCid7 0;
BA_ "GenSigSendType" SG_ 1347 VFCVectorZCUDMVFCid8 0;
BA_ "GenSigSendType" SG_ 1347 VFCVectorZCUDMVFCid9 0;
BA_ "GenSigSendType" SG_ 1349 VFCVectorZCUPBlockID 0;
BA_ "GenSigSendType" SG_ 1349 VFCVectorZCUPVFCid0 0;
BA_ "GenSigSendType" SG_ 1349 VFCVectorZCUPVFCid1 0;
BA_ "GenSigSendType" SG_ 1349 VFCVectorZCUPVFCid10 0;
BA_ "GenSigSendType" SG_ 1349 VFCVectorZCUPVFCid11 0;
BA_ "GenSigSendType" SG_ 1349 VFCVectorZCUPVFCid12 0;
BA_ "GenSigSendType" SG_ 1349 VFCVectorZCUPVFCid13 0;
BA_ "GenSigSendType" SG_ 1349 VFCVectorZCUPVFCid14 0;
BA_ "GenSigSendType" SG_ 1349 VFCVectorZCUPVFCid15 0;
BA_ "GenSigSendType" SG_ 1349 VFCVectorZCUPVFCid16 0;
BA_ "GenSigSendType" SG_ 1349 VFCVectorZCUPVFCid17 0;
BA_ "GenSigSendType" SG_ 1349 VFCVectorZCUPVFCid18 0;
BA_ "GenSigSendType" SG_ 1349 VFCVectorZCUPVFCid19 0;
BA_ "GenSigSendType" SG_ 1349 VFCVectorZCUPVFCid2 0;
BA_ "GenSigSendType" SG_ 1349 VFCVectorZCUPVFCid20 0;
BA_ "GenSigSendType" SG_ 1349 VFCVectorZCUPVFCid21 0;
BA_ "GenSigSendType" SG_ 1349 VFCVectorZCUPVFCid22 0;
BA_ "GenSigSendType" SG_ 1349 VFCVectorZCUPVFCid23 0;
BA_ "GenSigSendType" SG_ 1349 VFCVectorZCUPVFCid24 0;
BA_ "GenSigSendType" SG_ 1349 VFCVectorZCUPVFCid25 0;
BA_ "GenSigSendType" SG_ 1349 VFCVectorZCUPVFCid26 0;
BA_ "GenSigSendType" SG_ 1349 VFCVectorZCUPVFCid27 0;
BA_ "GenSigSendType" SG_ 1349 VFCVectorZCUPVFCid28 0;
BA_ "GenSigSendType" SG_ 1349 VFCVectorZCUPVFCid29 0;
BA_ "GenSigSendType" SG_ 1349 VFCVectorZCUPVFCid3 0;
BA_ "GenSigSendType" SG_ 1349 VFCVectorZCUPVFCid30 0;
BA_ "GenSigSendType" SG_ 1349 VFCVectorZCUPVFCid31 0;
BA_ "GenSigSendType" SG_ 1349 VFCVectorZCUPVFCid32 0;
BA_ "GenSigSendType" SG_ 1349 VFCVectorZCUPVFCid33 0;
BA_ "GenSigSendType" SG_ 1349 VFCVectorZCUPVFCid34 0;
BA_ "GenSigSendType" SG_ 1349 VFCVectorZCUPVFCid35 0;
BA_ "GenSigSendType" SG_ 1349 VFCVectorZCUPVFCid36 0;
BA_ "GenSigSendType" SG_ 1349 VFCVectorZCUPVFCid37 0;
BA_ "GenSigSendType" SG_ 1349 VFCVectorZCUPVFCid38 0;
BA_ "GenSigSendType" SG_ 1349 VFCVectorZCUPVFCid39 0;
BA_ "GenSigSendType" SG_ 1349 VFCVectorZCUPVFCid4 0;
BA_ "GenSigSendType" SG_ 1349 VFCVectorZCUPVFCid40 0;
BA_ "GenSigSendType" SG_ 1349 VFCVectorZCUPVFCid41 0;
BA_ "GenSigSendType" SG_ 1349 VFCVectorZCUPVFCid42 0;
BA_ "GenSigSendType" SG_ 1349 VFCVectorZCUPVFCid43 0;
BA_ "GenSigSendType" SG_ 1349 VFCVectorZCUPVFCid44 0;
BA_ "GenSigSendType" SG_ 1349 VFCVectorZCUPVFCid45 0;
BA_ "GenSigSendType" SG_ 1349 VFCVectorZCUPVFCid46 0;
BA_ "GenSigSendType" SG_ 1349 VFCVectorZCUPVFCid47 0;
BA_ "GenSigSendType" SG_ 1349 VFCVectorZCUPVFCid48 0;
BA_ "GenSigSendType" SG_ 1349 VFCVectorZCUPVFCid49 0;
BA_ "GenSigSendType" SG_ 1349 VFCVectorZCUPVFCid5 0;
BA_ "GenSigSendType" SG_ 1349 VFCVectorZCUPVFCid50 0;
BA_ "GenSigSendType" SG_ 1349 VFCVectorZCUPVFCid51 0;
BA_ "GenSigSendType" SG_ 1349 VFCVectorZCUPVFCid52 0;
BA_ "GenSigSendType" SG_ 1349 VFCVectorZCUPVFCid53 0;
BA_ "GenSigSendType" SG_ 1349 VFCVectorZCUPVFCid54 0;
BA_ "GenSigSendType" SG_ 1349 VFCVectorZCUPVFCid55 0;
BA_ "GenSigSendType" SG_ 1349 VFCVectorZCUPVFCid56 0;
BA_ "GenSigSendType" SG_ 1349 VFCVectorZCUPVFCid57 0;
BA_ "GenSigSendType" SG_ 1349 VFCVectorZCUPVFCid58 0;
BA_ "GenSigSendType" SG_ 1349 VFCVectorZCUPVFCid59 0;
BA_ "GenSigSendType" SG_ 1349 VFCVectorZCUPVFCid6 0;
BA_ "GenSigSendType" SG_ 1349 VFCVectorZCUPVFCid60 0;
BA_ "GenSigSendType" SG_ 1349 VFCVectorZCUPVFCid61 0;
BA_ "GenSigSendType" SG_ 1349 VFCVectorZCUPVFCid7 0;
BA_ "GenSigSendType" SG_ 1349 VFCVectorZCUPVFCid8 0;
BA_ "GenSigSendType" SG_ 1349 VFCVectorZCUPVFCid9 0;
BA_ "GenSigSendType" SG_ 931 VehBattUSysU 0;
BA_ "GenSigSendType" SG_ 931 VehBattUSysUQf 0;
BA_ "GenSigStartValue" SG_ 931 VehBattUSysUQf 1;
BA_ "GenSigSendType" SG_ 83 VehModMngtGlbSafe1CarModSts1 0;
BA_ "GenSigSendType" SG_ 83 VehModMngtGlbSafe1CarModSubtypWdCarModSubtyp 0;
BA_ "GenSigDataID" SG_ 83 VehModMngtGlbSafe1Chks "0x74";
BA_ "GenSigFuncType" SG_ 83 VehModMngtGlbSafe1Chks 15;
BA_ "GenSigSendType" SG_ 83 VehModMngtGlbSafe1Chks 0;
BA_ "GenSigFuncType" SG_ 83 VehModMngtGlbSafe1Cntr 16;
BA_ "GenSigSendType" SG_ 83 VehModMngtGlbSafe1Cntr 0;
BA_ "GenSigSendType" SG_ 83 VehModMngtGlbSafe1EgyLvlElecMai 0;
BA_ "GenSigSendType" SG_ 83 VehModMngtGlbSafe1EgyLvlElecSubtyp 0;
BA_ "GenSigSendType" SG_ 83 VehModMngtGlbSafe1FltEgyCnsWdSts 0;
BA_ "GenSigSendType" SG_ 83 VehModMngtGlbSafe1PwrLvlElecMai 0;
BA_ "GenSigSendType" SG_ 83 VehModMngtGlbSafe1PwrLvlElecSubtyp 0;
BA_ "GenSigSendType" SG_ 83 VehModMngtGlbSafe1UsgModSts 0;
BA_ "GenSigStartValue" SG_ 83 VehModMngtGlbSafe1UsgModSts 1;
BA_ "GenSigSendType" SG_ 451 VehParkNotActvd 0;
BA_ "GenSigSendType" SG_ 83 VehTiAndDataDataValid 0;
BA_ "GenSigSendType" SG_ 83 VehTiAndDataDay 0;
BA_ "GenSigStartValue" SG_ 83 VehTiAndDataDay 1;
BA_ "GenSigSendType" SG_ 83 VehTiAndDataHr1 0;
BA_ "GenSigSendType" SG_ 83 VehTiAndDataMins1 0;
BA_ "GenSigSendType" SG_ 83 VehTiAndDataMth1 0;
BA_ "GenSigStartValue" SG_ 83 VehTiAndDataMth1 1;
BA_ "GenSigSendType" SG_ 83 VehTiAndDataSec1 0;
BA_ "GenSigSendType" SG_ 83 VehTiAndDataYr1 0;
BA_ "GenSigSendType" SG_ 1283 WakeUpReasonsforZCUDM 0;
BA_ "GenSigSendType" SG_ 1285 WakeUpReasonsforZCUP 0;
BA_ "GenSigStartValue" SG_ 97 WhlMotSysTqEstIsgTqAct 8188;
BA_ "GenSigStartValue" SG_ 97 WhlMotSysTqEstQualityFactor 1;
BA_ "GenSigSendType" SG_ 83 WinPosnStsAtDrvr 0;
BA_ "GenSigSendType" SG_ 530 WinPosnStsAtPass 0;
BA_ "GenSigSendType" SG_ 83 WinPosnStsAtReLe 0;
BA_ "GenSigSendType" SG_ 530 WinPosnStsAtReRi 0;
BA_ "GenSigSendType" SG_ 451 WipgInfoWipgSpdInfo 0;
BA_ "GenSigSendType" SG_ 451 WipgInfoWiprActv 0;
BA_ "GenSigSendType" SG_ 451 WipgInfoWiprInWipgAr 0;
VAL_ 97 ActvnOfWelcomeLi 0 "OnOff1_Off" 1 "OnOff1_On";
VAL_ 97 ADataRawSafeALat1Qf 0 "Qf1_DevOfDataUndefd" 1 "Qf1_DataTmpUndefdAndEvlnInProgs" 2 "Qf1_DevOfDataNotWithinRngAllwd" 3 "Qf1_DataCalcdWithDevDefd";
VAL_ 97 ADataRawSafeALgt1Qf 0 "Qf1_DevOfDataUndefd" 1 "Qf1_DataTmpUndefdAndEvlnInProgs" 2 "Qf1_DevOfDataNotWithinRngAllwd" 3 "Qf1_DataCalcdWithDevDefd";
VAL_ 97 ADataRawSafeAVertQf 0 "Qf1_DevOfDataUndefd" 1 "Qf1_DataTmpUndefdAndEvlnInProgs" 2 "Qf1_DevOfDataNotWithinRngAllwd" 3 "Qf1_DataCalcdWithDevDefd";
VAL_ 97 ADModCtrlInhbnADModCtrlInhbn 0 "NoInhb" 1 "L12LgtCtrlModInhb" 2 "AutoParkingModInhb" 3 "L12AndAutoParkingModInhb" 4 "L3ADModInhb" 5 "L3ADAndL12LgtCtrlModInhb" 6 "L3ADAndAutoParkingModInhb" 7 "L3ADAndAutoParkingAndL12LgtCtrlModInhb";
VAL_ 97 AgDataRaw2SafePitchRateQf 0 "Qf1_DevOfDataUndefd" 1 "Qf1_DataTmpUndefdAndEvlnInProgs" 2 "Qf1_DevOfDataNotWithinRngAllwd" 3 "Qf1_DataCalcdWithDevDefd";
VAL_ 97 AgDataRawSafeRollRateQf 0 "Qf1_DevOfDataUndefd" 1 "Qf1_DataTmpUndefdAndEvlnInProgs" 2 "Qf1_DevOfDataNotWithinRngAllwd" 3 "Qf1_DataCalcdWithDevDefd";
VAL_ 97 AgDataRawSafeYawRateQf 0 "Qf1_DevOfDataUndefd" 1 "Qf1_DataTmpUndefdAndEvlnInProgs" 2 "Qf1_DevOfDataNotWithinRngAllwd" 3 "Qf1_DataCalcdWithDevDefd";
VAL_ 97 AmbTRawQly 0 "GenQf1_UndefindDataAccur" 1 "GenQf1_TmpUndefdData" 2 "GenQf1_DataAccurNotWithinSpcn" 3 "GenQf1_AccurData";
VAL_ 97 AsyDataWithCmpSafeALat1Qf 0 "Qf1_DevOfDataUndefd" 1 "Qf1_DataTmpUndefdAndEvlnInProgs" 2 "Qf1_DevOfDataNotWithinRngAllwd" 3 "Qf1_DataCalcdWithDevDefd";
VAL_ 97 AsyDataWithCmpSafeALgt1Qf 0 "Qf1_DevOfDataUndefd" 1 "Qf1_DataTmpUndefdAndEvlnInProgs" 2 "Qf1_DevOfDataNotWithinRngAllwd" 3 "Qf1_DataCalcdWithDevDefd";
VAL_ 97 AsyDataWithCmpSafeYawRateQf 0 "Qf1_DevOfDataUndefd" 1 "Qf1_DataTmpUndefdAndEvlnInProgs" 2 "Qf1_DevOfDataNotWithinRngAllwd" 3 "Qf1_DataCalcdWithDevDefd";
VAL_ 97 BrkPedlSnsrQf 0 "GenQf1_UndefindDataAccur" 1 "GenQf1_TmpUndefdData" 2 "GenQf1_DataAccurNotWithinSpcn" 3 "GenQf1_AccurData";
VAL_ 97 BrkPedlSnsrSt 0 "PsdNotPsd2_NoInfo1" 1 "PsdNotPsd2_NotPsd" 2 "PsdNotPsd2_Psd" 3 "PsdNotPsd2_NoInfo2";
VAL_ 97 BrkPedlSts 0 "OkNotOk1_Ok" 1 "OkNotOk1_NotOk";
VAL_ 97 CrsCtrlOvrdn 0 "OnOff1_Off" 1 "OnOff1_On";
VAL_ 97 CrsCtrlrMsg 0 "CrsCtrlrMsg1_NoMsg" 1 "CrsCtrlrMsg1_CrsCtrlrCncl" 2 "CrsCtrlrMsg1_OvrdTiMaxExcdd" 3 "CrsCtrlrMsg1_CrsCtrlrInhb" 4 "CrsCtrlrMsg1_SpdLoLimExcdd" 5 "CrsCtrlrMsg1_CrsCtrlrCnclSpdLoLimExcdd" 6 "CrsCtrlrMsg1_DrvModSeldNotOk" 7 "CrsCtrlrMsg1_BrkOvrheatd";
VAL_ 97 CrsCtrlrStbOk 0 "OnOff1_Off" 1 "OnOff1_On";
VAL_ 97 CrsCtrlrSts 1 "CrsCtrlrSts1_Off" 2 "CrsCtrlrSts1_Stb" 3 "CrsCtrlrSts1_Actv";
VAL_ 97 DmcStsRearToEscDmcSts 0 "DMC_Init" 1 "DMC_On" 2 "DMC_Off" 3 "DMC_Fault";
VAL_ 97 DoorDrvrLockCmd 0 "LockActvnSafe1_LockActvnOff" 1 "LockActvnSafe1_LockActvnUnlck" 2 "LockActvnSafe1_LockActvnLock" 3 "LockActvnSafe1_LockActvnSafe" 4 "LockActvnSafe1_LockActvnUnlckByCrash1" 8 "LockActvnSafe1_LockActvnUnlckByCrash2" 12 "LockActvnSafe1_LockActvnUnlckByCrash0" 13 "LockActvnSafe1_LockActvnUnlckByCrash4" 14 "LockActvnSafe1_LockActvnUnlckByCrash3";
VAL_ 97 DrvrDesDirDrvrDesDir 0 "DrvrDesDir1_Undefd" 1 "DrvrDesDir1_Fwd" 2 "DrvrDesDir1_Rvs" 3 "DrvrDesDir1_Neut" 4 "DrvrDesDir1_Resd0" 5 "DrvrDesDir1_Resd1" 6 "DrvrDesDir1_Resd2" 7 "DrvrDesDir1_Resd3";
VAL_ 97 DrvrGearShiftDirReq1DwnDwnTipAut 0 "NotActvActv1_NotActv" 1 "NotActvActv1_Actv";
VAL_ 97 DrvrGearShiftDirReq1DwnTipAut 0 "DwnTipAut1_DwnTipAutNotActv" 1 "DwnTipAut1_DwnTipAutActv";
VAL_ 97 DrvrGearShiftDirReq1PosnAut 0 "PosnAut_PosnAutNotActv" 1 "PosnAut_PosnAutActv";
VAL_ 97 DrvrGearShiftDirReq1UpTipAut 0 "UpTipAut1_UpTipAutNotActv" 1 "UpTipAut1_UpTipAutActv";
VAL_ 97 DrvrGearShiftDirReq1UpUpTipAut 0 "NotActvActv1_NotActv" 1 "NotActvActv1_Actv";
VAL_ 97 DrvrGearShiftDirReq2DwnDwnTipAut 0 "NotActvActv1_NotActv" 1 "NotActvActv1_Actv";
VAL_ 97 DrvrGearShiftDirReq2DwnTipAut 0 "DwnTipAut1_DwnTipAutNotActv" 1 "DwnTipAut1_DwnTipAutActv";
VAL_ 97 DrvrGearShiftDirReq2PosnAut 0 "PosnAut_PosnAutNotActv" 1 "PosnAut_PosnAutActv";
VAL_ 97 DrvrGearShiftDirReq2UpTipAut 0 "UpTipAut1_UpTipAutNotActv" 1 "UpTipAut1_UpTipAutActv";
VAL_ 97 DrvrGearShiftDirReq2UpUpTipAut 0 "NotActvActv1_NotActv" 1 "NotActvActv1_Actv";
VAL_ 97 EpbActrStSec 0 "AppRel_Applied" 1 "AppRel_Released" 2 "AppRel_Applying" 3 "AppRel_Releasing" 4 "AppRel_Unknown" 5 "AppRel_HoldApplied" 6 "AppRel_CompletelyReleased" 7 "AppRel_HapPrepared";
VAL_ 97 ExtrLiRlyPwrDwn 0 "Boolean_FALSE" 1 "Boolean_TRUE";
VAL_ 97 GearMovmtFlg 0 "FuncSts_NoReq" 1 "FuncSts_Set" 2 "FuncSts_Resume" 3 "FuncSts_Cancle";
VAL_ 97 WhlMotSysModSts 0 "WhlMotSysModStsTyp2_Inin" 1 "WhlMotSysModStsTyp2_Stb" 2 "WhlMotSysModStsTyp2_TqCtrl" 3 "WhlMotSysModStsTyp2_SpdCtrlIdle" 4 "WhlMotSysModStsTyp2_CluOper" 5 "WhlMotSysModStsTyp2_PreChrg" 6 "WhlMotSysModStsTyp2_PwrDwn" 7 "WhlMotSysModStsTyp2_Flt" 8 "WhlMotSysModStsTyp2_TcsCtrl";
VAL_ 97 WhlMotSysTqEstQualityFactor 0 "QualityFactor_QfUndefd" 1 "QualityFactor_QfInProgs" 2 "QualityFactor_QfNotSpc" 3 "QualityFactor_QfSnsrDataOk";
VAL_ 261 ActvnStsOfRtrctrRvsbLe 0 "Enumeration1_NotActvd" 1 "Enumeration1_Actvd";
VAL_ 261 AlrmStsAlrmFailr 0 "SnsrSoundrBattBackedFailr_NoFailr" 1 "SnsrSoundrBattBackedFailr_Failr";
VAL_ 261 AlrmStsAlrmSt 0 "AlrmSt_Disarmd" 1 "AlrmSt_Armd" 2 "AlrmSt_Actv";
VAL_ 261 AlrmStsAlrmTrgSrc 0 "AlrmTrgSrc_NoTrigSrc" 1 "AlrmTrgSrc_SnsrSoundrBattBacked" 2 "AlrmTrgSrc_SnsrIncln" 3 "AlrmTrgSrc_SnsrIntrScanr" 4 "AlrmTrgSrc_Hood" 5 "AlrmTrgSrc_Tr" 6 "AlrmTrgSrc_DoorDrvr" 7 "AlrmTrgSrc_DoorPass" 8 "AlrmTrgSrc_DoorReLe" 9 "AlrmTrgSrc_DoorReRi" 10 "AlrmTrgSrc_VehImobnInvld" 11 "AlrmTrgSrc_VSTD" 12 "AlrmTrgSrc_Alcoloch";
VAL_ 261 AlrmStsSnsrInclnFailr 0 "SnsrInclnFailr_NoFailr" 1 "SnsrInclnFailr_Failr";
VAL_ 261 AlrmStsSnsrIntrScanrFailr 0 "SnsrIntrScanrFailr_NoFailr" 1 "SnsrIntrScanrFailr_Failr";
VAL_ 261 BltLockStSafeAtDrvrBltLockSt1 0 "BltLockSt1_Unlock" 1 "BltLockSt1_Lock";
VAL_ 261 BltLockStSafeAtDrvrBltLockStErrSts 0 "DevErrSts2_NoFlt" 1 "DevErrSts2_Flt";
VAL_ 261 BrkPedlValQf 0 "GenQf1_UndefindDataAccur" 1 "GenQf1_TmpUndefdData" 2 "GenQf1_DataAccurNotWithinSpcn" 3 "GenQf1_AccurData";
VAL_ 261 DoorDrvrSts 0 "DoorSts2_Ukwn" 1 "DoorSts2_Opend" 2 "DoorSts2_Clsd";
VAL_ 261 DoorDrvrStsWithFacQlyDoorSts 0 "DoorSts2_Ukwn" 1 "DoorSts2_Opend" 2 "DoorSts2_Clsd";
VAL_ 261 DoorDrvrStsWithFacQlyFacQly 0 "GenQf1_UndefindDataAccur" 1 "GenQf1_TmpUndefdData" 2 "GenQf1_DataAccurNotWithinSpcn" 3 "GenQf1_AccurData";
VAL_ 261 DoorLeReSts 0 "DoorSts2_Ukwn" 1 "DoorSts2_Opend" 2 "DoorSts2_Clsd";
VAL_ 261 DoorPassSts 0 "DoorSts2_Ukwn" 1 "DoorSts2_Opend" 2 "DoorSts2_Clsd";
VAL_ 261 DoorRiReSts 0 "DoorSts2_Ukwn" 1 "DoorSts2_Opend" 2 "DoorSts2_Clsd";
VAL_ 261 DrvrPrsntStsDrvrPrsnt 0 "NoYesCrit1_NotVld1" 1 "NoYesCrit1_No" 2 "NoYesCrit1_Yes" 3 "NoYesCrit1_NotVld2";
VAL_ 261 DrvrPrsntStsDrvrPrsntQf 0 "Qf1_DevOfDataUndefd" 1 "Qf1_DataTmpUndefdAndEvlnInProgs" 2 "Qf1_DevOfDataNotWithinRngAllwd" 3 "Qf1_DataCalcdWithDevDefd";
VAL_ 261 GearLvrIndcn 0 "GearLvrIndcn2_ParkIndcn" 1 "GearLvrIndcn2_RvsIndcn" 2 "GearLvrIndcn2_NeutIndcn" 3 "GearLvrIndcn2_DrvIndcn" 4 "GearLvrIndcn2_ManModeIndcn" 5 "GearLvrIndcn2_Resd1" 6 "GearLvrIndcn2_Resd2" 7 "GearLvrIndcn2_Undefd";
VAL_ 261 GearMov 0 "NoYesUnknownYes_No" 1 "NoYesUnknownYes_YesNo" 2 "NoYesUnknownYes_Unknown" 3 "NoYesUnknownYes_YesYes";
VAL_ 261 HoodSts 0 "DoorSts2_Ukwn" 1 "DoorSts2_Opend" 2 "DoorSts2_Clsd";
VAL_ 261 IndcrDisp 0 "IndcrSts1_Off" 1 "IndcrSts1_LeOn" 2 "IndcrSts1_RiOn" 3 "IndcrSts1_LeAndRiOn";
VAL_ 261 IndcrSts 0 "IndcrSts1_Off" 1 "IndcrSts1_LeOn" 2 "IndcrSts1_RiOn" 3 "IndcrSts1_LeAndRiOn";
VAL_ 261 LockgCenStsLockSt 0 "LockSt3_LockUndefd" 1 "LockSt3_LockUnlckd" 2 "LockSt3_LockTrUnlckd" 3 "LockSt3_LockLockd";
VAL_ 261 LockgCenStsTrigSrc 0 "LockTrigSrc2_NoTrigSrc" 1 "LockTrigSrc2_KeyRem" 2 "LockTrigSrc2_Keyls" 3 "LockTrigSrc2_IntrSwt" 4 "LockTrigSrc2_SpdAut" 5 "LockTrigSrc2_TmrAut" 6 "LockTrigSrc2_Slam" 7 "LockTrigSrc2_Telm" 8 "LockTrigSrc2_Crash" 9 "LockTrigSrc2_Apprch" 10 "LockTrigSrc2_OutsOth" 11 "LockTrigSrc2_InsOth";
VAL_ 261 LockgCenStsUpdEve 0 "Boolean_FALSE" 1 "Boolean_TRUE";
VAL_ 261 LvlgDirMovmtIndcr 0 "TriSt1_NegSt" 1 "TriSt1_StabSt" 2 "TriSt1_PosSt" 3 "TriSt1_NotUsed";
VAL_ 261 MirrFoldStsAtDrvr 0 "MirrFoldStsTyp_MirrFoldPosnUndefd" 1 "MirrFoldStsTyp_MirrNotFoldPosn" 2 "MirrFoldStsTyp_MirrFoldPosn" 3 "MirrFoldStsTyp_MirrMovgToNotFold" 4 "MirrFoldStsTyp_MirrMovgToFold";
VAL_ 261 PtBrkTqActTotQf 0 "Qf1_DevOfDataUndefd" 1 "Qf1_DataTmpUndefdAndEvlnInProgs" 2 "Qf1_DevOfDataNotWithinRngAllwd" 3 "Qf1_DataCalcdWithDevDefd";
VAL_ 261 PtBrkTqQf 0 "Qf1_DevOfDataUndefd" 1 "Qf1_DataTmpUndefdAndEvlnInProgs" 2 "Qf1_DevOfDataNotWithinRngAllwd" 3 "Qf1_DataCalcdWithDevDefd";
VAL_ 261 RecOfPostImpctBrkgCfmdCrashFrnt 0 "PostImpctBrkgNoYes_Undefd0" 1 "PostImpctBrkgNoYes_No" 2 "PostImpctBrkgNoYes_Yes" 3 "PostImpctBrkgNoYes_Undefd3";
VAL_ 261 RecOfPostImpctBrkgCfmdCrashLargeAnimal 0 "PostImpctBrkgNoYes_Undefd0" 1 "PostImpctBrkgNoYes_No" 2 "PostImpctBrkgNoYes_Yes" 3 "PostImpctBrkgNoYes_Undefd3";
VAL_ 261 RecOfPostImpctBrkgCfmdCrashOffroadA 0 "PostImpctBrkgNoYes_Undefd0" 1 "PostImpctBrkgNoYes_No" 2 "PostImpctBrkgNoYes_Yes" 3 "PostImpctBrkgNoYes_Undefd3";
VAL_ 261 RecOfPostImpctBrkgCfmdCrashOffroadD 0 "PostImpctBrkgNoYes_Undefd0" 1 "PostImpctBrkgNoYes_No" 2 "PostImpctBrkgNoYes_Yes" 3 "PostImpctBrkgNoYes_Undefd3";
VAL_ 261 RecOfPostImpctBrkgCfmdCrashOffroadRT 0 "PostImpctBrkgNoYes_Undefd0" 1 "PostImpctBrkgNoYes_No" 2 "PostImpctBrkgNoYes_Yes" 3 "PostImpctBrkgNoYes_Undefd3";
VAL_ 261 RecOfPostImpctBrkgCfmdCrashOffroadRTsevere 0 "PostImpctBrkgNoYes_Undefd0" 1 "PostImpctBrkgNoYes_No" 2 "PostImpctBrkgNoYes_Yes" 3 "PostImpctBrkgNoYes_Undefd3";
VAL_ 261 RecOfPostImpctBrkgCfmdCrashOz 0 "PostImpctBrkgNoYes_Undefd0" 1 "PostImpctBrkgNoYes_No" 2 "PostImpctBrkgNoYes_Yes" 3 "PostImpctBrkgNoYes_Undefd3";
VAL_ 261 RecOfPostImpctBrkgCfmdCrashPed 0 "PostImpctBrkgNoYes_Undefd0" 1 "PostImpctBrkgNoYes_No" 2 "PostImpctBrkgNoYes_Yes" 3 "PostImpctBrkgNoYes_Undefd3";
VAL_ 261 RecOfPostImpctBrkgCfmdCrashRe 0 "PostImpctBrkgNoYes_Undefd0" 1 "PostImpctBrkgNoYes_No" 2 "PostImpctBrkgNoYes_Yes" 3 "PostImpctBrkgNoYes_Undefd3";
VAL_ 261 RecOfPostImpctBrkgCfmdCrashRollovr 0 "PostImpctBrkgNoYes_Undefd0" 1 "PostImpctBrkgNoYes_No" 2 "PostImpctBrkgNoYes_Yes" 3 "PostImpctBrkgNoYes_Undefd3";
VAL_ 261 RecOfPostImpctBrkgCfmdCrashSideLe 0 "PostImpctBrkgNoYes_Undefd0" 1 "PostImpctBrkgNoYes_No" 2 "PostImpctBrkgNoYes_Yes" 3 "PostImpctBrkgNoYes_Undefd3";
VAL_ 261 RecOfPostImpctBrkgCfmdCrashSideRi 0 "PostImpctBrkgNoYes_Undefd0" 1 "PostImpctBrkgNoYes_No" 2 "PostImpctBrkgNoYes_Yes" 3 "PostImpctBrkgNoYes_Undefd3";
VAL_ 261 RecOfPostImpctBrkgCfmdPostImpctBrkgCfmd 0 "PostImpctBrkgNoYes_Undefd0" 1 "PostImpctBrkgNoYes_No" 2 "PostImpctBrkgNoYes_Yes" 3 "PostImpctBrkgNoYes_Undefd3";
VAL_ 261 StsForRtrctrRvsbLe 0 "NotOkOk_NotOk" 1 "NotOkOk_Ok" 2 "NotOkOk_Di" 3 "NotOkOk_Resd";
VAL_ 261 SunRoofPosnSts 0 "WinAndRoofAndCurtPosnTyp_PosnUkwn" 1 "WinAndRoofAndCurtPosnTyp_ClsFull" 2 "WinAndRoofAndCurtPosnTyp_PercOpen4" 3 "WinAndRoofAndCurtPosnTyp_PercOpen8" 4 "WinAndRoofAndCurtPosnTyp_PercOpen12" 5 "WinAndRoofAndCurtPosnTyp_PercOpen16" 6 "WinAndRoofAndCurtPosnTyp_PercOpen20" 7 "WinAndRoofAndCurtPosnTyp_PercOpen24" 8 "WinAndRoofAndCurtPosnTyp_PercOpen28" 9 "WinAndRoofAndCurtPosnTyp_PercOpen32" 10 "WinAndRoofAndCurtPosnTyp_PercOpen36" 11 "WinAndRoofAndCurtPosnTyp_PercOpen40" 12 "WinAndRoofAndCurtPosnTyp_PercOpen44" 13 "WinAndRoofAndCurtPosnTyp_PercOpen48" 14 "WinAndRoofAndCurtPosnTyp_PercOpen52" 15 "WinAndRoofAndCurtPosnTyp_PercOpen56" 16 "WinAndRoofAndCurtPosnTyp_PercOpen60" 17 "WinAndRoofAndCurtPosnTyp_PercOpen64" 18 "WinAndRoofAndCurtPosnTyp_PercOpen68" 19 "WinAndRoofAndCurtPosnTyp_PercOpen72" 20 "WinAndRoofAndCurtPosnTyp_PercOpen76" 21 "WinAndRoofAndCurtPosnTyp_PercOpen80" 22 "WinAndRoofAndCurtPosnTyp_PercOpen84" 23 "WinAndRoofAndCurtPosnTyp_PercOpen88" 24 "WinAndRoofAndCurtPosnTyp_PercOpen92" 25 "WinAndRoofAndCurtPosnTyp_PercOpen96" 26 "WinAndRoofAndCurtPosnTyp_OpenFull" 27 "WinAndRoofAndCurtPosnTyp_Resd1" 28 "WinAndRoofAndCurtPosnTyp_Resd2" 29 "WinAndRoofAndCurtPosnTyp_Resd3" 30 "WinAndRoofAndCurtPosnTyp_Resd4" 31 "WinAndRoofAndCurtPosnTyp_Movg";
VAL_ 261 SuspHeiLvlIndcn 0 "SuspHeiLvlCtrl_NRH" 1 "SuspHeiLvlCtrl_HL2" 2 "SuspHeiLvlCtrl_HL1" 3 "SuspHeiLvlCtrl_LL1" 4 "SuspHeiLvlCtrl_LL2";
VAL_ 261 TrsmParkLockdTrsmParkLockd 0 "TrsmParkLock1_ParkNotEngd" 1 "TrsmParkLock1_ParkEngd" 2 "TrsmParkLock1_NotInUse" 3 "TrsmParkLock1_Undefd";
VAL_ 261 TrSts 0 "DoorSts2_Ukwn" 1 "DoorSts2_Opend" 2 "DoorSts2_Clsd";
VAL_ 851 BltLockStAtRowSecLeBltLockEquid 0 "CptEquid_Equid" 1 "CptEquid_NotEquid";
VAL_ 851 BltLockStAtRowSecLeBltLockSt1 0 "BltLockSt1_Unlock" 1 "BltLockSt1_Lock";
VAL_ 851 BltLockStAtRowSecLeBltLockSts 0 "DevErrSts2_NoFlt" 1 "DevErrSts2_Flt";
VAL_ 851 BltLockStAtRowSecMidBltLockEquid 0 "CptEquid_Equid" 1 "CptEquid_NotEquid";
VAL_ 851 BltLockStAtRowSecMidBltLockSt1 0 "BltLockSt1_Unlock" 1 "BltLockSt1_Lock";
VAL_ 851 BltLockStAtRowSecMidBltLockSts 0 "DevErrSts2_NoFlt" 1 "DevErrSts2_Flt";
VAL_ 851 BltLockStAtRowSecRiBltLockEquid 0 "CptEquid_Equid" 1 "CptEquid_NotEquid";
VAL_ 851 BltLockStAtRowSecRiBltLockSt1 0 "BltLockSt1_Unlock" 1 "BltLockSt1_Lock";
VAL_ 851 BltLockStAtRowSecRiBltLockSts 0 "DevErrSts2_NoFlt" 1 "DevErrSts2_Flt";
VAL_ 851 BltLockStAtRowThrdLeBltLockEquid 0 "CptEquid_Equid" 1 "CptEquid_NotEquid";
VAL_ 851 BltLockStAtRowThrdLeBltLockSt1 0 "BltLockSt1_Unlock" 1 "BltLockSt1_Lock";
VAL_ 851 BltLockStAtRowThrdLeBltLockSts 0 "DevErrSts2_NoFlt" 1 "DevErrSts2_Flt";
VAL_ 851 BltLockStAtRowThrdRiBltLockEquid 0 "CptEquid_Equid" 1 "CptEquid_NotEquid";
VAL_ 851 BltLockStAtRowThrdRiBltLockSt1 0 "BltLockSt1_Unlock" 1 "BltLockSt1_Lock";
VAL_ 851 BltLockStAtRowThrdRiBltLockSts 0 "DevErrSts2_NoFlt" 1 "DevErrSts2_Flt";
VAL_ 851 BtnLockSts1BtnSts2 0 "BtnSts2_Idle" 1 "BtnSts2_ShortPsd" 2 "BtnSts2_TwicePsd" 3 "BtnSts2_LongPsd" 4 "BtnSts2_Released";
VAL_ 851 BtnLockSts1KeyId 0 "KeyId1_Key0" 1 "KeyId1_Key1" 2 "KeyId1_Key2" 3 "KeyId1_Key3" 4 "KeyId1_Key4" 5 "KeyId1_Key5" 6 "KeyId1_Key6" 7 "KeyId1_Key7" 8 "KeyId1_Key8" 9 "KeyId1_Key9" 10 "KeyId1_Key10" 11 "KeyId1_Key11";
VAL_ 851 BtnTrSts1BtnSts2 0 "BtnSts2_Idle" 1 "BtnSts2_ShortPsd" 2 "BtnSts2_TwicePsd" 3 "BtnSts2_LongPsd" 4 "BtnSts2_Released";
VAL_ 851 BtnTrSts1KeyId 0 "KeyId1_Key0" 1 "KeyId1_Key1" 2 "KeyId1_Key2" 3 "KeyId1_Key3" 4 "KeyId1_Key4" 5 "KeyId1_Key5" 6 "KeyId1_Key6" 7 "KeyId1_Key7" 8 "KeyId1_Key8" 9 "KeyId1_Key9" 10 "KeyId1_Key10" 11 "KeyId1_Key11";
VAL_ 851 BtnUnlckSts1BtnSts2 0 "BtnSts2_Idle" 1 "BtnSts2_ShortPsd" 2 "BtnSts2_TwicePsd" 3 "BtnSts2_LongPsd" 4 "BtnSts2_Released";
VAL_ 851 BtnUnlckSts1KeyId 0 "KeyId1_Key0" 1 "KeyId1_Key1" 2 "KeyId1_Key2" 3 "KeyId1_Key3" 4 "KeyId1_Key4" 5 "KeyId1_Key5" 6 "KeyId1_Key6" 7 "KeyId1_Key7" 8 "KeyId1_Key8" 9 "KeyId1_Key9" 10 "KeyId1_Key10" 11 "KeyId1_Key11";
VAL_ 851 DCChrgnHndlSts 0 "OnBdChrgrHndlSts_Disconnected" 1 "OnBdChrgrHndlSts_ConnectedWithoutPower" 2 "OnBdChrgrHndlSts_PowerAvailableButNotActivated" 3 "OnBdChrgrHndlSts_ConnectedWithPower" 4 "OnBdChrgrHndlSts_Init" 5 "OnBdChrgrHndlSts_Fault";
VAL_ 851 ULoWarnULoWarn 0 "ULoWarn_UOk" 1 "ULoWarn_ULoTmp" 2 "ULoWarn_ULoPrmnt";
VAL_ 851 UsgModDeactvnQly 0 "Qly4_InvalidValue" 1 "Qly4_QlyNotOkLowConfidence" 2 "Qly4_QlyOkHighConfidence" 3 "Qly4_InvalidValue2";
VAL_ 545 BltLockStAtPassBltLockSt1 0 "BltLockSt1_Unlock" 1 "BltLockSt1_Lock";
VAL_ 545 BltLockStAtPassBltLockSts 0 "DevErrSts2_NoFlt" 1 "DevErrSts2_Flt";
VAL_ 545 MsgReqForRtrctrRvsbLe 0 "OnOff1_Off" 1 "OnOff1_On";
VAL_ 545 TwliBriSts 0 "TwliBriSts1_Night" 1 "TwliBriSts1_Day";
VAL_ 579 DcDcActvd 0 "DcDcActvd_NoConversionToLVSide" 1 "DcDcActvd_ConversionToLVSide";
VAL_ 579 LeFrntTireMsgBattLoSt 0 "Normalwarning_Normal" 1 "Normalwarning_Warning";
VAL_ 579 LeFrntTireMsgFastLoseWarnFlg 0 "Normalwarning_Normal" 1 "Normalwarning_Warning";
VAL_ 579 LeFrntTireMsgMsgOldFlg 0 "Normalwarning_Normal" 1 "Normalwarning_Warning";
VAL_ 579 LeFrntTireMsgPWarnFlg 0 "PWarnFlg_Normal" 1 "PWarnFlg_LowPressureWarning" 2 "PWarnFlg_HighPressureWarning" 3 "PWarnFlg_Reserve";
VAL_ 579 LeFrntTireMsgSysWarnFlg 0 "Normalwarning_Normal" 1 "Normalwarning_Warning";
VAL_ 579 LeFrntTireMsgTireFillgAssiPSts 0 "Normalwarning_Normal" 1 "Normalwarning_Warning";
VAL_ 579 LeFrntTireMsgTWarnFlg 0 "Normalwarning_Normal" 1 "Normalwarning_Warning";
VAL_ 579 LeReTireMsgBattLoSt 0 "Normalwarning_Normal" 1 "Normalwarning_Warning";
VAL_ 579 LeReTireMsgFastLoseWarnFlg 0 "Normalwarning_Normal" 1 "Normalwarning_Warning";
VAL_ 579 LeReTireMsgMsgOldFlg 0 "Normalwarning_Normal" 1 "Normalwarning_Warning";
VAL_ 579 LeReTireMsgPWarnFlg 0 "PWarnFlg_Normal" 1 "PWarnFlg_LowPressureWarning" 2 "PWarnFlg_HighPressureWarning" 3 "PWarnFlg_Reserve";
VAL_ 579 LeReTireMsgSysWarnFlg 0 "Normalwarning_Normal" 1 "Normalwarning_Warning";
VAL_ 579 LeReTireMsgTireFillgAssiPSts 0 "Normalwarning_Normal" 1 "Normalwarning_Warning";
VAL_ 579 LeReTireMsgTWarnFlg 0 "Normalwarning_Normal" 1 "Normalwarning_Warning";
VAL_ 579 OnBdChrgrHndlSts1 0 "OnBdChrgrHndlSts1_Disconnected" 1 "OnBdChrgrHndlSts1_ConnectedWithoutPower" 2 "OnBdChrgrHndlSts1_PowerAvailableButNotActivated" 3 "OnBdChrgrHndlSts1_ConnectedWithPower" 4 "OnBdChrgrHndlSts1_DischargeConnectwithoutpowerincar" 5 "OnBdChrgrHndlSts1_DischargeConnectwithoutpoweroutcar" 6 "OnBdChrgrHndlSts1_DischargeConnectwithpowerincar" 7 "OnBdChrgrHndlSts1_DischargeConnectwithpoweroutcar" 8 "OnBdChrgrHndlSts1_Init" 9 "OnBdChrgrHndlSts1_Fault" 10 "OnBdChrgrHndlSts1_NotCompleteConnnected" 11 "OnBdChrgrHndlSts1_Reserved0" 12 "OnBdChrgrHndlSts1_Reserved1" 13 "OnBdChrgrHndlSts1_Reserved2";
VAL_ 579 RiFrntTireMsgBattLoSt 0 "Normalwarning_Normal" 1 "Normalwarning_Warning";
VAL_ 579 RiFrntTireMsgFastLoseWarnFlg 0 "Normalwarning_Normal" 1 "Normalwarning_Warning";
VAL_ 579 RiFrntTireMsgMsgOldFlg 0 "Normalwarning_Normal" 1 "Normalwarning_Warning";
VAL_ 579 RiFrntTireMsgPWarnFlg 0 "PWarnFlg_Normal" 1 "PWarnFlg_LowPressureWarning" 2 "PWarnFlg_HighPressureWarning" 3 "PWarnFlg_Reserve";
VAL_ 579 RiFrntTireMsgSysWarnFlg 0 "Normalwarning_Normal" 1 "Normalwarning_Warning";
VAL_ 579 RiFrntTireMsgTireFillgAssiPSts 0 "Normalwarning_Normal" 1 "Normalwarning_Warning";
VAL_ 579 RiFrntTireMsgTWarnFlg 0 "Normalwarning_Normal" 1 "Normalwarning_Warning";
VAL_ 579 RiReTireMsgBattLoSt 0 "Normalwarning_Normal" 1 "Normalwarning_Warning";
VAL_ 579 RiReTireMsgFastLoseWarnFlg 0 "Normalwarning_Normal" 1 "Normalwarning_Warning";
VAL_ 579 RiReTireMsgMsgOldFlg 0 "Normalwarning_Normal" 1 "Normalwarning_Warning";
VAL_ 579 RiReTireMsgPWarnFlg 0 "PWarnFlg_Normal" 1 "PWarnFlg_LowPressureWarning" 2 "PWarnFlg_HighPressureWarning" 3 "PWarnFlg_Reserve";
VAL_ 579 RiReTireMsgSysWarnFlg 0 "Normalwarning_Normal" 1 "Normalwarning_Warning";
VAL_ 579 RiReTireMsgTireFillgAssiPSts 0 "Normalwarning_Normal" 1 "Normalwarning_Warning";
VAL_ 579 RiReTireMsgTWarnFlg 0 "Normalwarning_Normal" 1 "Normalwarning_Warning";
VAL_ 451 AD4HeatingCircTestSts 0 "OffOnError_Off" 1 "OffOnError_On" 2 "OffOnError_Error" 3 "OffOnError_Reserved";
VAL_ 451 AdjSpdLimnFusnTrfcSgn 0 "Boolean_FALSE" 1 "Boolean_TRUE";
VAL_ 451 EngTQf 0 "Qf1_DevOfDataUndefd" 1 "Qf1_DataTmpUndefdAndEvlnInProgs" 2 "Qf1_DevOfDataNotWithinRngAllwd" 3 "Qf1_DataCalcdWithDevDefd";
VAL_ 451 ExtrLtgStsAFS 0 "DevSts4_Off" 1 "DevSts4_On" 2 "DevSts4_Err" 3 "DevSts4_Resd";
VAL_ 451 ExtrLtgStsAHBC 0 "DevSts4_Off" 1 "DevSts4_On" 2 "DevSts4_Err" 3 "DevSts4_Resd";
VAL_ 451 ExtrLtgStsAHL 0 "DevSts4_Off" 1 "DevSts4_On" 2 "DevSts4_Err" 3 "DevSts4_Resd";
VAL_ 451 ExtrLtgStsAllWL 0 "DevSts4_Off" 1 "DevSts4_On" 2 "DevSts4_Err" 3 "DevSts4_Resd";
VAL_ 451 ExtrLtgStsApproach 0 "DevSts4_Off" 1 "DevSts4_On" 2 "DevSts4_Err" 3 "DevSts4_Resd";
VAL_ 451 ExtrLtgStsCornrgLi 0 "DevSts4_Off" 1 "DevSts4_On" 2 "DevSts4_Err" 3 "DevSts4_Resd";
VAL_ 451 ExtrLtgStsDBL 0 "DevSts4_Off" 1 "DevSts4_On" 2 "DevSts4_Err" 3 "DevSts4_Resd";
VAL_ 451 ExtrLtgStsDRL 0 "DevSts4_Off" 1 "DevSts4_On" 2 "DevSts4_Err" 3 "DevSts4_Resd";
VAL_ 451 ExtrLtgStsFlash 0 "DevSts4_Off" 1 "DevSts4_On" 2 "DevSts4_Err" 3 "DevSts4_Resd";
VAL_ 451 ExtrLtgStsFrntFog 0 "DevSts4_Off" 1 "DevSts4_On" 2 "DevSts4_Err" 3 "DevSts4_Resd";
VAL_ 451 ExtrLtgStsGoodbye 0 "DevSts4_Off" 1 "DevSts4_On" 2 "DevSts4_Err" 3 "DevSts4_Resd";
VAL_ 451 ExtrLtgStsHiBeam 0 "DevSts4_Off" 1 "DevSts4_On" 2 "DevSts4_Err" 3 "DevSts4_Resd";
VAL_ 451 ExtrLtgStsHomeSafe 0 "DevSts4_Off" 1 "DevSts4_On" 2 "DevSts4_Err" 3 "DevSts4_Resd";
VAL_ 451 ExtrLtgStsHWL 0 "DevSts4_Off" 1 "DevSts4_On" 2 "DevSts4_Err" 3 "DevSts4_Resd";
VAL_ 451 ExtrLtgStsLoBeam 0 "DevSts4_Off" 1 "DevSts4_On" 2 "DevSts4_Err" 3 "DevSts4_Resd";
VAL_ 451 ExtrLtgStsLtgShow 0 "DevSts4_Off" 1 "DevSts4_On" 2 "DevSts4_Err" 3 "DevSts4_Resd";
VAL_ 451 ExtrLtgStsPosLiFrnt 0 "DevSts4_Off" 1 "DevSts4_On" 2 "DevSts4_Err" 3 "DevSts4_Resd";
VAL_ 451 ExtrLtgStsPosLiRe 0 "DevSts4_Off" 1 "DevSts4_On" 2 "DevSts4_Err" 3 "DevSts4_Resd";
VAL_ 451 ExtrLtgStsReFog 0 "DevSts4_Off" 1 "DevSts4_On" 2 "DevSts4_Err" 3 "DevSts4_Resd";
VAL_ 451 ExtrLtgStsReverseLi 0 "DevSts4_Off" 1 "DevSts4_On" 2 "DevSts4_Err" 3 "DevSts4_Resd";
VAL_ 451 ExtrLtgStsStopLi 0 "DevSts4_Off" 1 "DevSts4_On" 2 "DevSts4_Err" 3 "DevSts4_Resd";
VAL_ 451 ExtrLtgStsTurnIndrLe 0 "DevSts4_Off" 1 "DevSts4_On" 2 "DevSts4_Err" 3 "DevSts4_Resd";
VAL_ 451 ExtrLtgStsTurnIndrRi 0 "DevSts4_Off" 1 "DevSts4_On" 2 "DevSts4_Err" 3 "DevSts4_Resd";
VAL_ 451 ExtrLtgStsWelcome 0 "DevSts4_Off" 1 "DevSts4_On" 2 "DevSts4_Err" 3 "DevSts4_Resd";
VAL_ 451 RainfallAmnt 0 "AmntSnsr_Amnt" 14 "AmntSnsr_InitValue" 15 "AmntSnsr_Error";
VAL_ 451 RcwmLiActvd 0 "OnOff1_Off" 1 "OnOff1_On";
VAL_ 451 SwtIndcrIndcrTypExtReq 0 "IndcrTypExt1_Off" 1 "IndcrTypExt1_Le" 2 "IndcrTypExt1_Ri";
VAL_ 451 SwtIndcrIndcrTypExtReqToUpdQf 0 "Qf1_DevOfDataUndefd" 1 "Qf1_DataTmpUndefdAndEvlnInProgs" 2 "Qf1_DevOfDataNotWithinRngAllwd" 3 "Qf1_DataCalcdWithDevDefd";
VAL_ 451 TrLockSts 0 "LockSts2_LockStsUkwn" 1 "LockSts2_Unlckd" 2 "LockSts2_Lockd" 3 "LockSts2_SafeLockd";
VAL_ 451 TurnIndcrMonostableQf 0 "GenQf1_UndefindDataAccur" 1 "GenQf1_TmpUndefdData" 2 "GenQf1_DataAccurNotWithinSpcn" 3 "GenQf1_AccurData";
VAL_ 451 TurnIndcrMonostableTurnIndcrMonostable 0 "Dir10_Idle" 1 "Dir10_Leftflash" 2 "Dir10_Left" 3 "Dir10_Rightflash" 4 "Dir10_Right";
VAL_ 451 TwliBriRawQf 0 "GenQf1_UndefindDataAccur" 1 "GenQf1_TmpUndefdData" 2 "GenQf1_DataAccurNotWithinSpcn" 3 "GenQf1_AccurData";
VAL_ 451 VehParkNotActvd 0 "Flg1_Rst" 1 "Flg1_Set";
VAL_ 451 WipgInfoWipgSpdInfo 0 "WipgSpdInfo_Off" 1 "WipgSpdInfo_IntlLo" 2 "WipgSpdInfo_IntlHi" 3 "WipgSpdInfo_WipgSpd4045" 4 "WipgSpdInfo_WipgSpd4650" 5 "WipgSpdInfo_WipgSpd5155" 6 "WipgSpdInfo_WipgSpd5660" 7 "WipgSpdInfo_WiprErr";
VAL_ 451 WipgInfoWiprActv 0 "OnOff1_Off" 1 "OnOff1_On";
VAL_ 451 WipgInfoWiprInWipgAr 0 "OnOff1_Off" 1 "OnOff1_On";
VAL_ 931 PassAirbSts 0 "OnOff2_On" 1 "OnOff2_Off";
VAL_ 931 VehBattUSysUQf 0 "GenQf1_UndefindDataAccur" 1 "GenQf1_TmpUndefdData" 2 "GenQf1_DataAccurNotWithinSpcn" 3 "GenQf1_AccurData";
VAL_ 83 BltLockStAtDrvrBltLockSt1 0 "BltLockSt1_Unlock" 1 "BltLockSt1_Lock";
VAL_ 83 BltLockStAtDrvrBltLockSts 0 "DevErrSts2_NoFlt" 1 "DevErrSts2_Flt";
VAL_ 83 DoorDrvrLockSts 0 "LockSts2_LockStsUkwn" 1 "LockSts2_Unlckd" 2 "LockSts2_Lockd" 3 "LockSts2_SafeLockd";
VAL_ 83 DoorLeReLockSts 0 "LockSts2_LockStsUkwn" 1 "LockSts2_Unlckd" 2 "LockSts2_Lockd" 3 "LockSts2_SafeLockd";
VAL_ 83 DrvrGearShiftParkReq1 0 "SwtPark1_SwtParkNotActv" 1 "SwtPark1_SwtParkActv";
VAL_ 83 DrvrGearShiftParkReqSts 0 "ClutchPedlPsd_No" 1 "ClutchPedlPsd_Yes" 2 "ClutchPedlPsd_Reserved1" 3 "ClutchPedlPsd_Reserved2";
VAL_ 83 EngSt1WdStsEngSt1WdSts 0 "EngSt1_Ini" 1 "EngSt1_Awake" 2 "EngSt1_Rdy" 3 "EngSt1_PreStrtg" 4 "EngSt1_StrtgInProgs" 5 "EngSt1_RunngRunng" 6 "EngSt1_RunngStb" 7 "EngSt1_RunngStrtgInProgs" 8 "EngSt1_RunngRemStrtd" 9 "EngSt1_AftRun";
VAL_ 83 LcmaLedStsDrvrSide 0 "YesNo1_Yes" 1 "YesNo1_No";
VAL_ 83 PinionSteerAgGroupPinionSteerAg1Qf 0 "GenQf1_UndefindDataAccur" 1 "GenQf1_TmpUndefdData" 2 "GenQf1_DataAccurNotWithinSpcn" 3 "GenQf1_AccurData";
VAL_ 83 PinionSteerAgGroupPinionSteerAgSpd1Qf 0 "GenQf1_UndefindDataAccur" 1 "GenQf1_TmpUndefdData" 2 "GenQf1_DataAccurNotWithinSpcn" 3 "GenQf1_AccurData";
VAL_ 83 PinionSteerAgGroupSteerWhlTqQf 0 "GenQf1_UndefindDataAccur" 1 "GenQf1_TmpUndefdData" 2 "GenQf1_DataAccurNotWithinSpcn" 3 "GenQf1_AccurData";
VAL_ 83 RecOfPostImpctBrkgSuspcSuspcPostImpctBrkg 0 "PostImpctBrkgNoYes_Undefd0" 1 "PostImpctBrkgNoYes_No" 2 "PostImpctBrkgNoYes_Yes" 3 "PostImpctBrkgNoYes_Undefd3";
VAL_ 83 SuspPosnVertLe1FrntQf 0 "GenQf1_UndefindDataAccur" 1 "GenQf1_TmpUndefdData" 2 "GenQf1_DataAccurNotWithinSpcn" 3 "GenQf1_AccurData";
VAL_ 83 SuspPosnVertLe1ReQf 0 "GenQf1_UndefindDataAccur" 1 "GenQf1_TmpUndefdData" 2 "GenQf1_DataAccurNotWithinSpcn" 3 "GenQf1_AccurData";
VAL_ 83 SuspPosnVertRi1SuspPosnVertRiFrntQf 0 "GenQf1_UndefindDataAccur" 1 "GenQf1_TmpUndefdData" 2 "GenQf1_DataAccurNotWithinSpcn" 3 "GenQf1_AccurData";
VAL_ 83 SuspPosnVertRi1SuspPosnVertRiReQf 0 "GenQf1_UndefindDataAccur" 1 "GenQf1_TmpUndefdData" 2 "GenQf1_DataAccurNotWithinSpcn" 3 "GenQf1_AccurData";
VAL_ 83 VehModMngtGlbSafe1CarModSts1 0 "CarModSts1_CarModNorm" 1 "CarModSts1_CarModTrnsp" 2 "CarModSts1_CarModFcy" 3 "CarModSts1_CarModCrash" 5 "CarModSts1_CarModDyno";
VAL_ 83 VehModMngtGlbSafe1FltEgyCnsWdSts 0 "FltEgyCns1_NoFlt" 1 "FltEgyCns1_Flt";
VAL_ 83 VehModMngtGlbSafe1UsgModSts 0 "UsgModSts1_UsgModAbdnd" 1 "UsgModSts1_UsgModInActv" 2 "UsgModSts1_UsgModCnvinc" 11 "UsgModSts1_UsgModActv" 13 "UsgModSts1_UsgModDrvg";
VAL_ 83 VehTiAndDataDataValid 0 "NoYes1_No" 1 "NoYes1_Yes";
VAL_ 83 WinPosnStsAtDrvr 0 "WinAndRoofAndCurtPosnTyp_PosnUkwn" 1 "WinAndRoofAndCurtPosnTyp_ClsFull" 2 "WinAndRoofAndCurtPosnTyp_PercOpen4" 3 "WinAndRoofAndCurtPosnTyp_PercOpen8" 4 "WinAndRoofAndCurtPosnTyp_PercOpen12" 5 "WinAndRoofAndCurtPosnTyp_PercOpen16" 6 "WinAndRoofAndCurtPosnTyp_PercOpen20" 7 "WinAndRoofAndCurtPosnTyp_PercOpen24" 8 "WinAndRoofAndCurtPosnTyp_PercOpen28" 9 "WinAndRoofAndCurtPosnTyp_PercOpen32" 10 "WinAndRoofAndCurtPosnTyp_PercOpen36" 11 "WinAndRoofAndCurtPosnTyp_PercOpen40" 12 "WinAndRoofAndCurtPosnTyp_PercOpen44" 13 "WinAndRoofAndCurtPosnTyp_PercOpen48" 14 "WinAndRoofAndCurtPosnTyp_PercOpen52" 15 "WinAndRoofAndCurtPosnTyp_PercOpen56" 16 "WinAndRoofAndCurtPosnTyp_PercOpen60" 17 "WinAndRoofAndCurtPosnTyp_PercOpen64" 18 "WinAndRoofAndCurtPosnTyp_PercOpen68" 19 "WinAndRoofAndCurtPosnTyp_PercOpen72" 20 "WinAndRoofAndCurtPosnTyp_PercOpen76" 21 "WinAndRoofAndCurtPosnTyp_PercOpen80" 22 "WinAndRoofAndCurtPosnTyp_PercOpen84" 23 "WinAndRoofAndCurtPosnTyp_PercOpen88" 24 "WinAndRoofAndCurtPosnTyp_PercOpen92" 25 "WinAndRoofAndCurtPosnTyp_PercOpen96" 26 "WinAndRoofAndCurtPosnTyp_OpenFull" 27 "WinAndRoofAndCurtPosnTyp_Resd1" 28 "WinAndRoofAndCurtPosnTyp_Resd2" 29 "WinAndRoofAndCurtPosnTyp_Resd3" 30 "WinAndRoofAndCurtPosnTyp_Resd4" 31 "WinAndRoofAndCurtPosnTyp_Movg";
VAL_ 83 WinPosnStsAtReLe 0 "WinAndRoofAndCurtPosnTyp_PosnUkwn" 1 "WinAndRoofAndCurtPosnTyp_ClsFull" 2 "WinAndRoofAndCurtPosnTyp_PercOpen4" 3 "WinAndRoofAndCurtPosnTyp_PercOpen8" 4 "WinAndRoofAndCurtPosnTyp_PercOpen12" 5 "WinAndRoofAndCurtPosnTyp_PercOpen16" 6 "WinAndRoofAndCurtPosnTyp_PercOpen20" 7 "WinAndRoofAndCurtPosnTyp_PercOpen24" 8 "WinAndRoofAndCurtPosnTyp_PercOpen28" 9 "WinAndRoofAndCurtPosnTyp_PercOpen32" 10 "WinAndRoofAndCurtPosnTyp_PercOpen36" 11 "WinAndRoofAndCurtPosnTyp_PercOpen40" 12 "WinAndRoofAndCurtPosnTyp_PercOpen44" 13 "WinAndRoofAndCurtPosnTyp_PercOpen48" 14 "WinAndRoofAndCurtPosnTyp_PercOpen52" 15 "WinAndRoofAndCurtPosnTyp_PercOpen56" 16 "WinAndRoofAndCurtPosnTyp_PercOpen60" 17 "WinAndRoofAndCurtPosnTyp_PercOpen64" 18 "WinAndRoofAndCurtPosnTyp_PercOpen68" 19 "WinAndRoofAndCurtPosnTyp_PercOpen72" 20 "WinAndRoofAndCurtPosnTyp_PercOpen76" 21 "WinAndRoofAndCurtPosnTyp_PercOpen80" 22 "WinAndRoofAndCurtPosnTyp_PercOpen84" 23 "WinAndRoofAndCurtPosnTyp_PercOpen88" 24 "WinAndRoofAndCurtPosnTyp_PercOpen92" 25 "WinAndRoofAndCurtPosnTyp_PercOpen96" 26 "WinAndRoofAndCurtPosnTyp_OpenFull" 27 "WinAndRoofAndCurtPosnTyp_Resd1" 28 "WinAndRoofAndCurtPosnTyp_Resd2" 29 "WinAndRoofAndCurtPosnTyp_Resd3" 30 "WinAndRoofAndCurtPosnTyp_Resd4" 31 "WinAndRoofAndCurtPosnTyp_Movg";
VAL_ 837 EPBLockMgrReqCmd 0 "TrsmLockMgrCmd_Undefd" 1 "TrsmLockMgrCmd_Unlck" 2 "TrsmLockMgrCmd_Lock" 3 "TrsmLockMgrCmd_Resd";
VAL_ 837 TiAndDateIndcnDataValid 0 "NoYes1_No" 1 "NoYes1_Yes";
VAL_ 1347 VFCVectorZCUDMVFCid0 0 "VFCOnOff_Off" 1 "VFCOnOff_On";
VAL_ 1347 VFCVectorZCUDMVFCid1 0 "VFCOnOff_Off" 1 "VFCOnOff_On";
VAL_ 1347 VFCVectorZCUDMVFCid10 0 "VFCOnOff_Off" 1 "VFCOnOff_On";
VAL_ 1347 VFCVectorZCUDMVFCid11 0 "VFCOnOff_Off" 1 "VFCOnOff_On";
VAL_ 1347 VFCVectorZCUDMVFCid12 0 "VFCOnOff_Off" 1 "VFCOnOff_On";
VAL_ 1347 VFCVectorZCUDMVFCid13 0 "VFCOnOff_Off" 1 "VFCOnOff_On";
VAL_ 1347 VFCVectorZCUDMVFCid14 0 "VFCOnOff_Off" 1 "VFCOnOff_On";
VAL_ 1347 VFCVectorZCUDMVFCid15 0 "VFCOnOff_Off" 1 "VFCOnOff_On";
VAL_ 1347 VFCVectorZCUDMVFCid16 0 "VFCOnOff_Off" 1 "VFCOnOff_On";
VAL_ 1347 VFCVectorZCUDMVFCid17 0 "VFCOnOff_Off" 1 "VFCOnOff_On";
VAL_ 1347 VFCVectorZCUDMVFCid18 0 "VFCOnOff_Off" 1 "VFCOnOff_On";
VAL_ 1347 VFCVectorZCUDMVFCid19 0 "VFCOnOff_Off" 1 "VFCOnOff_On";
VAL_ 1347 VFCVectorZCUDMVFCid2 0 "VFCOnOff_Off" 1 "VFCOnOff_On";
VAL_ 1347 VFCVectorZCUDMVFCid20 0 "VFCOnOff_Off" 1 "VFCOnOff_On";
VAL_ 1347 VFCVectorZCUDMVFCid21 0 "VFCOnOff_Off" 1 "VFCOnOff_On";
VAL_ 1347 VFCVectorZCUDMVFCid22 0 "VFCOnOff_Off" 1 "VFCOnOff_On";
VAL_ 1347 VFCVectorZCUDMVFCid23 0 "VFCOnOff_Off" 1 "VFCOnOff_On";
VAL_ 1347 VFCVectorZCUDMVFCid24 0 "VFCOnOff_Off" 1 "VFCOnOff_On";
VAL_ 1347 VFCVectorZCUDMVFCid25 0 "VFCOnOff_Off" 1 "VFCOnOff_On";
VAL_ 1347 VFCVectorZCUDMVFCid26 0 "VFCOnOff_Off" 1 "VFCOnOff_On";
VAL_ 1347 VFCVectorZCUDMVFCid27 0 "VFCOnOff_Off" 1 "VFCOnOff_On";
VAL_ 1347 VFCVectorZCUDMVFCid28 0 "VFCOnOff_Off" 1 "VFCOnOff_On";
VAL_ 1347 VFCVectorZCUDMVFCid29 0 "VFCOnOff_Off" 1 "VFCOnOff_On";
VAL_ 1347 VFCVectorZCUDMVFCid3 0 "VFCOnOff_Off" 1 "VFCOnOff_On";
VAL_ 1347 VFCVectorZCUDMVFCid30 0 "VFCOnOff_Off" 1 "VFCOnOff_On";
VAL_ 1347 VFCVectorZCUDMVFCid31 0 "VFCOnOff_Off" 1 "VFCOnOff_On";
VAL_ 1347 VFCVectorZCUDMVFCid32 0 "VFCOnOff_Off" 1 "VFCOnOff_On";
VAL_ 1347 VFCVectorZCUDMVFCid33 0 "VFCOnOff_Off" 1 "VFCOnOff_On";
VAL_ 1347 VFCVectorZCUDMVFCid34 0 "VFCOnOff_Off" 1 "VFCOnOff_On";
VAL_ 1347 VFCVectorZCUDMVFCid35 0 "VFCOnOff_Off" 1 "VFCOnOff_On";
VAL_ 1347 VFCVectorZCUDMVFCid36 0 "VFCOnOff_Off" 1 "VFCOnOff_On";
VAL_ 1347 VFCVectorZCUDMVFCid37 0 "VFCOnOff_Off" 1 "VFCOnOff_On";
VAL_ 1347 VFCVectorZCUDMVFCid38 0 "VFCOnOff_Off" 1 "VFCOnOff_On";
VAL_ 1347 VFCVectorZCUDMVFCid39 0 "VFCOnOff_Off" 1 "VFCOnOff_On";
VAL_ 1347 VFCVectorZCUDMVFCid4 0 "VFCOnOff_Off" 1 "VFCOnOff_On";
VAL_ 1347 VFCVectorZCUDMVFCid40 0 "VFCOnOff_Off" 1 "VFCOnOff_On";
VAL_ 1347 VFCVectorZCUDMVFCid41 0 "VFCOnOff_Off" 1 "VFCOnOff_On";
VAL_ 1347 VFCVectorZCUDMVFCid42 0 "VFCOnOff_Off" 1 "VFCOnOff_On";
VAL_ 1347 VFCVectorZCUDMVFCid43 0 "VFCOnOff_Off" 1 "VFCOnOff_On";
VAL_ 1347 VFCVectorZCUDMVFCid44 0 "VFCOnOff_Off" 1 "VFCOnOff_On";
VAL_ 1347 VFCVectorZCUDMVFCid45 0 "VFCOnOff_Off" 1 "VFCOnOff_On";
VAL_ 1347 VFCVectorZCUDMVFCid46 0 "VFCOnOff_Off" 1 "VFCOnOff_On";
VAL_ 1347 VFCVectorZCUDMVFCid47 0 "VFCOnOff_Off" 1 "VFCOnOff_On";
VAL_ 1347 VFCVectorZCUDMVFCid48 0 "VFCOnOff_Off" 1 "VFCOnOff_On";
VAL_ 1347 VFCVectorZCUDMVFCid49 0 "VFCOnOff_Off" 1 "VFCOnOff_On";
VAL_ 1347 VFCVectorZCUDMVFCid5 0 "VFCOnOff_Off" 1 "VFCOnOff_On";
VAL_ 1347 VFCVectorZCUDMVFCid50 0 "VFCOnOff_Off" 1 "VFCOnOff_On";
VAL_ 1347 VFCVectorZCUDMVFCid51 0 "VFCOnOff_Off" 1 "VFCOnOff_On";
VAL_ 1347 VFCVectorZCUDMVFCid52 0 "VFCOnOff_Off" 1 "VFCOnOff_On";
VAL_ 1347 VFCVectorZCUDMVFCid53 0 "VFCOnOff_Off" 1 "VFCOnOff_On";
VAL_ 1347 VFCVectorZCUDMVFCid54 0 "VFCOnOff_Off" 1 "VFCOnOff_On";
VAL_ 1347 VFCVectorZCUDMVFCid55 0 "VFCOnOff_Off" 1 "VFCOnOff_On";
VAL_ 1347 VFCVectorZCUDMVFCid56 0 "VFCOnOff_Off" 1 "VFCOnOff_On";
VAL_ 1347 VFCVectorZCUDMVFCid57 0 "VFCOnOff_Off" 1 "VFCOnOff_On";
VAL_ 1347 VFCVectorZCUDMVFCid58 0 "VFCOnOff_Off" 1 "VFCOnOff_On";
VAL_ 1347 VFCVectorZCUDMVFCid59 0 "VFCOnOff_Off" 1 "VFCOnOff_On";
VAL_ 1347 VFCVectorZCUDMVFCid6 0 "VFCOnOff_Off" 1 "VFCOnOff_On";
VAL_ 1347 VFCVectorZCUDMVFCid60 0 "VFCOnOff_Off" 1 "VFCOnOff_On";
VAL_ 1347 VFCVectorZCUDMVFCid61 0 "VFCOnOff_Off" 1 "VFCOnOff_On";
VAL_ 1347 VFCVectorZCUDMVFCid7 0 "VFCOnOff_Off" 1 "VFCOnOff_On";
VAL_ 1347 VFCVectorZCUDMVFCid8 0 "VFCOnOff_Off" 1 "VFCOnOff_On";
VAL_ 1347 VFCVectorZCUDMVFCid9 0 "VFCOnOff_Off" 1 "VFCOnOff_On";
VAL_ 1283 WakeUpReasonsforZCUDM 0 "WakeupReasons_667949" 1 "WakeupReasons_667950" 2 "WakeupReasons_169654" 3 "WakeupReasons_667951" 4 "WakeupReasons_168965" 5 "WakeupReasons_197643" 6 "WakeupReasons_264933" 7 "WakeupReasons_45654" 8 "WakeupReasons_22058" 9 "WakeupReasons_49446" 10 "WakeupReasons_22060" 11 "WakeupReasons_269740" 12 "WakeupReasons_269735" 13 "WakeupReasons_269739" 14 "WakeupReasons_658500" 15 "WakeupReasons_21901" 16 "WakeupReasons_45793" 17 "WakeupReasons_45794" 18 "WakeupReasons_22005" 19 "WakeupReasons_22013" 20 "WakeupReasons_22100" 21 "WakeupReasons_45659" 22 "WakeupReasons_45657" 23 "WakeupReasons_140084" 24 "WakeupReasons_21973" 25 "WakeupReasons_91253" 26 "WakeupReasons_88123" 27 "WakeupReasons_88125" 28 "WakeupReasons_321583" 29 "WakeupReasons_74188" 30 "WakeupReasons_667945" 31 "WakeupReasons_169655" 32 "WakeupReasons_667948" 33 "WakeupReasons_168966" 34 "WakeupReasons_170865" 35 "WakeupReasons_197642" 36 "WakeupReasons_264876" 37 "WakeupReasons_191050" 38 "WakeupReasons_182033" 39 "WakeupReasons_200937" 40 "WakeupReasons_170807" 41 "WakeupReasons_319139" 42 "WakeupReasons_100298" 43 "WakeupReasons_100275" 44 "WakeupReasons_100300" 45 "WakeupReasons_100278" 46 "WakeupReasons_100281" 47 "WakeupReasons_265333" 48 "WakeupReasons_108776" 49 "WakeupReasons_176921" 50 "WakeupReasons_197826" 51 "WakeupReasons_185670" 52 "WakeupReasons_161066" 53 "WakeupReasons_200156" 54 "WakeupReasons_225696" 55 "WakeupReasons_21997" 56 "WakeupReasons_45656" 57 "WakeupReasons_266860" 58 "WakeupReasons_169894" 59 "WakeupReasons_320282" 60 "WakeupReasons_319422" 61 "WakeupReasons_320277" 62 "WakeupReasons_355601" 63 "WakeupReasons_360904" 64 "WakeupReasons_361505" 65 "WakeupReasons_361509" 66 "WakeupReasons_645094" 67 "WakeupReasons_68676" 68 "WakeupReasons_360008" 69 "WakeupReasons_109382" 70 "WakeupReasons_119273" 71 "WakeupReasons_224065" 72 "WakeupReasons_68644" 73 "WakeupReasons_109364" 74 "WakeupReasons_68481" 75 "WakeupReasons_224061" 76 "WakeupReasons_360006" 77 "WakeupReasons_138997" 78 "WakeupReasons_634696" 79 "WakeupReasons_645810" 80 "WakeupReasons_297868" 81 "WakeupReasons_315364" 82 "WakeupReasons_109367" 83 "WakeupReasons_320126" 84 "WakeupReasons_109387" 85 "WakeupReasons_634710" 86 "WakeupReasons_338820" 87 "WakeupReasons_67182" 88 "WakeupReasons_152237" 89 "WakeupReasons_145707" 90 "WakeupReasons_199172" 91 "WakeupReasons_144897" 92 "WakeupReasons_186489" 93 "WakeupReasons_144970" 94 "WakeupReasons_152786" 95 "WakeupReasons_264932" 96 "WakeupReasons_264934" 97 "WakeupReasons_356190" 98 "WakeupReasons_145688" 99 "WakeupReasons_95444" 100 "WakeupReasons_169945" 101 "WakeupReasons_140678" 102 "WakeupReasons_222553" 103 "WakeupReasons_224831" 104 "WakeupReasons_201815" 105 "WakeupReasons_45864" 106 "WakeupReasons_659549" 107 "WakeupReasons_45866" 108 "WakeupReasons_45867" 109 "WakeupReasons_169884" 110 "WakeupReasons_264962" 111 "WakeupReasons_201348" 112 "WakeupReasons_320287" 113 "WakeupReasons_156412" 114 "WakeupReasons_133749" 115 "WakeupReasons_355409" 116 "WakeupReasons_636692" 117 "WakeupReasons_533044" 118 "WakeupReasons_106774" 119 "WakeupReasons_145311" 120 "WakeupReasons_145319" 121 "WakeupReasons_152774" 122 "WakeupReasons_145330" 123 "WakeupReasons_145388" 124 "WakeupReasons_145399" 125 "WakeupReasons_145362" 126 "WakeupReasons_145385" 127 "WakeupReasons_145373" 128 "WakeupReasons_145288" 129 "WakeupReasons_145419" 130 "WakeupReasons_145454" 131 "WakeupReasons_145462" 132 "WakeupReasons_269156" 133 "WakeupReasons_300427" 134 "WakeupReasons_220322" 135 "WakeupReasons_224617" 136 "WakeupReasons_224634" 137 "WakeupReasons_300682" 138 "WakeupReasons_264958" 139 "WakeupReasons_160597" 140 "WakeupReasons_160602" 141 "WakeupReasons_108841" 142 "WakeupReasons_265569" 143 "WakeupReasons_526429" 144 "WakeupReasons_514545" 145 "WakeupReasons_265232" 146 "WakeupReasons_644550" 147 "WakeupReasons_317616" 148 "WakeupReasons_354791" 149 "WakeupReasons_320631" 150 "WakeupReasons_337565" 151 "WakeupReasons_532007" 152 "WakeupReasons_514503" 153 "WakeupReasons_299117" 154 "WakeupReasons_340667" 155 "WakeupReasons_321845" 156 "WakeupReasons_179103" 157 "WakeupReasons_108810" 158 "WakeupReasons_322857" 159 "WakeupReasons_658603" 160 "WakeupReasons_197648" 161 "WakeupReasons_160596" 162 "WakeupReasons_361272" 163 "WakeupReasons_361279" 164 "WakeupReasons_265305" 165 "WakeupReasons_265328" 166 "WakeupReasons_265330" 167 "WakeupReasons_298808" 168 "WakeupReasons_515804" 169 "WakeupReasons_514502" 170 "WakeupReasons_645753" 171 "WakeupReasons_646109" 172 "WakeupReasons_299547" 173 "WakeupReasons_318342" 174 "WakeupReasons_360543" 175 "WakeupReasons_356549" 176 "WakeupReasons_198484" 177 "WakeupReasons_300681" 178 "WakeupReasons_359211" 179 "WakeupReasons_534077" 180 "WakeupReasons_525705" 181 "WakeupReasons_360299" 182 "WakeupReasons_526445" 183 "WakeupReasons_534145" 184 "WakeupReasons_192030" 185 "WakeupReasons_652361" 186 "WakeupReasons_355214" 187 "WakeupReasons_321317" 188 "WakeupReasons_359187" 189 "WakeupReasons_321057" 190 "WakeupReasons_321319" 191 "WakeupReasons_321323" 192 "WakeupReasons_321077" 193 "WakeupReasons_320895" 194 "WakeupReasons_655340" 195 "WakeupReasons_636556" 196 "WakeupReasons_108834" 197 "WakeupReasons_265937" 198 "WakeupReasons_533050" 199 "WakeupReasons_526426" 200 "WakeupReasons_264712" 201 "WakeupReasons_319401" 202 "WakeupReasons_643973" 203 "WakeupReasons_223715" 204 "WakeupReasons_199159" 205 "WakeupReasons_318382" 206 "WakeupReasons_226967" 207 "WakeupReasons_531743" 208 "WakeupReasons_360542" 209 "WakeupReasons_264726" 210 "WakeupReasons_535214" 211 "WakeupReasons_335068" 212 "WakeupReasons_316796" 213 "WakeupReasons_526438" 214 "WakeupReasons_198433" 215 "WakeupReasons_225961" 216 "WakeupReasons_197665" 217 "WakeupReasons_224550" 218 "WakeupReasons_667962" 219 "WakeupReasons_667953" 220 "WakeupReasons_110885" 221 "WakeupReasons_224552" 222 "WakeupReasons_224553" 223 "WakeupReasons_652546" 224 "WakeupReasons_331194" 225 "WakeupReasons_667820" 226 "WakeupReasons_659350" 227 "WakeupReasons_101706" 228 "WakeupReasons_101725" 229 "WakeupReasons_101728" 230 "WakeupReasons_101727" 231 "WakeupReasons_166267" 232 "WakeupReasons_156440" 233 "WakeupReasons_95949" 234 "WakeupReasons_112799" 235 "WakeupReasons_146470" 236 "WakeupReasons_176748" 237 "WakeupReasons_223920" 238 "WakeupReasons_668531" 239 "WakeupReasons_670087" 240 "WakeupReasons_668529" 241 "WakeupReasons_45858" 242 "WakeupReasons_315981" 243 "WakeupReasons_533370" 244 "WakeupReasons_533371" 245 "WakeupReasons_533372" 246 "WakeupReasons_241902" 247 "WakeupReasons_359559" 248 "WakeupReasons_516327" 249 "WakeupReasons_533872" 250 "WakeupReasons_45856" 251 "WakeupReasons_45853" 252 "WakeupReasons_45854" 253 "WakeupReasons_45852" 254 "WakeupReasons_45851" 255 "WakeupReasons_45850" 256 "WakeupReasons_45849" 257 "WakeupReasons_636801" 258 "WakeupReasons_109466" 259 "WakeupReasons_109467" 260 "WakeupReasons_670345" 261 "WakeupReasons_NMPDUReceived" 262 "WakeupReasons_358832" 263 "WakeupReasons_200683" 264 "WakeupReasons_198452" 265 "WakeupReasons_185457" 266 "WakeupReasons_185490" 267 "WakeupReasons_4471" 268 "WakeupReasons_269034" 269 "WakeupReasons_215560" 270 "WakeupReasons_312881" 271 "WakeupReasons_269140" 272 "WakeupReasons_197653" 273 "WakeupReasons_337991" 274 "WakeupReasons_658188" 275 "WakeupReasons_674953" 276 "WakeupReasons_675064" 277 "WakeupReasons_674958" 278 "WakeupReasons_675494" 279 "WakeupReasons_675837" 280 "WakeupReasons_667879" 281 "WakeupReasons_667947" 282 "WakeupReasons_676265" 283 "WakeupReasons_669465" 284 "WakeupReasons_670928" 285 "WakeupReasons_669447" 286 "WakeupReasons_667922" 287 "WakeupReasons_670753" 288 "WakeupReasons_668395" 289 "WakeupReasons_668393" 290 "WakeupReasons_667850" 291 "WakeupReasons_667848" 292 "WakeupReasons_311279" 293 "WakeupReasons_182918" 294 "WakeupReasons_667988" 295 "WakeupReasons_532555" 296 "WakeupReasons_532556" 297 "WakeupReasons_113348" 298 "WakeupReasons_193474" 299 "WakeupReasons_667871" 300 "WakeupReasons_670966" 301 "WakeupReasons_667985" 302 "WakeupReasons_670354" 303 "WakeupReasons_46017" 304 "WakeupReasons_675742" 305 "WakeupReasons_106669" 306 "WakeupReasons_80609" 307 "WakeupReasons_199714" 308 "WakeupReasons_200090" 309 "WakeupReasons_139075" 310 "WakeupReasons_268983" 311 "WakeupReasons_265131" 312 "WakeupReasons_263473" 313 "WakeupReasons_45887" 314 "WakeupReasons_69678" 315 "WakeupReasons_69679" 316 "WakeupReasons_45897" 317 "WakeupReasons_45898" 318 "WakeupReasons_80608" 319 "WakeupReasons_45869" 320 "WakeupReasons_45870" 321 "WakeupReasons_45872" 322 "WakeupReasons_45875" 323 "WakeupReasons_45871" 324 "WakeupReasons_45876" 325 "WakeupReasons_667980" 326 "WakeupReasons_45877" 327 "WakeupReasons_667973" 328 "WakeupReasons_670962" 329 "WakeupReasons_45888" 330 "WakeupReasons_45890" 331 "WakeupReasons_667869" 332 "WakeupReasons_45846" 333 "WakeupReasons_45847" 334 "WakeupReasons_45848" 335 "WakeupReasons_262872" 336 "WakeupReasons_127924" 337 "WakeupReasons_127926" 338 "WakeupReasons_674223" 339 "WakeupReasons_667982" 340 "WakeupReasons_657121" 341 "WakeupReasons_265745" 342 "WakeupReasons_657120" 343 "WakeupReasons_675564" 344 "WakeupReasons_197644" 345 "WakeupReasons_264943" 346 "WakeupReasons_264697" 347 "WakeupReasons_69216" 348 "WakeupReasons_128671" 349 "WakeupReasons_356598" 350 "WakeupReasons_675745" 351 "WakeupReasons_667983" 352 "WakeupReasons_667987" 353 "WakeupReasons_75103" 354 "WakeupReasons_305818" 355 "WakeupReasons_670942" 356 "WakeupReasons_532932" 357 "WakeupReasons_532933" 358 "WakeupReasons_83199" 359 "WakeupReasons_45900" 360 "WakeupReasons_88458" 361 "WakeupReasons_329457" 362 "WakeupReasons_45902" 363 "WakeupReasons_224211" 364 "WakeupReasons_667981" 365 "WakeupReasons_667874" 366 "WakeupReasons_46020" 367 "WakeupReasons_667842" 368 "WakeupReasons_145161" 369 "WakeupReasons_233755" 370 "WakeupReasons_297056" 371 "WakeupReasons_264691" 372 "WakeupReasons_262871" 373 "WakeupReasons_264964" 374 "WakeupReasons_667872" 375 "WakeupReasons_45655" 376 "WakeupReasons_177214" 377 "WakeupReasons_671005" 378 "WakeupReasons_680712" 379 "WakeupReasons_669822" 380 "WakeupReasons_668523" 381 "WakeupReasons_680974" 382 "WakeupReasons_680975" 383 "WakeupReasons_681028" 384 "WakeupReasons_670462" 385 "WakeupReasons_681134" 386 "WakeupReasons_681031" 387 "WakeupReasons_681711" 388 "WakeupReasons_682034" 389 "WakeupReasons_674839" 390 "WakeupReasons_681915" 391 "WakeupReasons_682032" 392 "WakeupReasons_682037" 393 "WakeupReasons_682688" 394 "WakeupReasons_681789" 395 "WakeupReasons_682023" 396 "WakeupReasons_681023" 397 "WakeupReasons_676285" 398 "WakeupReasons_682077" 399 "WakeupReasons_682076" 400 "WakeupReasons_682078" 401 "WakeupReasons_682153" 402 "WakeupReasons_682155" 403 "WakeupReasons_682152" 404 "WakeupReasons_682154" 405 "WakeupReasons_682074";
VAL_ 530 LcmaLedStsPassSide 0 "YesNo1_Yes" 1 "YesNo1_No";
VAL_ 530 MirrFoldStsAtPass 0 "MirrFoldStsTyp_MirrFoldPosnUndefd" 1 "MirrFoldStsTyp_MirrNotFoldPosn" 2 "MirrFoldStsTyp_MirrFoldPosn" 3 "MirrFoldStsTyp_MirrMovgToNotFold" 4 "MirrFoldStsTyp_MirrMovgToFold";
VAL_ 530 WinPosnStsAtPass 0 "WinAndRoofAndCurtPosnTyp_PosnUkwn" 1 "WinAndRoofAndCurtPosnTyp_ClsFull" 2 "WinAndRoofAndCurtPosnTyp_PercOpen4" 3 "WinAndRoofAndCurtPosnTyp_PercOpen8" 4 "WinAndRoofAndCurtPosnTyp_PercOpen12" 5 "WinAndRoofAndCurtPosnTyp_PercOpen16" 6 "WinAndRoofAndCurtPosnTyp_PercOpen20" 7 "WinAndRoofAndCurtPosnTyp_PercOpen24" 8 "WinAndRoofAndCurtPosnTyp_PercOpen28" 9 "WinAndRoofAndCurtPosnTyp_PercOpen32" 10 "WinAndRoofAndCurtPosnTyp_PercOpen36" 11 "WinAndRoofAndCurtPosnTyp_PercOpen40" 12 "WinAndRoofAndCurtPosnTyp_PercOpen44" 13 "WinAndRoofAndCurtPosnTyp_PercOpen48" 14 "WinAndRoofAndCurtPosnTyp_PercOpen52" 15 "WinAndRoofAndCurtPosnTyp_PercOpen56" 16 "WinAndRoofAndCurtPosnTyp_PercOpen60" 17 "WinAndRoofAndCurtPosnTyp_PercOpen64" 18 "WinAndRoofAndCurtPosnTyp_PercOpen68" 19 "WinAndRoofAndCurtPosnTyp_PercOpen72" 20 "WinAndRoofAndCurtPosnTyp_PercOpen76" 21 "WinAndRoofAndCurtPosnTyp_PercOpen80" 22 "WinAndRoofAndCurtPosnTyp_PercOpen84" 23 "WinAndRoofAndCurtPosnTyp_PercOpen88" 24 "WinAndRoofAndCurtPosnTyp_PercOpen92" 25 "WinAndRoofAndCurtPosnTyp_PercOpen96" 26 "WinAndRoofAndCurtPosnTyp_OpenFull" 27 "WinAndRoofAndCurtPosnTyp_Resd1" 28 "WinAndRoofAndCurtPosnTyp_Resd2" 29 "WinAndRoofAndCurtPosnTyp_Resd3" 30 "WinAndRoofAndCurtPosnTyp_Resd4" 31 "WinAndRoofAndCurtPosnTyp_Movg";
VAL_ 530 WinPosnStsAtReRi 0 "WinAndRoofAndCurtPosnTyp_PosnUkwn" 1 "WinAndRoofAndCurtPosnTyp_ClsFull" 2 "WinAndRoofAndCurtPosnTyp_PercOpen4" 3 "WinAndRoofAndCurtPosnTyp_PercOpen8" 4 "WinAndRoofAndCurtPosnTyp_PercOpen12" 5 "WinAndRoofAndCurtPosnTyp_PercOpen16" 6 "WinAndRoofAndCurtPosnTyp_PercOpen20" 7 "WinAndRoofAndCurtPosnTyp_PercOpen24" 8 "WinAndRoofAndCurtPosnTyp_PercOpen28" 9 "WinAndRoofAndCurtPosnTyp_PercOpen32" 10 "WinAndRoofAndCurtPosnTyp_PercOpen36" 11 "WinAndRoofAndCurtPosnTyp_PercOpen40" 12 "WinAndRoofAndCurtPosnTyp_PercOpen44" 13 "WinAndRoofAndCurtPosnTyp_PercOpen48" 14 "WinAndRoofAndCurtPosnTyp_PercOpen52" 15 "WinAndRoofAndCurtPosnTyp_PercOpen56" 16 "WinAndRoofAndCurtPosnTyp_PercOpen60" 17 "WinAndRoofAndCurtPosnTyp_PercOpen64" 18 "WinAndRoofAndCurtPosnTyp_PercOpen68" 19 "WinAndRoofAndCurtPosnTyp_PercOpen72" 20 "WinAndRoofAndCurtPosnTyp_PercOpen76" 21 "WinAndRoofAndCurtPosnTyp_PercOpen80" 22 "WinAndRoofAndCurtPosnTyp_PercOpen84" 23 "WinAndRoofAndCurtPosnTyp_PercOpen88" 24 "WinAndRoofAndCurtPosnTyp_PercOpen92" 25 "WinAndRoofAndCurtPosnTyp_PercOpen96" 26 "WinAndRoofAndCurtPosnTyp_OpenFull" 27 "WinAndRoofAndCurtPosnTyp_Resd1" 28 "WinAndRoofAndCurtPosnTyp_Resd2" 29 "WinAndRoofAndCurtPosnTyp_Resd3" 30 "WinAndRoofAndCurtPosnTyp_Resd4" 31 "WinAndRoofAndCurtPosnTyp_Movg";
VAL_ 271 DoorPassLockSts 0 "LockSts2_LockStsUkwn" 1 "LockSts2_Unlckd" 2 "LockSts2_Lockd" 3 "LockSts2_SafeLockd";
VAL_ 271 DoorRiReLockSts 0 "LockSts2_LockStsUkwn" 1 "LockSts2_Unlckd" 2 "LockSts2_Lockd" 3 "LockSts2_SafeLockd";
VAL_ 271 PassSeatSnsrSts2 0 "OkNokDi_Ok" 1 "OkNokDi_NotOk" 2 "OkNokDi_Disabled" 3 "OkNokDi_Reserved";
VAL_ 271 PassSeatSts2 0 "OccptPresSt1_Undefd1" 1 "OccptPresSt1_OccptNotPrsnt" 2 "OccptPresSt1_OccptPrsnt" 3 "OccptPresSt1_Undefd2";
VAL_ 1349 VFCVectorZCUPVFCid0 0 "VFCOnOff_Off" 1 "VFCOnOff_On";
VAL_ 1349 VFCVectorZCUPVFCid1 0 "VFCOnOff_Off" 1 "VFCOnOff_On";
VAL_ 1349 VFCVectorZCUPVFCid10 0 "VFCOnOff_Off" 1 "VFCOnOff_On";
VAL_ 1349 VFCVectorZCUPVFCid11 0 "VFCOnOff_Off" 1 "VFCOnOff_On";
VAL_ 1349 VFCVectorZCUPVFCid12 0 "VFCOnOff_Off" 1 "VFCOnOff_On";
VAL_ 1349 VFCVectorZCUPVFCid13 0 "VFCOnOff_Off" 1 "VFCOnOff_On";
VAL_ 1349 VFCVectorZCUPVFCid14 0 "VFCOnOff_Off" 1 "VFCOnOff_On";
VAL_ 1349 VFCVectorZCUPVFCid15 0 "VFCOnOff_Off" 1 "VFCOnOff_On";
VAL_ 1349 VFCVectorZCUPVFCid16 0 "VFCOnOff_Off" 1 "VFCOnOff_On";
VAL_ 1349 VFCVectorZCUPVFCid17 0 "VFCOnOff_Off" 1 "VFCOnOff_On";
VAL_ 1349 VFCVectorZCUPVFCid18 0 "VFCOnOff_Off" 1 "VFCOnOff_On";
VAL_ 1349 VFCVectorZCUPVFCid19 0 "VFCOnOff_Off" 1 "VFCOnOff_On";
VAL_ 1349 VFCVectorZCUPVFCid2 0 "VFCOnOff_Off" 1 "VFCOnOff_On";
VAL_ 1349 VFCVectorZCUPVFCid20 0 "VFCOnOff_Off" 1 "VFCOnOff_On";
VAL_ 1349 VFCVectorZCUPVFCid21 0 "VFCOnOff_Off" 1 "VFCOnOff_On";
VAL_ 1349 VFCVectorZCUPVFCid22 0 "VFCOnOff_Off" 1 "VFCOnOff_On";
VAL_ 1349 VFCVectorZCUPVFCid23 0 "VFCOnOff_Off" 1 "VFCOnOff_On";
VAL_ 1349 VFCVectorZCUPVFCid24 0 "VFCOnOff_Off" 1 "VFCOnOff_On";
VAL_ 1349 VFCVectorZCUPVFCid25 0 "VFCOnOff_Off" 1 "VFCOnOff_On";
VAL_ 1349 VFCVectorZCUPVFCid26 0 "VFCOnOff_Off" 1 "VFCOnOff_On";
VAL_ 1349 VFCVectorZCUPVFCid27 0 "VFCOnOff_Off" 1 "VFCOnOff_On";
VAL_ 1349 VFCVectorZCUPVFCid28 0 "VFCOnOff_Off" 1 "VFCOnOff_On";
VAL_ 1349 VFCVectorZCUPVFCid29 0 "VFCOnOff_Off" 1 "VFCOnOff_On";
VAL_ 1349 VFCVectorZCUPVFCid3 0 "VFCOnOff_Off" 1 "VFCOnOff_On";
VAL_ 1349 VFCVectorZCUPVFCid30 0 "VFCOnOff_Off" 1 "VFCOnOff_On";
VAL_ 1349 VFCVectorZCUPVFCid31 0 "VFCOnOff_Off" 1 "VFCOnOff_On";
VAL_ 1349 VFCVectorZCUPVFCid32 0 "VFCOnOff_Off" 1 "VFCOnOff_On";
VAL_ 1349 VFCVectorZCUPVFCid33 0 "VFCOnOff_Off" 1 "VFCOnOff_On";
VAL_ 1349 VFCVectorZCUPVFCid34 0 "VFCOnOff_Off" 1 "VFCOnOff_On";
VAL_ 1349 VFCVectorZCUPVFCid35 0 "VFCOnOff_Off" 1 "VFCOnOff_On";
VAL_ 1349 VFCVectorZCUPVFCid36 0 "VFCOnOff_Off" 1 "VFCOnOff_On";
VAL_ 1349 VFCVectorZCUPVFCid37 0 "VFCOnOff_Off" 1 "VFCOnOff_On";
VAL_ 1349 VFCVectorZCUPVFCid38 0 "VFCOnOff_Off" 1 "VFCOnOff_On";
VAL_ 1349 VFCVectorZCUPVFCid39 0 "VFCOnOff_Off" 1 "VFCOnOff_On";
VAL_ 1349 VFCVectorZCUPVFCid4 0 "VFCOnOff_Off" 1 "VFCOnOff_On";
VAL_ 1349 VFCVectorZCUPVFCid40 0 "VFCOnOff_Off" 1 "VFCOnOff_On";
VAL_ 1349 VFCVectorZCUPVFCid41 0 "VFCOnOff_Off" 1 "VFCOnOff_On";
VAL_ 1349 VFCVectorZCUPVFCid42 0 "VFCOnOff_Off" 1 "VFCOnOff_On";
VAL_ 1349 VFCVectorZCUPVFCid43 0 "VFCOnOff_Off" 1 "VFCOnOff_On";
VAL_ 1349 VFCVectorZCUPVFCid44 0 "VFCOnOff_Off" 1 "VFCOnOff_On";
VAL_ 1349 VFCVectorZCUPVFCid45 0 "VFCOnOff_Off" 1 "VFCOnOff_On";
VAL_ 1349 VFCVectorZCUPVFCid46 0 "VFCOnOff_Off" 1 "VFCOnOff_On";
VAL_ 1349 VFCVectorZCUPVFCid47 0 "VFCOnOff_Off" 1 "VFCOnOff_On";
VAL_ 1349 VFCVectorZCUPVFCid48 0 "VFCOnOff_Off" 1 "VFCOnOff_On";
VAL_ 1349 VFCVectorZCUPVFCid49 0 "VFCOnOff_Off" 1 "VFCOnOff_On";
VAL_ 1349 VFCVectorZCUPVFCid5 0 "VFCOnOff_Off" 1 "VFCOnOff_On";
VAL_ 1349 VFCVectorZCUPVFCid50 0 "VFCOnOff_Off" 1 "VFCOnOff_On";
VAL_ 1349 VFCVectorZCUPVFCid51 0 "VFCOnOff_Off" 1 "VFCOnOff_On";
VAL_ 1349 VFCVectorZCUPVFCid52 0 "VFCOnOff_Off" 1 "VFCOnOff_On";
VAL_ 1349 VFCVectorZCUPVFCid53 0 "VFCOnOff_Off" 1 "VFCOnOff_On";
VAL_ 1349 VFCVectorZCUPVFCid54 0 "VFCOnOff_Off" 1 "VFCOnOff_On";
VAL_ 1349 VFCVectorZCUPVFCid55 0 "VFCOnOff_Off" 1 "VFCOnOff_On";
VAL_ 1349 VFCVectorZCUPVFCid56 0 "VFCOnOff_Off" 1 "VFCOnOff_On";
VAL_ 1349 VFCVectorZCUPVFCid57 0 "VFCOnOff_Off" 1 "VFCOnOff_On";
VAL_ 1349 VFCVectorZCUPVFCid58 0 "VFCOnOff_Off" 1 "VFCOnOff_On";
VAL_ 1349 VFCVectorZCUPVFCid59 0 "VFCOnOff_Off" 1 "VFCOnOff_On";
VAL_ 1349 VFCVectorZCUPVFCid6 0 "VFCOnOff_Off" 1 "VFCOnOff_On";
VAL_ 1349 VFCVectorZCUPVFCid60 0 "VFCOnOff_Off" 1 "VFCOnOff_On";
VAL_ 1349 VFCVectorZCUPVFCid61 0 "VFCOnOff_Off" 1 "VFCOnOff_On";
VAL_ 1349 VFCVectorZCUPVFCid7 0 "VFCOnOff_Off" 1 "VFCOnOff_On";
VAL_ 1349 VFCVectorZCUPVFCid8 0 "VFCOnOff_Off" 1 "VFCOnOff_On";
VAL_ 1349 VFCVectorZCUPVFCid9 0 "VFCOnOff_Off" 1 "VFCOnOff_On";
VAL_ 1285 WakeUpReasonsforZCUP 0 "WakeupReasons_667949" 1 "WakeupReasons_667950" 2 "WakeupReasons_169654" 3 "WakeupReasons_667951" 4 "WakeupReasons_168965" 5 "WakeupReasons_197643" 6 "WakeupReasons_264933" 7 "WakeupReasons_45654" 8 "WakeupReasons_22058" 9 "WakeupReasons_49446" 10 "WakeupReasons_22060" 11 "WakeupReasons_269740" 12 "WakeupReasons_269735" 13 "WakeupReasons_269739" 14 "WakeupReasons_658500" 15 "WakeupReasons_21901" 16 "WakeupReasons_45793" 17 "WakeupReasons_45794" 18 "WakeupReasons_22005" 19 "WakeupReasons_22013" 20 "WakeupReasons_22100" 21 "WakeupReasons_45659" 22 "WakeupReasons_45657" 23 "WakeupReasons_140084" 24 "WakeupReasons_21973" 25 "WakeupReasons_91253" 26 "WakeupReasons_88123" 27 "WakeupReasons_88125" 28 "WakeupReasons_321583" 29 "WakeupReasons_74188" 30 "WakeupReasons_667945" 31 "WakeupReasons_169655" 32 "WakeupReasons_667948" 33 "WakeupReasons_168966" 34 "WakeupReasons_170865" 35 "WakeupReasons_197642" 36 "WakeupReasons_264876" 37 "WakeupReasons_191050" 38 "WakeupReasons_182033" 39 "WakeupReasons_200937" 40 "WakeupReasons_170807" 41 "WakeupReasons_319139" 42 "WakeupReasons_100298" 43 "WakeupReasons_100275" 44 "WakeupReasons_100300" 45 "WakeupReasons_100278" 46 "WakeupReasons_100281" 47 "WakeupReasons_265333" 48 "WakeupReasons_108776" 49 "WakeupReasons_176921" 50 "WakeupReasons_197826" 51 "WakeupReasons_185670" 52 "WakeupReasons_161066" 53 "WakeupReasons_200156" 54 "WakeupReasons_225696" 55 "WakeupReasons_21997" 56 "WakeupReasons_45656" 57 "WakeupReasons_266860" 58 "WakeupReasons_169894" 59 "WakeupReasons_320282" 60 "WakeupReasons_319422" 61 "WakeupReasons_320277" 62 "WakeupReasons_355601" 63 "WakeupReasons_360904" 64 "WakeupReasons_361505" 65 "WakeupReasons_361509" 66 "WakeupReasons_645094" 67 "WakeupReasons_68676" 68 "WakeupReasons_360008" 69 "WakeupReasons_109382" 70 "WakeupReasons_119273" 71 "WakeupReasons_224065" 72 "WakeupReasons_68644" 73 "WakeupReasons_109364" 74 "WakeupReasons_68481" 75 "WakeupReasons_224061" 76 "WakeupReasons_360006" 77 "WakeupReasons_138997" 78 "WakeupReasons_634696" 79 "WakeupReasons_645810" 80 "WakeupReasons_297868" 81 "WakeupReasons_315364" 82 "WakeupReasons_109367" 83 "WakeupReasons_320126" 84 "WakeupReasons_109387" 85 "WakeupReasons_634710" 86 "WakeupReasons_338820" 87 "WakeupReasons_67182" 88 "WakeupReasons_152237" 89 "WakeupReasons_145707" 90 "WakeupReasons_199172" 91 "WakeupReasons_144897" 92 "WakeupReasons_186489" 93 "WakeupReasons_144970" 94 "WakeupReasons_152786" 95 "WakeupReasons_264932" 96 "WakeupReasons_264934" 97 "WakeupReasons_356190" 98 "WakeupReasons_145688" 99 "WakeupReasons_95444" 100 "WakeupReasons_169945" 101 "WakeupReasons_140678" 102 "WakeupReasons_222553" 103 "WakeupReasons_224831" 104 "WakeupReasons_201815" 105 "WakeupReasons_45864" 106 "WakeupReasons_659549" 107 "WakeupReasons_45866" 108 "WakeupReasons_45867" 109 "WakeupReasons_169884" 110 "WakeupReasons_264962" 111 "WakeupReasons_201348" 112 "WakeupReasons_320287" 113 "WakeupReasons_156412" 114 "WakeupReasons_133749" 115 "WakeupReasons_355409" 116 "WakeupReasons_636692" 117 "WakeupReasons_533044" 118 "WakeupReasons_106774" 119 "WakeupReasons_145311" 120 "WakeupReasons_145319" 121 "WakeupReasons_152774" 122 "WakeupReasons_145330" 123 "WakeupReasons_145388" 124 "WakeupReasons_145399" 125 "WakeupReasons_145362" 126 "WakeupReasons_145385" 127 "WakeupReasons_145373" 128 "WakeupReasons_145288" 129 "WakeupReasons_145419" 130 "WakeupReasons_145454" 131 "WakeupReasons_145462" 132 "WakeupReasons_269156" 133 "WakeupReasons_300427" 134 "WakeupReasons_220322" 135 "WakeupReasons_224617" 136 "WakeupReasons_224634" 137 "WakeupReasons_300682" 138 "WakeupReasons_264958" 139 "WakeupReasons_160597" 140 "WakeupReasons_160602" 141 "WakeupReasons_108841" 142 "WakeupReasons_265569" 143 "WakeupReasons_526429" 144 "WakeupReasons_514545" 145 "WakeupReasons_265232" 146 "WakeupReasons_644550" 147 "WakeupReasons_317616" 148 "WakeupReasons_354791" 149 "WakeupReasons_320631" 150 "WakeupReasons_337565" 151 "WakeupReasons_532007" 152 "WakeupReasons_514503" 153 "WakeupReasons_299117" 154 "WakeupReasons_340667" 155 "WakeupReasons_321845" 156 "WakeupReasons_179103" 157 "WakeupReasons_108810" 158 "WakeupReasons_322857" 159 "WakeupReasons_658603" 160 "WakeupReasons_197648" 161 "WakeupReasons_160596" 162 "WakeupReasons_361272" 163 "WakeupReasons_361279" 164 "WakeupReasons_265305" 165 "WakeupReasons_265328" 166 "WakeupReasons_265330" 167 "WakeupReasons_298808" 168 "WakeupReasons_515804" 169 "WakeupReasons_514502" 170 "WakeupReasons_645753" 171 "WakeupReasons_646109" 172 "WakeupReasons_299547" 173 "WakeupReasons_318342" 174 "WakeupReasons_360543" 175 "WakeupReasons_356549" 176 "WakeupReasons_198484" 177 "WakeupReasons_300681" 178 "WakeupReasons_359211" 179 "WakeupReasons_534077" 180 "WakeupReasons_525705" 181 "WakeupReasons_360299" 182 "WakeupReasons_526445" 183 "WakeupReasons_534145" 184 "WakeupReasons_192030" 185 "WakeupReasons_652361" 186 "WakeupReasons_355214" 187 "WakeupReasons_321317" 188 "WakeupReasons_359187" 189 "WakeupReasons_321057" 190 "WakeupReasons_321319" 191 "WakeupReasons_321323" 192 "WakeupReasons_321077" 193 "WakeupReasons_320895" 194 "WakeupReasons_655340" 195 "WakeupReasons_636556" 196 "WakeupReasons_108834" 197 "WakeupReasons_265937" 198 "WakeupReasons_533050" 199 "WakeupReasons_526426" 200 "WakeupReasons_264712" 201 "WakeupReasons_319401" 202 "WakeupReasons_643973" 203 "WakeupReasons_223715" 204 "WakeupReasons_199159" 205 "WakeupReasons_318382" 206 "WakeupReasons_226967" 207 "WakeupReasons_531743" 208 "WakeupReasons_360542" 209 "WakeupReasons_264726" 210 "WakeupReasons_535214" 211 "WakeupReasons_335068" 212 "WakeupReasons_316796" 213 "WakeupReasons_526438" 214 "WakeupReasons_198433" 215 "WakeupReasons_225961" 216 "WakeupReasons_197665" 217 "WakeupReasons_224550" 218 "WakeupReasons_667962" 219 "WakeupReasons_667953" 220 "WakeupReasons_110885" 221 "WakeupReasons_224552" 222 "WakeupReasons_224553" 223 "WakeupReasons_652546" 224 "WakeupReasons_331194" 225 "WakeupReasons_667820" 226 "WakeupReasons_659350" 227 "WakeupReasons_101706" 228 "WakeupReasons_101725" 229 "WakeupReasons_101728" 230 "WakeupReasons_101727" 231 "WakeupReasons_166267" 232 "WakeupReasons_156440" 233 "WakeupReasons_95949" 234 "WakeupReasons_112799" 235 "WakeupReasons_146470" 236 "WakeupReasons_176748" 237 "WakeupReasons_223920" 238 "WakeupReasons_668531" 239 "WakeupReasons_670087" 240 "WakeupReasons_668529" 241 "WakeupReasons_45858" 242 "WakeupReasons_315981" 243 "WakeupReasons_533370" 244 "WakeupReasons_533371" 245 "WakeupReasons_533372" 246 "WakeupReasons_241902" 247 "WakeupReasons_359559" 248 "WakeupReasons_516327" 249 "WakeupReasons_533872" 250 "WakeupReasons_45856" 251 "WakeupReasons_45853" 252 "WakeupReasons_45854" 253 "WakeupReasons_45852" 254 "WakeupReasons_45851" 255 "WakeupReasons_45850" 256 "WakeupReasons_45849" 257 "WakeupReasons_636801" 258 "WakeupReasons_109466" 259 "WakeupReasons_109467" 260 "WakeupReasons_670345" 261 "WakeupReasons_NMPDUReceived" 262 "WakeupReasons_358832" 263 "WakeupReasons_200683" 264 "WakeupReasons_198452" 265 "WakeupReasons_185457" 266 "WakeupReasons_185490" 267 "WakeupReasons_4471" 268 "WakeupReasons_269034" 269 "WakeupReasons_215560" 270 "WakeupReasons_312881" 271 "WakeupReasons_269140" 272 "WakeupReasons_197653" 273 "WakeupReasons_337991" 274 "WakeupReasons_658188" 275 "WakeupReasons_674953" 276 "WakeupReasons_675064" 277 "WakeupReasons_674958" 278 "WakeupReasons_675494" 279 "WakeupReasons_675837" 280 "WakeupReasons_667879" 281 "WakeupReasons_667947" 282 "WakeupReasons_676265" 283 "WakeupReasons_669465" 284 "WakeupReasons_670928" 285 "WakeupReasons_669447" 286 "WakeupReasons_667922" 287 "WakeupReasons_670753" 288 "WakeupReasons_668395" 289 "WakeupReasons_668393" 290 "WakeupReasons_667850" 291 "WakeupReasons_667848" 292 "WakeupReasons_311279" 293 "WakeupReasons_182918" 294 "WakeupReasons_667988" 295 "WakeupReasons_532555" 296 "WakeupReasons_532556" 297 "WakeupReasons_113348" 298 "WakeupReasons_193474" 299 "WakeupReasons_667871" 300 "WakeupReasons_670966" 301 "WakeupReasons_667985" 302 "WakeupReasons_670354" 303 "WakeupReasons_46017" 304 "WakeupReasons_675742" 305 "WakeupReasons_106669" 306 "WakeupReasons_80609" 307 "WakeupReasons_199714" 308 "WakeupReasons_200090" 309 "WakeupReasons_139075" 310 "WakeupReasons_268983" 311 "WakeupReasons_265131" 312 "WakeupReasons_263473" 313 "WakeupReasons_45887" 314 "WakeupReasons_69678" 315 "WakeupReasons_69679" 316 "WakeupReasons_45897" 317 "WakeupReasons_45898" 318 "WakeupReasons_80608" 319 "WakeupReasons_45869" 320 "WakeupReasons_45870" 321 "WakeupReasons_45872" 322 "WakeupReasons_45875" 323 "WakeupReasons_45871" 324 "WakeupReasons_45876" 325 "WakeupReasons_667980" 326 "WakeupReasons_45877" 327 "WakeupReasons_667973" 328 "WakeupReasons_670962" 329 "WakeupReasons_45888" 330 "WakeupReasons_45890" 331 "WakeupReasons_667869" 332 "WakeupReasons_45846" 333 "WakeupReasons_45847" 334 "WakeupReasons_45848" 335 "WakeupReasons_262872" 336 "WakeupReasons_127924" 337 "WakeupReasons_127926" 338 "WakeupReasons_674223" 339 "WakeupReasons_667982" 340 "WakeupReasons_657121" 341 "WakeupReasons_265745" 342 "WakeupReasons_657120" 343 "WakeupReasons_675564" 344 "WakeupReasons_197644" 345 "WakeupReasons_264943" 346 "WakeupReasons_264697" 347 "WakeupReasons_69216" 348 "WakeupReasons_128671" 349 "WakeupReasons_356598" 350 "WakeupReasons_675745" 351 "WakeupReasons_667983" 352 "WakeupReasons_667987" 353 "WakeupReasons_75103" 354 "WakeupReasons_305818" 355 "WakeupReasons_670942" 356 "WakeupReasons_532932" 357 "WakeupReasons_532933" 358 "WakeupReasons_83199" 359 "WakeupReasons_45900" 360 "WakeupReasons_88458" 361 "WakeupReasons_329457" 362 "WakeupReasons_45902" 363 "WakeupReasons_224211" 364 "WakeupReasons_667981" 365 "WakeupReasons_667874" 366 "WakeupReasons_46020" 367 "WakeupReasons_667842" 368 "WakeupReasons_145161" 369 "WakeupReasons_233755" 370 "WakeupReasons_297056" 371 "WakeupReasons_264691" 372 "WakeupReasons_262871" 373 "WakeupReasons_264964" 374 "WakeupReasons_667872" 375 "WakeupReasons_45655" 376 "WakeupReasons_177214" 377 "WakeupReasons_671005" 378 "WakeupReasons_680712" 379 "WakeupReasons_669822" 380 "WakeupReasons_668523" 381 "WakeupReasons_680974" 382 "WakeupReasons_680975" 383 "WakeupReasons_681028" 384 "WakeupReasons_670462" 385 "WakeupReasons_681134" 386 "WakeupReasons_681031" 387 "WakeupReasons_681711" 388 "WakeupReasons_682034" 389 "WakeupReasons_674839" 390 "WakeupReasons_681915" 391 "WakeupReasons_682032" 392 "WakeupReasons_682037" 393 "WakeupReasons_682688" 394 "WakeupReasons_681789" 395 "WakeupReasons_682023" 396 "WakeupReasons_681023" 397 "WakeupReasons_676285" 398 "WakeupReasons_682077" 399 "WakeupReasons_682076" 400 "WakeupReasons_682078" 401 "WakeupReasons_682153" 402 "WakeupReasons_682155" 403 "WakeupReasons_682152" 404 "WakeupReasons_682154" 405 "WakeupReasons_682074";
SIG_GROUP_ 83 AccrPedlRat 1 : AccrPedlRatAccrPedlRat AccrPedlRatChks AccrPedlRatCntr;
SIG_GROUP_ 97 ADataRawSafe 1 : ADataRawSafeALat ADataRawSafeALat1Qf ADataRawSafeALgt ADataRawSafeALgt1Qf ADataRawSafeAVert ADataRawSafeAVertQf ADataRawSafeChks ADataRawSafeCntr;
SIG_GROUP_ 97 ADModCtrlInhbn 1 : ADModCtrlInhbnADModCtrlInhbn ADModCtrlInhbnChks ADModCtrlInhbnCntr;
SIG_GROUP_ 97 AgDataRaw2Safe 1 : AgDataRaw2SafeChks AgDataRaw2SafeCntr AgDataRaw2SafePitchRate AgDataRaw2SafePitchRateQf;
SIG_GROUP_ 97 AgDataRawSafe 1 : AgDataRawSafeChks AgDataRawSafeCntr AgDataRawSafeRollRate AgDataRawSafeRollRateQf AgDataRawSafeYawRate AgDataRawSafeYawRateQf;
SIG_GROUP_ 261 AlrmSts 1 : AlrmStsAlrmFailr AlrmStsAlrmSt AlrmStsAlrmTrgSrc AlrmStsSnsrInclnFailr AlrmStsSnsrIntrScanrFailr;
SIG_GROUP_ 97 AmbTRaw 1 : AmbTRawAmbTVal AmbTRawQly;
SIG_GROUP_ 97 AsyDataWithCmpSafe 1 : AsyDataWithCmpSafeALat1Qf AsyDataWithCmpSafeALatWithCmp AsyDataWithCmpSafeALgt1Qf AsyDataWithCmpSafeChks AsyDataWithCmpSafeCntr AsyDataWithCmpSafeGrdtOfALgt AsyDataWithCmpSafeYawRateQf AsyDataWithCmpSafeYawRateWithCmp;
SIG_GROUP_ 83 BltLockStAtDrvr 1 : BltLockStAtDrvrBltLockSt1 BltLockStAtDrvrBltLockSts;
SIG_GROUP_ 545 BltLockStAtPass 1 : BltLockStAtPassBltLockSt1 BltLockStAtPassBltLockSts;
SIG_GROUP_ 851 BltLockStAtRowSecLe 1 : BltLockStAtRowSecLeBltLockEquid BltLockStAtRowSecLeBltLockSt1 BltLockStAtRowSecLeBltLockSts;
SIG_GROUP_ 851 BltLockStAtRowSecMid 1 : BltLockStAtRowSecMidBltLockEquid BltLockStAtRowSecMidBltLockSt1 BltLockStAtRowSecMidBltLockSts;
SIG_GROUP_ 851 BltLockStAtRowSecRi 1 : BltLockStAtRowSecRiBltLockEquid BltLockStAtRowSecRiBltLockSt1 BltLockStAtRowSecRiBltLockSts;
SIG_GROUP_ 851 BltLockStAtRowThrdLe 1 : BltLockStAtRowThrdLeBltLockEquid BltLockStAtRowThrdLeBltLockSt1 BltLockStAtRowThrdLeBltLockSts;
SIG_GROUP_ 851 BltLockStAtRowThrdRi 1 : BltLockStAtRowThrdRiBltLockEquid BltLockStAtRowThrdRiBltLockSt1 BltLockStAtRowThrdRiBltLockSts;
SIG_GROUP_ 261 BltLockStSafeAtDrvr 1 : BltLockStSafeAtDrvrBltLockSt1 BltLockStSafeAtDrvrBltLockStErrSts BltLockStSafeAtDrvrChks BltLockStSafeAtDrvrCntr;
SIG_GROUP_ 97 BrkPedlSnsr 1 : BrkPedlSnsrChks BrkPedlSnsrCntr BrkPedlSnsrQf BrkPedlSnsrSt;
SIG_GROUP_ 261 BrkPedlVal 1 : BrkPedlValBrkPedlVal BrkPedlValQf;
SIG_GROUP_ 851 BtnLockSts1 1 : BtnLockSts1BtnSts2 BtnLockSts1KeyId;
SIG_GROUP_ 851 BtnTrSts1 1 : BtnTrSts1BtnSts2 BtnTrSts1KeyId;
SIG_GROUP_ 851 BtnUnlckSts1 1 : BtnUnlckSts1BtnSts2 BtnUnlckSts1KeyId;
SIG_GROUP_ 97 DmcStsRearToEsc 1 : DmcStsRearToEscChks DmcStsRearToEscCntr DmcStsRearToEscDmcActAppTarTq DmcStsRearToEscDmcSts DmcStsRearToEscDmcSWInfo;
SIG_GROUP_ 261 DoorDrvrStsWithFacQly 1 : DoorDrvrStsWithFacQlyDoorSts DoorDrvrStsWithFacQlyFacQly;
SIG_GROUP_ 97 DrvrDesDir 1 : DrvrDesDirChks DrvrDesDirCntr DrvrDesDirDrvrDesDir;
SIG_GROUP_ 97 DrvrGearShiftDirReq1 1 : DrvrGearShiftDirReq1Chks DrvrGearShiftDirReq1Cntr DrvrGearShiftDirReq1DwnDwnTipAut DrvrGearShiftDirReq1DwnTipAut DrvrGearShiftDirReq1PosnAut DrvrGearShiftDirReq1UpTipAut DrvrGearShiftDirReq1UpUpTipAut;
SIG_GROUP_ 97 DrvrGearShiftDirReq2 1 : DrvrGearShiftDirReq2Chks DrvrGearShiftDirReq2Cntr DrvrGearShiftDirReq2DwnDwnTipAut DrvrGearShiftDirReq2DwnTipAut DrvrGearShiftDirReq2PosnAut DrvrGearShiftDirReq2UpTipAut DrvrGearShiftDirReq2UpUpTipAut;
SIG_GROUP_ 83 DrvrGearShiftParkReq 1 : DrvrGearShiftParkReq1 DrvrGearShiftParkReqChks DrvrGearShiftParkReqCntr DrvrGearShiftParkReqSts;
SIG_GROUP_ 261 DrvrPrsntSts 1 : DrvrPrsntStsDrvrPrsnt DrvrPrsntStsDrvrPrsntChks DrvrPrsntStsDrvrPrsntCntr DrvrPrsntStsDrvrPrsntQf;
SIG_GROUP_ 83 EngSt1WdSts 1 : EngSt1WdStsChks EngSt1WdStsCntr EngSt1WdStsEngSt1WdSts;
SIG_GROUP_ 451 EngT 1 : EngTEngT EngTQf;
SIG_GROUP_ 837 EPBLockMgrReq 1 : EPBLockMgrReqCmd EPBLockMgrReqData0 EPBLockMgrReqData1 EPBLockMgrReqData2 EPBLockMgrReqData3 EPBLockMgrReqData4 EPBLockMgrReqData5 EPBLockMgrReqData6;
SIG_GROUP_ 451 ExtrLtgSts 1 : ExtrLtgStsAFS ExtrLtgStsAHBC ExtrLtgStsAHL ExtrLtgStsAllWL ExtrLtgStsApproach ExtrLtgStsChks ExtrLtgStsCntr ExtrLtgStsCornrgLi ExtrLtgStsDBL ExtrLtgStsDRL ExtrLtgStsFlash ExtrLtgStsFrntFog ExtrLtgStsGoodbye ExtrLtgStsHiBeam ExtrLtgStsHomeSafe ExtrLtgStsHWL ExtrLtgStsLoBeam ExtrLtgStsLtgShow ExtrLtgStsPosLiFrnt ExtrLtgStsPosLiRe ExtrLtgStsReFog ExtrLtgStsReverseLi ExtrLtgStsStopLi ExtrLtgStsTurnIndrLe ExtrLtgStsTurnIndrRi ExtrLtgStsWelcome;
SIG_GROUP_ 867 JID 1 : JIDByte0 JIDByte1 JIDByte2 JIDByte3 JIDByte4 JIDByte5 JIDByte6 JIDByte7;
SIG_GROUP_ 545 KeyDistncSts 1 : KeyDistncStsKey0 KeyDistncStsKey1 KeyDistncStsKey2 KeyDistncStsKey3 KeyDistncStsKey4 KeyDistncStsKey5;
SIG_GROUP_ 579 LeFrntTireMsg 1 : LeFrntTireMsgBattLoSt LeFrntTireMsgFastLoseWarnFlg LeFrntTireMsgMsgOldFlg LeFrntTireMsgP LeFrntTireMsgPWarnFlg LeFrntTireMsgSysWarnFlg LeFrntTireMsgT LeFrntTireMsgTireFillgAssiPSts LeFrntTireMsgTWarnFlg;
SIG_GROUP_ 579 LeReTireMsg 1 : LeReTireMsgBattLoSt LeReTireMsgFastLoseWarnFlg LeReTireMsgMsgOldFlg LeReTireMsgP LeReTireMsgPWarnFlg LeReTireMsgSysWarnFlg LeReTireMsgT LeReTireMsgTireFillgAssiPSts LeReTireMsgTWarnFlg;
SIG_GROUP_ 261 LockgCenSts 1 : LockgCenStsLockSt LockgCenStsTrigSrc LockgCenStsUpdEve;
SIG_GROUP_ 83 PinionSteerAgGroup 1 : PinionSteerAgGroupChks PinionSteerAgGroupCntr PinionSteerAgGroupPinionSteerAg1 PinionSteerAgGroupPinionSteerAg1Qf PinionSteerAgGroupPinionSteerAgSpd1 PinionSteerAgGroupPinionSteerAgSpd1Qf PinionSteerAgGroupSteerWhlTq PinionSteerAgGroupSteerWhlTqQf;
SIG_GROUP_ 261 PtBrkTq 1 : PtBrkTqActTot PtBrkTqActTotQf PtBrkTqChks PtBrkTqCntr PtBrkTqQf PtBrkTqReqForBrkSys PtBrkTqRgnAtAxleReAct;
SIG_GROUP_ 261 RecOfPostImpctBrkgCfmd 1 : RecOfPostImpctBrkgCfmdChks RecOfPostImpctBrkgCfmdCntr RecOfPostImpctBrkgCfmdCrashFrnt RecOfPostImpctBrkgCfmdCrashLargeAnimal RecOfPostImpctBrkgCfmdCrashOffroadA RecOfPostImpctBrkgCfmdCrashOffroadD RecOfPostImpctBrkgCfmdCrashOffroadRT RecOfPostImpctBrkgCfmdCrashOffroadRTsevere RecOfPostImpctBrkgCfmdCrashOz RecOfPostImpctBrkgCfmdCrashPed RecOfPostImpctBrkgCfmdCrashRe RecOfPostImpctBrkgCfmdCrashRollovr RecOfPostImpctBrkgCfmdCrashSideLe RecOfPostImpctBrkgCfmdCrashSideRi RecOfPostImpctBrkgCfmdPostImpctBrkgCfmd;
SIG_GROUP_ 83 RecOfPostImpctBrkgSuspc 1 : RecOfPostImpctBrkgSuspcChks RecOfPostImpctBrkgSuspcCntr RecOfPostImpctBrkgSuspcSuspcPostImpctBrkg;
SIG_GROUP_ 579 RiFrntTireMsg 1 : RiFrntTireMsgBattLoSt RiFrntTireMsgFastLoseWarnFlg RiFrntTireMsgMsgOldFlg RiFrntTireMsgP RiFrntTireMsgPWarnFlg RiFrntTireMsgSysWarnFlg RiFrntTireMsgT RiFrntTireMsgTireFillgAssiPSts RiFrntTireMsgTWarnFlg;
SIG_GROUP_ 579 RiReTireMsg 1 : RiReTireMsgBattLoSt RiReTireMsgFastLoseWarnFlg RiReTireMsgMsgOldFlg RiReTireMsgP RiReTireMsgPWarnFlg RiReTireMsgSysWarnFlg RiReTireMsgT RiReTireMsgTireFillgAssiPSts RiReTireMsgTWarnFlg;
SIG_GROUP_ 451 SteerWhlPosn 1 : SteerWhlPosnAng SteerWhlPosnX;
SIG_GROUP_ 83 SuspPosnVertLe1 1 : SuspPosnVertLe1Chks SuspPosnVertLe1Frnt SuspPosnVertLe1FrntQf SuspPosnVertLe1Re SuspPosnVertLe1ReQf;
SIG_GROUP_ 83 SuspPosnVertRi1 1 : SuspPosnVertRi1SuspPosnVertRiChks SuspPosnVertRi1SuspPosnVertRiFrnt SuspPosnVertRi1SuspPosnVertRiFrntQf SuspPosnVertRi1SuspPosnVertRiRe SuspPosnVertRi1SuspPosnVertRiReQf;
SIG_GROUP_ 451 SwtIndcr 1 : SwtIndcrIndcrTypExtReq SwtIndcrIndcrTypExtReqChks SwtIndcrIndcrTypExtReqCntr SwtIndcrIndcrTypExtReqToUpdQf;
SIG_GROUP_ 837 TiAndDateIndcn 1 : TiAndDateIndcnDataValid TiAndDateIndcnDay TiAndDateIndcnHr1 TiAndDateIndcnMins1 TiAndDateIndcnMth1 TiAndDateIndcnSec1 TiAndDateIndcnYr1;
SIG_GROUP_ 261 TrsmParkLockd 1 : TrsmParkLockdChks TrsmParkLockdCntr TrsmParkLockdTrsmParkLockd;
SIG_GROUP_ 451 TurnIndcrMonostable 1 : TurnIndcrMonostableChks TurnIndcrMonostableCntr TurnIndcrMonostableQf TurnIndcrMonostableTurnIndcrMonostable;
SIG_GROUP_ 451 TwliBriRaw 1 : TwliBriRawQf TwliBriRawTwliBriRaw;
SIG_GROUP_ 851 ULoWarn 1 : ULoWarnChks ULoWarnCntr ULoWarnULoWarn;
SIG_GROUP_ 931 VehBattU 1 : VehBattUSysU VehBattUSysUQf;
SIG_GROUP_ 83 VehModMngtGlbSafe1 1 : VehModMngtGlbSafe1CarModSts1 VehModMngtGlbSafe1CarModSubtypWdCarModSubtyp VehModMngtGlbSafe1Chks VehModMngtGlbSafe1Cntr VehModMngtGlbSafe1EgyLvlElecMai VehModMngtGlbSafe1EgyLvlElecSubtyp VehModMngtGlbSafe1FltEgyCnsWdSts VehModMngtGlbSafe1PwrLvlElecMai VehModMngtGlbSafe1PwrLvlElecSubtyp VehModMngtGlbSafe1UsgModSts;
SIG_GROUP_ 83 VehTiAndData 1 : VehTiAndDataDataValid VehTiAndDataDay VehTiAndDataHr1 VehTiAndDataMins1 VehTiAndDataMth1 VehTiAndDataSec1 VehTiAndDataYr1;
SIG_GROUP_ 1347 VFCVectorZCUDM 1 : VFCVectorZCUDMBlockID VFCVectorZCUDMVFCid0 VFCVectorZCUDMVFCid1 VFCVectorZCUDMVFCid10 VFCVectorZCUDMVFCid11 VFCVectorZCUDMVFCid12 VFCVectorZCUDMVFCid13 VFCVectorZCUDMVFCid14 VFCVectorZCUDMVFCid15 VFCVectorZCUDMVFCid16 VFCVectorZCUDMVFCid17 VFCVectorZCUDMVFCid18 VFCVectorZCUDMVFCid19 VFCVectorZCUDMVFCid2 VFCVectorZCUDMVFCid20 VFCVectorZCUDMVFCid21 VFCVectorZCUDMVFCid22 VFCVectorZCUDMVFCid23 VFCVectorZCUDMVFCid24 VFCVectorZCUDMVFCid25 VFCVectorZCUDMVFCid26 VFCVectorZCUDMVFCid27 VFCVectorZCUDMVFCid28 VFCVectorZCUDMVFCid29 VFCVectorZCUDMVFCid3 VFCVectorZCUDMVFCid30 VFCVectorZCUDMVFCid31 VFCVectorZCUDMVFCid32 VFCVectorZCUDMVFCid33 VFCVectorZCUDMVFCid34 VFCVectorZCUDMVFCid35 VFCVectorZCUDMVFCid36 VFCVectorZCUDMVFCid37 VFCVectorZCUDMVFCid38 VFCVectorZCUDMVFCid39 VFCVectorZCUDMVFCid4 VFCVectorZCUDMVFCid40 VFCVectorZCUDMVFCid41 VFCVectorZCUDMVFCid42 VFCVectorZCUDMVFCid43 VFCVectorZCUDMVFCid44 VFCVectorZCUDMVFCid45 VFCVectorZCUDMVFCid46 VFCVectorZCUDMVFCid47 VFCVectorZCUDMVFCid48 VFCVectorZCUDMVFCid49 VFCVectorZCUDMVFCid5 VFCVectorZCUDMVFCid50 VFCVectorZCUDMVFCid51 VFCVectorZCUDMVFCid52 VFCVectorZCUDMVFCid53 VFCVectorZCUDMVFCid54 VFCVectorZCUDMVFCid55 VFCVectorZCUDMVFCid56 VFCVectorZCUDMVFCid57 VFCVectorZCUDMVFCid58 VFCVectorZCUDMVFCid59 VFCVectorZCUDMVFCid6 VFCVectorZCUDMVFCid60 VFCVectorZCUDMVFCid61 VFCVectorZCUDMVFCid7 VFCVectorZCUDMVFCid8 VFCVectorZCUDMVFCid9;
SIG_GROUP_ 1349 VFCVectorZCUP 1 : VFCVectorZCUPBlockID VFCVectorZCUPVFCid0 VFCVectorZCUPVFCid1 VFCVectorZCUPVFCid10 VFCVectorZCUPVFCid11 VFCVectorZCUPVFCid12 VFCVectorZCUPVFCid13 VFCVectorZCUPVFCid14 VFCVectorZCUPVFCid15 VFCVectorZCUPVFCid16 VFCVectorZCUPVFCid17 VFCVectorZCUPVFCid18 VFCVectorZCUPVFCid19 VFCVectorZCUPVFCid2 VFCVectorZCUPVFCid20 VFCVectorZCUPVFCid21 VFCVectorZCUPVFCid22 VFCVectorZCUPVFCid23 VFCVectorZCUPVFCid24 VFCVectorZCUPVFCid25 VFCVectorZCUPVFCid26 VFCVectorZCUPVFCid27 VFCVectorZCUPVFCid28 VFCVectorZCUPVFCid29 VFCVectorZCUPVFCid3 VFCVectorZCUPVFCid30 VFCVectorZCUPVFCid31 VFCVectorZCUPVFCid32 VFCVectorZCUPVFCid33 VFCVectorZCUPVFCid34 VFCVectorZCUPVFCid35 VFCVectorZCUPVFCid36 VFCVectorZCUPVFCid37 VFCVectorZCUPVFCid38 VFCVectorZCUPVFCid39 VFCVectorZCUPVFCid4 VFCVectorZCUPVFCid40 VFCVectorZCUPVFCid41 VFCVectorZCUPVFCid42 VFCVectorZCUPVFCid43 VFCVectorZCUPVFCid44 VFCVectorZCUPVFCid45 VFCVectorZCUPVFCid46 VFCVectorZCUPVFCid47 VFCVectorZCUPVFCid48 VFCVectorZCUPVFCid49 VFCVectorZCUPVFCid5 VFCVectorZCUPVFCid50 VFCVectorZCUPVFCid51 VFCVectorZCUPVFCid52 VFCVectorZCUPVFCid53 VFCVectorZCUPVFCid54 VFCVectorZCUPVFCid55 VFCVectorZCUPVFCid56 VFCVectorZCUPVFCid57 VFCVectorZCUPVFCid58 VFCVectorZCUPVFCid59 VFCVectorZCUPVFCid6 VFCVectorZCUPVFCid60 VFCVectorZCUPVFCid61 VFCVectorZCUPVFCid7 VFCVectorZCUPVFCid8 VFCVectorZCUPVFCid9;
SIG_GROUP_ 97 WhlMotSysTqEst 1 : WhlMotSysTqEstChks WhlMotSysTqEstCntr WhlMotSysTqEstIsgTqAct WhlMotSysTqEstQualityFactor;
SIG_GROUP_ 451 WipgInfo 1 : WipgInfoWipgSpdInfo WipgInfoWiprActv WipgInfoWiprInWipgAr;
